VERSION ""

NS_ :

BS_:

BU_: Engine2 Aftertreatment_1_GasOutlet BrakesSystemController Transmission1 Engine1

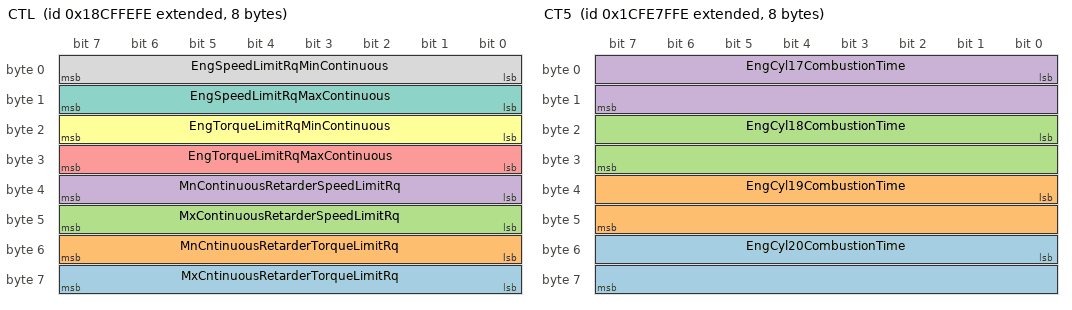
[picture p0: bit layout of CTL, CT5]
BO_ 2563768062 CTL: 8 Vector__XXX
 SG_ MxCntinuousRetarderTorqueLimitRq : 56|8@1+ (1,-125) [-125|0] "%" Vector__XXX
 SG_ MnCntinuousRetarderTorqueLimitRq : 48|8@1+ (1,-125) [-125|0] "%" Vector__XXX
 SG_ MxContinuousRetarderSpeedLimitRq : 40|8@1+ (32,0) [0|8000] "rpm" Vector__XXX
 SG_ MnContinuousRetarderSpeedLimitRq : 32|8@1+ (32,0) [0|8000] "rpm" Vector__XXX
 SG_ EngTorqueLimitRqMaxContinuous : 24|8@1+ (1,-125) [0|125] "%" Vector__XXX
 SG_ EngTorqueLimitRqMinContinuous : 16|8@1+ (1,-125) [0|125] "%" Vector__XXX
 SG_ EngSpeedLimitRqMaxContinuous : 8|8@1+ (32,0) [0|8000] "rpm" Vector__XXX
 SG_ EngSpeedLimitRqMinContinuous : 0|8@1+ (32,0) [0|8000] "rpm" Vector__XXX

BO_ 2633924862 CT6: 8 Vector__XXX
 SG_ EngAverageCombustionTime : 16|16@1+ (0.01,0) [0|642.55] "ms" Vector__XXX
 SG_ EngDesiredCombustionTime : 0|16@1+ (0.01,0) [0|642.55] "ms" Vector__XXX

BO_ 2633924606 CT5: 8 Vector__XXX
 SG_ EngCyl20CombustionTime : 48|16@1+ (0.01,0) [0|642.55] "ms" Vector__XXX
 SG_ EngCyl19CombustionTime : 32|16@1+ (0.01,0) [0|642.55] "ms" Vector__XXX
 SG_ EngCyl18CombustionTime : 16|16@1+ (0.01,0) [0|642.55] "ms" Vector__XXX
 SG_ EngCyl17CombustionTime : 0|16@1+ (0.01,0) [0|642.55] "ms" Vector__XXX

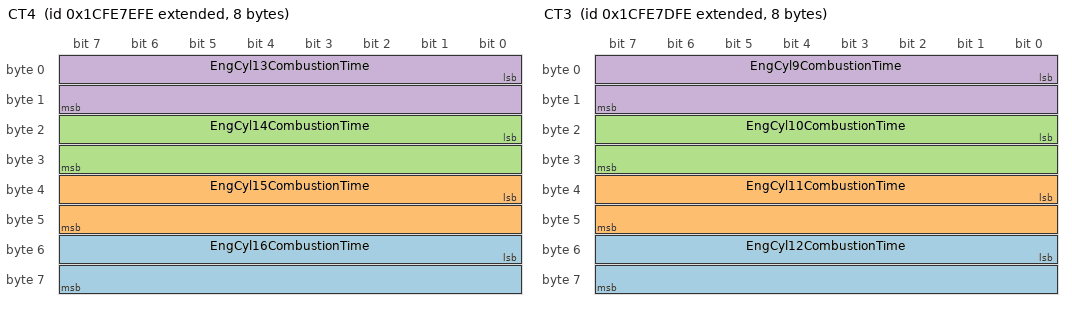
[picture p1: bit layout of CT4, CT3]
BO_ 2633924350 CT4: 8 Vector__XXX
 SG_ EngCyl16CombustionTime : 48|16@1+ (0.01,0) [0|642.55] "ms" Vector__XXX
 SG_ EngCyl15CombustionTime : 32|16@1+ (0.01,0) [0|642.55] "ms" Vector__XXX
 SG_ EngCyl14CombustionTime : 16|16@1+ (0.01,0) [0|642.55] "ms" Vector__XXX
 SG_ EngCyl13CombustionTime : 0|16@1+ (0.01,0) [0|642.55] "ms" Vector__XXX

BO_ 2633924094 CT3: 8 Vector__XXX
 SG_ EngCyl12CombustionTime : 48|16@1+ (0.01,0) [0|642.55] "ms" Vector__XXX
 SG_ EngCyl11CombustionTime : 32|16@1+ (0.01,0) [0|642.55] "ms" Vector__XXX
 SG_ EngCyl10CombustionTime : 16|16@1+ (0.01,0) [0|642.55] "ms" Vector__XXX
 SG_ EngCyl9CombustionTime : 0|16@1+ (0.01,0) [0|642.55] "ms" Vector__XXX

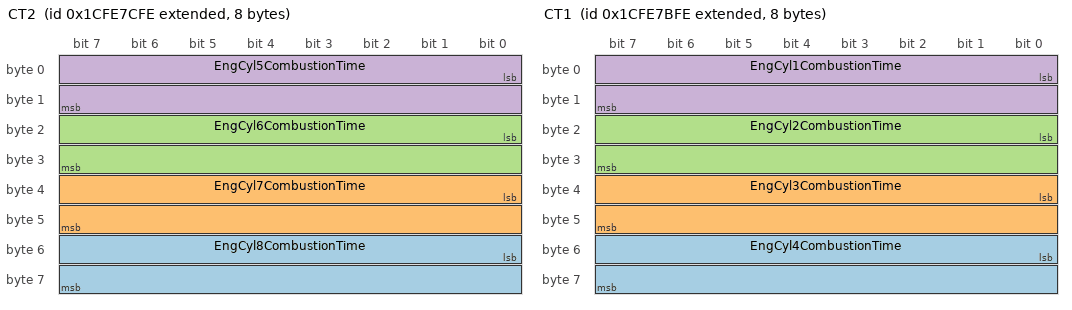
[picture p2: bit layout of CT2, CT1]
BO_ 2633923838 CT2: 8 Vector__XXX
 SG_ EngCyl8CombustionTime : 48|16@1+ (0.01,0) [0|642.55] "ms" Vector__XXX
 SG_ EngCyl7CombustionTime : 32|16@1+ (0.01,0) [0|642.55] "ms" Vector__XXX
 SG_ EngCyl6CombustionTime : 16|16@1+ (0.01,0) [0|642.55] "ms" Vector__XXX
 SG_ EngCyl5CombustionTime : 0|16@1+ (0.01,0) [0|642.55] "ms" Vector__XXX

BO_ 2633923582 CT1: 8 Vector__XXX
 SG_ EngCyl4CombustionTime : 48|16@1+ (0.01,0) [0|642.55] "ms" Vector__XXX
 SG_ EngCyl3CombustionTime : 32|16@1+ (0.01,0) [0|642.55] "ms" Vector__XXX
 SG_ EngCyl2CombustionTime : 16|16@1+ (0.01,0) [0|642.55] "ms" Vector__XXX
 SG_ EngCyl1CombustionTime : 0|16@1+ (0.01,0) [0|642.55] "ms" Vector__XXX

BO_ 2633878014 CMI: 8 Vector__XXX
 SG_ TotalCountOfConfigChangesMade : 0|16@1+ (1,0) [0|64255] "" Vector__XXX

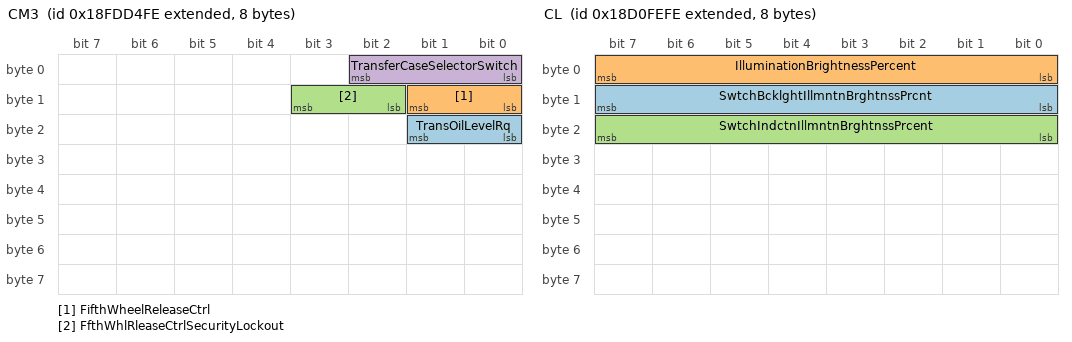
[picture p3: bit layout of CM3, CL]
BO_ 2566771966 CM3: 8 Vector__XXX
 SG_ TransOilLevelRq : 16|2@1+ (1,0) [0|3] "" Vector__XXX
 SG_ FifthWheelReleaseCtrl : 8|2@1+ (1,0) [0|3] "" Vector__XXX
 SG_ FfthWhlRleaseCtrlSecurityLockout : 10|2@1+ (1,0) [0|3] "" Vector__XXX
 SG_ TransferCaseSelectorSwitch : 0|3@1+ (1,0) [0|7] "" Vector__XXX

BO_ 2564882174 CM1: 8 Vector__XXX
 SG_ SelectedMaxVehicleSpeedLimit : 56|8@1+ (1,0) [0|250] "" Vector__XXX
 SG_ RqCabZoneHeating : 54|2@1+ (1,0) [0|3] "" Vector__XXX
 SG_ RqEngZoneHeating : 52|2@1+ (1,0) [0|3] "" Vector__XXX
 SG_ AuxHeaterModeRq : 48|4@1+ (1,0) [0|15] "" Vector__XXX
 SG_ EngAutomaticStartEnableSwitch : 46|2@1+ (1,0) [0|3] "" Vector__XXX
 SG_ AtomaticGearShiftingEnableSwitch : 44|2@1+ (1,0) [0|3] "" Vector__XXX
 SG_ ATRegenerationForceSwitch : 42|2@1+ (1,0) [0|3] "" Vector__XXX
 SG_ ATRegenerationInhibitSwitch : 40|2@1+ (1,0) [0|3] "" Vector__XXX
 SG_ VhclLmtngSpdGovernorEnableSwitch : 38|2@1+ (1,0) [0|3] "" Vector__XXX
 SG_ VhclLmtngSpdGvrnrIncrementSwitch : 36|2@1+ (1,0) [0|3] "" Vector__XXX
 SG_ VhclLmtngSpdGvrnrDecrementSwitch : 34|2@1+ (1,0) [0|3] "" Vector__XXX
 SG_ ParkBrakeCmd : 32|2@1+ (1,0) [0|3] "" Vector__XXX
 SG_ SeatBeltSwitch : 30|2@1+ (1,0) [0|3] "" Vector__XXX
 SG_ OperatorSeatDirectionSwitch : 28|2@1+ (1,0) [0|3] "" Vector__XXX
 SG_ BatteryMainSwitchHoldRq : 26|2@1+ (1,0) [0|3] "" Vector__XXX
 SG_ AuxHeaterCoolantPumpRq : 24|2@1+ (1,0) [0|3] "" Vector__XXX
 SG_ CabInteriorTempCmd : 8|16@1+ (0.03125,-273) [-273|1734.96875] "°C" Vector__XXX
 SG_ RequestedPercentFanSpeed : 0|8@1+ (0.4,0) [0|100] "%" Vector__XXX

BO_ 2563833598 CL: 8 Vector__XXX
 SG_ SwtchBcklghtIllmntnBrghtnssPrcnt : 8|8@1+ (0.4,0) [0|100] "%" Vector__XXX
 SG_ IlluminationBrightnessPercent : 0|8@1+ (0.4,0) [0|100] "%" Vector__XXX
 SG_ SwtchIndctnIllmntnBrghtnssPrcent : 16|8@1+ (0.4,0) [0|100] "%" Vector__XXX

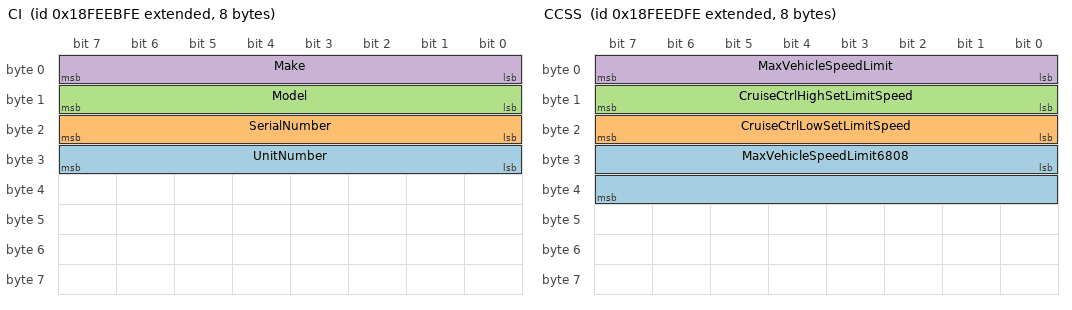
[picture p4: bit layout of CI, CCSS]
BO_ 2566843390 CI: 8 Vector__XXX
 SG_ UnitNumber : 24|8@1+ (1,0) [0|255] "" Vector__XXX
 SG_ SerialNumber : 16|8@1+ (1,0) [0|255] "" Vector__XXX
 SG_ Model : 8|8@1+ (1,0) [0|255] "" Vector__XXX
 SG_ Make : 0|8@1+ (1,0) [0|255] "" Vector__XXX

BO_ 2566844926 CCVS1: 8 Vector__XXX
 SG_ EngShutdownOverrideSwitch : 62|2@1+ (1,0) [0|3] "" Vector__XXX
 SG_ EngTestModeSwitch : 60|2@1+ (1,0) [0|3] "" Vector__XXX
 SG_ EngIdleDecrementSwitch : 58|2@1+ (1,0) [0|3] "" Vector__XXX
 SG_ EngIdleIncrementSwitch : 56|2@1+ (1,0) [0|3] "" Vector__XXX
 SG_ CruiseCtrlStates : 53|3@1+ (1,0) [0|7] "" Vector__XXX
 SG_ PTOGovernorState : 48|5@1+ (1,0) [0|31] "" Vector__XXX
 SG_ CruiseCtrlSetSpeed : 40|8@1+ (1,0) [0|250] "km/h" Vector__XXX
 SG_ CruiseCtrlAccelerateSwitch : 38|2@1+ (1,0) [0|3] "" Vector__XXX
 SG_ CruiseCtrlResumeSwitch : 36|2@1+ (1,0) [0|3] "" Vector__XXX
 SG_ CruiseCtrlCoastSwitch : 34|2@1+ (1,0) [0|3] "" Vector__XXX
 SG_ CruiseCtrlSetSwitch : 32|2@1+ (1,0) [0|3] "" Vector__XXX
 SG_ ClutchSwitch : 30|2@1+ (1,0) [0|3] "" Vector__XXX
 SG_ BrakeSwitch : 28|2@1+ (1,0) [0|3] "" Vector__XXX
 SG_ CruiseCtrlEnableSwitch : 26|2@1+ (1,0) [0|3] "" Vector__XXX
 SG_ CruiseCtrlActive : 24|2@1+ (1,0) [0|3] "" Vector__XXX
 SG_ WheelBasedVehicleSpeed : 8|16@1+ (0.00390625,0) [0|250.996] "km/h" Vector__XXX
 SG_ ParkBrakeReleaseInhibitRq : 6|2@1+ (1,0) [0|3] "" Vector__XXX
 SG_ CruiseCtrlPauseSwitch : 4|2@1+ (1,0) [0|3] "" Vector__XXX
 SG_ ParkingBrakeSwitch : 2|2@1+ (1,0) [0|3] "" Vector__XXX
 SG_ TwoSpeedAxleSwitch : 0|2@1+ (1,0) [0|3] "" Vector__XXX

BO_ 2566843902 CCSS: 8 Vector__XXX
 SG_ MaxVehicleSpeedLimit6808 : 24|16@1+ (0.00390625,0) [0|250.996] "km/h" Vector__XXX
 SG_ CruiseCtrlLowSetLimitSpeed : 16|8@1+ (1,0) [0|250] "km/h" Vector__XXX
 SG_ CruiseCtrlHighSetLimitSpeed : 8|8@1+ (1,0) [0|250] "km/h" Vector__XXX
 SG_ MaxVehicleSpeedLimit : 0|8@1+ (1,0) [0|250] "km/h" Vector__XXX

BO_ 2566809598 CCC: 8 Vector__XXX
 SG_ AuxHeaterMaxOutputPower : 0|16@1+ (2,0) [0|128510] "W" Vector__XXX

BO_ 2633940222 CBI: 16 Vector__XXX
 SG_ TripServiceBrakeApplications : 96|32@1+ (1,0) [0|4211081215] "appl" Vector__XXX
 SG_ TripServiceBrakeDistance : 64|32@1+ (0.125,0) [0|526385151.875] "km" Vector__XXX
 SG_ TripCompressionBrakeDistance : 32|32@1+ (0.125,0) [0|526385151.875] "km" Vector__XXX
 SG_ TotalCompressionBrakeDistance : 0|32@1+ (0.125,0) [0|526385151.875] "km" Vector__XXX

BO_ 2566775294 CACI: 8 Vector__XXX
 SG_ CbA_CRfrgrntCmpressorOutletPress : 0|8@1+ (16,0) [0|4000] "kPa" Vector__XXX

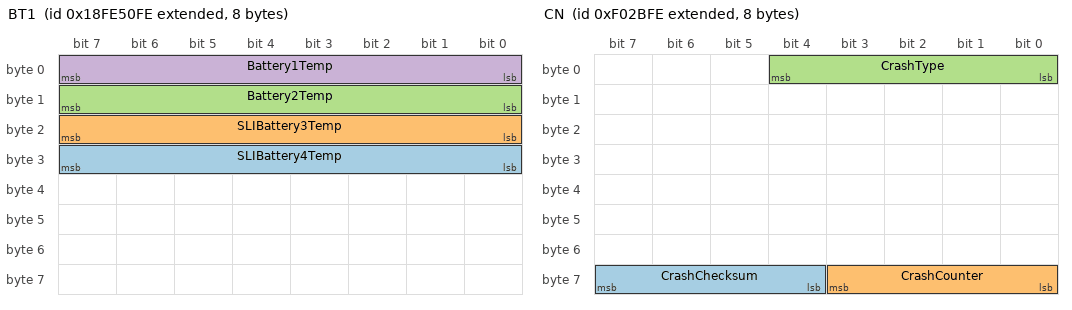
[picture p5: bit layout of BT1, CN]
BO_ 2566803710 BT1: 8 Vector__XXX
 SG_ SLIBattery4Temp : 24|8@1+ (1,-40) [-40|210] "°C" Vector__XXX
 SG_ SLIBattery3Temp : 16|8@1+ (1,-40) [-40|210] "°C" Vector__XXX
 SG_ Battery2Temp : 8|8@1+ (1,-40) [-40|210] "°C" Vector__XXX
 SG_ Battery1Temp : 0|8@1+ (1,-40) [-40|210] "°C" Vector__XXX

BO_ 2566719486 DLCC1: 8 Vector__XXX
 SG_ VhclAccelerationRateLimitLampCmd : 34|2@1+ (1,0) [0|3] "" Vector__XXX
 SG_ EngSpeedVeryHighLampCmd : 32|2@1+ (1,0) [0|3] "" Vector__XXX
 SG_ EngSpeedHighLampCmd : 30|2@1+ (1,0) [0|3] "" Vector__XXX
 SG_ EngCtrlModule3ReadyForUseLampCmd : 28|2@1+ (1,0) [0|3] "" Vector__XXX
 SG_ EngCtrlModule2ReadyForUseLampCmd : 26|2@1+ (1,0) [0|3] "" Vector__XXX
 SG_ EngCtrlModule1ReadyForUseLampCmd : 24|2@1+ (1,0) [0|3] "" Vector__XXX
 SG_ EngFuelFilterRestrictedLampCmd : 22|2@1+ (1,0) [0|3] "" Vector__XXX
 SG_ EngAirFilterRestrictionLampCmd : 20|2@1+ (1,0) [0|3] "" Vector__XXX
 SG_ EngIdleManagementActiveLampCmd : 18|2@1+ (1,0) [0|3] "" Vector__XXX
 SG_ EngCoolantLevelLowLampCmd : 16|2@1+ (1,0) [0|3] "" Vector__XXX
 SG_ EngCoolantTempHighLampCmd : 14|2@1+ (1,0) [0|3] "" Vector__XXX
 SG_ EngOilPressLowLampCmd : 12|2@1+ (1,0) [0|3] "" Vector__XXX
 SG_ CmprssnBrkEnblSwtchIndctrLampCmd : 10|2@1+ (1,0) [0|3] "" Vector__XXX
 SG_ EngBrakeActiveLampCmd : 8|2@1+ (1,0) [0|3] "" Vector__XXX
 SG_ OBDMalfunctionIndicatorLampCmd : 6|2@1+ (1,0) [0|3] "" Vector__XXX
 SG_ EngRedStopLampCmd : 4|2@1+ (1,0) [0|3] "" Vector__XXX
 SG_ EngAmberWarningLampCmd : 2|2@1+ (1,0) [0|3] "" Vector__XXX
 SG_ EngProtectLampCmd : 0|2@1+ (1,0) [0|3] "" Vector__XXX

BO_ 2633832702 CSI: 8 Vector__XXX
 SG_ RolloverSensorType : 64|4@1+ (1,0) [0|15] "" Vector__XXX
 SG_ RearCollisionSensor4Type : 60|4@1+ (1,0) [0|15] "" Vector__XXX
 SG_ RearCollisionSensor3Type : 56|4@1+ (1,0) [0|15] "" Vector__XXX
 SG_ RearCollisionSensor2Type : 52|4@1+ (1,0) [0|15] "" Vector__XXX
 SG_ RearCollisionSensor1Type : 48|4@1+ (1,0) [0|15] "" Vector__XXX
 SG_ SideCollisionSensorRearRightType : 44|4@1+ (1,0) [0|15] "" Vector__XXX
 SG_ SdCllisionSensorMidRearRightType : 40|4@1+ (1,0) [0|15] "" Vector__XXX
 SG_ SdCllsionSensorMidFrontRightType : 36|4@1+ (1,0) [0|15] "" Vector__XXX
 SG_ SdeCollisionSensorFrontRightType : 32|4@1+ (1,0) [0|15] "" Vector__XXX
 SG_ SideCollisionSensorRearLeftType : 28|4@1+ (1,0) [0|15] "" Vector__XXX
 SG_ SdCollisionSensorMidRearLeftType : 24|4@1+ (1,0) [0|15] "" Vector__XXX
 SG_ SdCllisionSensorMidFrontLeftType : 20|4@1+ (1,0) [0|15] "" Vector__XXX
 SG_ SideCollisionSensorFrontLeftType : 16|4@1+ (1,0) [0|15] "" Vector__XXX
 SG_ FrontalCollisionSensor4Type : 12|4@1+ (1,0) [0|15] "" Vector__XXX
 SG_ FrontalCollisionSensor3Type : 8|4@1+ (1,0) [0|15] "" Vector__XXX
 SG_ FrontalCollisionSensor2Type : 4|4@1+ (1,0) [0|15] "" Vector__XXX
 SG_ FrontalCollisionSensor1Type : 0|4@1+ (1,0) [0|15] "" Vector__XXX

BO_ 2163223550 CN: 8 Vector__XXX
 SG_ CrashChecksum : 60|4@1+ (1,0) [0|15] "" Vector__XXX
 SG_ CrashCounter : 56|4@1+ (1,0) [0|15] "" Vector__XXX
 SG_ CrashType : 0|5@1+ (1,0) [0|0] "" Vector__XXX

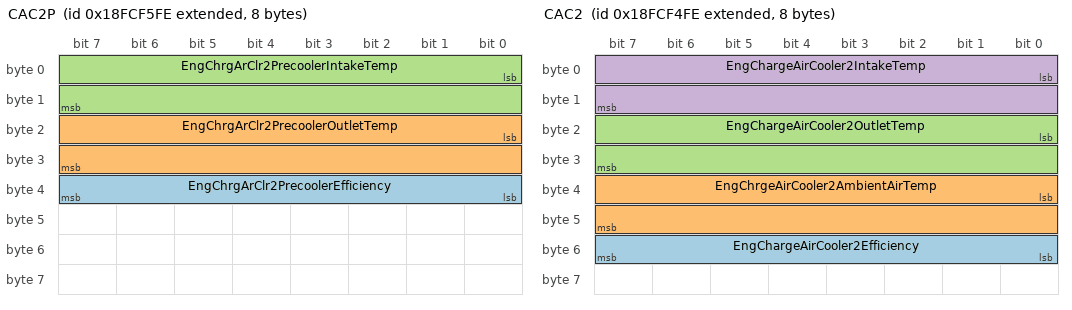
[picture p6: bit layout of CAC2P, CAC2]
BO_ 2566714878 CAC2P: 8 Vector__XXX
 SG_ EngChrgArClr2PrecoolerEfficiency : 32|8@1+ (0.4,0) [0|100] "%" Vector__XXX
 SG_ EngChrgArClr2PrecoolerOutletTemp : 16|16@1+ (0.03125,-273) [-273|1734.96875] "°C" Vector__XXX
 SG_ EngChrgArClr2PrecoolerIntakeTemp : 0|16@1+ (0.03125,-273) [-273|1734.96875] "°C" Vector__XXX

BO_ 2566714622 CAC2: 8 Vector__XXX
 SG_ EngChargeAirCooler2Efficiency : 48|8@1+ (0.4,0) [0|100] "%" Vector__XXX
 SG_ EngChrgeAirCooler2AmbientAirTemp : 32|16@1+ (0.03125,-273) [-273|1734.96875] "°C" Vector__XXX
 SG_ EngChargeAirCooler2OutletTemp : 16|16@1+ (0.03125,-273) [-273|1734.96875] "°C" Vector__XXX
 SG_ EngChargeAirCooler2IntakeTemp : 0|16@1+ (0.03125,-273) [-273|1734.96875] "°C" Vector__XXX

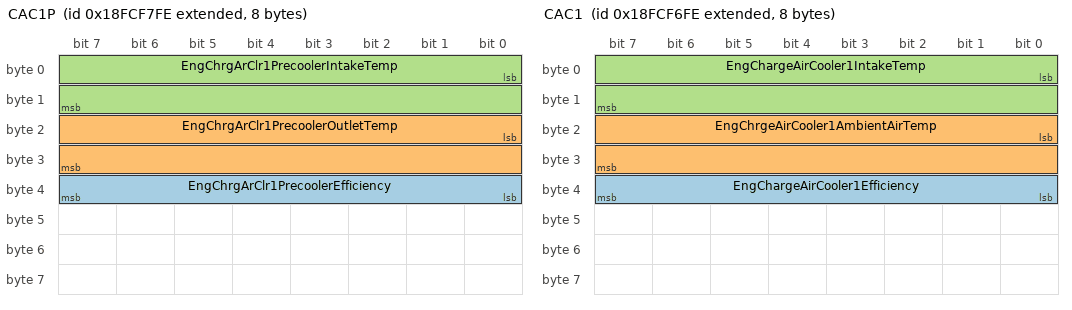
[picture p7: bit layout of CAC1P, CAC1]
BO_ 2566715390 CAC1P: 8 Vector__XXX
 SG_ EngChrgArClr1PrecoolerEfficiency : 32|8@1+ (0.4,0) [0|100] "%" Vector__XXX
 SG_ EngChrgArClr1PrecoolerOutletTemp : 16|16@1+ (0.03125,-273) [-273|1734.96875] "°C" Vector__XXX
 SG_ EngChrgArClr1PrecoolerIntakeTemp : 0|16@1+ (0.03125,-273) [-273|1734.96875] "°C" Vector__XXX

BO_ 2566715134 CAC1: 8 Vector__XXX
 SG_ EngChargeAirCooler1Efficiency : 32|8@1+ (0.4,0) [0|100] "%" Vector__XXX
 SG_ EngChrgeAirCooler1AmbientAirTemp : 16|16@1+ (0.03125,-273) [-273|1734.96875] "°C" Vector__XXX
 SG_ EngChargeAirCooler1IntakeTemp : 0|16@1+ (0.03125,-273) [-273|1734.96875] "°C" Vector__XXX

BO_ 2365400830 BJM9: 8 Vector__XXX
 SG_ Joystick9Button9PressedStatus : 62|2@1+ (1,0) [0|3] "" Vector__XXX
 SG_ Joystick9Button10PressedStatus : 60|2@1+ (1,0) [0|3] "" Vector__XXX
 SG_ Joystick9Button11PressedStatus : 58|2@1+ (1,0) [0|3] "" Vector__XXX
 SG_ Joystick9Button12PressedStatus : 56|2@1+ (1,0) [0|3] "" Vector__XXX
 SG_ Joystick9Button5PressedStatus : 54|2@1+ (1,0) [0|3] "" Vector__XXX
 SG_ Joystick9Button6PressedStatus : 52|2@1+ (1,0) [0|3] "" Vector__XXX
 SG_ Joystick9Button7PressedStatus : 50|2@1+ (1,0) [0|3] "" Vector__XXX
 SG_ Joystick9Button8PressedStatus : 48|2@1+ (1,0) [0|3] "" Vector__XXX
 SG_ Joystick9Button1PressedStatus : 46|2@1+ (1,0) [0|3] "" Vector__XXX
 SG_ Joystick9Button2PressedStatus : 44|2@1+ (1,0) [0|3] "" Vector__XXX
 SG_ Joystick9Button3PressedStatus : 42|2@1+ (1,0) [0|3] "" Vector__XXX
 SG_ Joystick9Button4PressedStatus : 40|2@1+ (1,0) [0|3] "" Vector__XXX
 SG_ Joystick9XAxisDetentPosStatus : 38|2@1+ (1,0) [0|3] "" Vector__XXX
 SG_ Joystick9YAxisDetentPosStatus : 36|2@1+ (1,0) [0|3] "" Vector__XXX
 SG_ Joystick9YAxisPos : 22|10@1+ (0.1,0) [0|102] "%" Vector__XXX
 SG_ Jystck9YAxsLvrFrwrdPstvPosStatus : 20|2@1+ (1,0) [0|3] "" Vector__XXX
 SG_ Jystck9YAxsLvrBckNgtivePosStatus : 18|2@1+ (1,0) [0|3] "" Vector__XXX
 SG_ Joystick9YAxisNeutralPosStatus : 16|2@1+ (1,0) [0|3] "" Vector__XXX
 SG_ Joystick9XAxisPos : 6|10@1+ (0.1,0) [0|102] "%" Vector__XXX
 SG_ Jystck9XAxsLvrRghtPstvePosStatus : 4|2@1+ (1,0) [0|3] "" Vector__XXX
 SG_ Jystck9XAxsLvrLftNgtivePosStatus : 2|2@1+ (1,0) [0|3] "" Vector__XXX
 SG_ Joystick9XAxisNeutralPosStatus : 0|2@1+ (1,0) [0|3] "" Vector__XXX

BO_ 2365401342 BJM8: 8 Vector__XXX
 SG_ Joystick8Button9PressedStatus : 62|2@1+ (1,0) [0|3] "" Vector__XXX
 SG_ Joystick8Button10PressedStatus : 60|2@1+ (1,0) [0|3] "" Vector__XXX
 SG_ Joystick8Button11PressedStatus : 58|2@1+ (1,0) [0|3] "" Vector__XXX
 SG_ Joystick8Button12PressedStatus : 56|2@1+ (1,0) [0|3] "" Vector__XXX
 SG_ Joystick8Button5PressedStatus : 54|2@1+ (1,0) [0|3] "" Vector__XXX
 SG_ Joystick8Button6PressedStatus : 52|2@1+ (1,0) [0|3] "" Vector__XXX
 SG_ Joystick8Button7PressedStatus : 50|2@1+ (1,0) [0|3] "" Vector__XXX
 SG_ Joystick8Button8PressedStatus : 48|2@1+ (1,0) [0|3] "" Vector__XXX
 SG_ Joystick8Button1PressedStatus : 46|2@1+ (1,0) [0|3] "" Vector__XXX
 SG_ Joystick8Button2PressedStatus : 44|2@1+ (1,0) [0|3] "" Vector__XXX
 SG_ Joystick8Button3PressedStatus : 42|2@1+ (1,0) [0|3] "" Vector__XXX
 SG_ Joystick8Button4PressedStatus : 40|2@1+ (1,0) [0|3] "" Vector__XXX
 SG_ Joystick8XAxisDetentPosStatus : 38|2@1+ (1,0) [0|3] "" Vector__XXX
 SG_ Joystick8YAxisDetentPosStatus : 36|2@1+ (1,0) [0|3] "" Vector__XXX
 SG_ Joystick8YAxisPos : 22|10@1+ (0.1,0) [0|102] "%" Vector__XXX
 SG_ Jystck8YAxsLvrFrwrdPstvPosStatus : 20|2@1+ (1,0) [0|3] "" Vector__XXX
 SG_ Jystck8YAxsLvrBckNgtivePosStatus : 18|2@1+ (1,0) [0|3] "" Vector__XXX
 SG_ Joystick8YAxisNeutralPosStatus : 16|2@1+ (1,0) [0|3] "" Vector__XXX
 SG_ Joystick8XAxisPos : 6|10@1+ (0.1,0) [0|102] "%" Vector__XXX
 SG_ Jystck8XAxsLvrRghtPstvePosStatus : 4|2@1+ (1,0) [0|3] "" Vector__XXX
 SG_ Jystck8XAxsLvrLftNgtivePosStatus : 2|2@1+ (1,0) [0|3] "" Vector__XXX
 SG_ Joystick8XAxisNeutralPosStatus : 0|2@1+ (1,0) [0|3] "" Vector__XXX

BO_ 2365401854 BJM7: 8 Vector__XXX
 SG_ Joystick7Button9PressedStatus : 62|2@1+ (1,0) [0|3] "" Vector__XXX
 SG_ Joystick7Button10PressedStatus : 60|2@1+ (1,0) [0|3] "" Vector__XXX
 SG_ Joystick7Button11PressedStatus : 58|2@1+ (1,0) [0|3] "" Vector__XXX
 SG_ Joystick7Button12PressedStatus : 56|2@1+ (1,0) [0|3] "" Vector__XXX
 SG_ Joystick7Button5PressedStatus : 54|2@1+ (1,0) [0|3] "" Vector__XXX
 SG_ Joystick7Button6PressedStatus : 52|2@1+ (1,0) [0|3] "" Vector__XXX
 SG_ Joystick7Button7PressedStatus : 50|2@1+ (1,0) [0|3] "" Vector__XXX
 SG_ Joystick7Button8PressedStatus : 48|2@1+ (1,0) [0|3] "" Vector__XXX
 SG_ Joystick7Button1PressedStatus : 46|2@1+ (1,0) [0|3] "" Vector__XXX
 SG_ Joystick7Button2PressedStatus : 44|2@1+ (1,0) [0|3] "" Vector__XXX
 SG_ Joystick7Button3PressedStatus : 42|2@1+ (1,0) [0|3] "" Vector__XXX
 SG_ Joystick7Button4PressedStatus : 40|2@1+ (1,0) [0|3] "" Vector__XXX
 SG_ Joystick7XAxisDetentPosStatus : 38|2@1+ (1,0) [0|3] "" Vector__XXX
 SG_ Joystick7YAxisDetentPosStatus : 36|2@1+ (1,0) [0|3] "" Vector__XXX
 SG_ Joystick7YAxisPos : 22|10@1+ (0.1,0) [0|102] "%" Vector__XXX
 SG_ Jystck7YAxsLvrFrwrdPstvPosStatus : 20|2@1+ (1,0) [0|3] "" Vector__XXX
 SG_ Jystck7YAxsLvrBckNgtivePosStatus : 18|2@1+ (1,0) [0|3] "" Vector__XXX
 SG_ Joystick7YAxisNeutralPosStatus : 16|2@1+ (1,0) [0|3] "" Vector__XXX
 SG_ Joystick7XAxisPos : 6|10@1+ (0.1,0) [0|102] "%" Vector__XXX
 SG_ Jystck7XAxsLvrRghtPstvePosStatus : 4|2@1+ (1,0) [0|3] "" Vector__XXX
 SG_ Jystck7XAxsLvrLftNgtivePosStatus : 2|2@1+ (1,0) [0|3] "" Vector__XXX
 SG_ Joystick7XAxisNeutralPosStatus : 0|2@1+ (1,0) [0|3] "" Vector__XXX

BO_ 2365402366 BJM6: 8 Vector__XXX
 SG_ Joystick6Button9PressedStatus : 62|2@1+ (1,0) [0|3] "" Vector__XXX
 SG_ Joystick6Button10PressedStatus : 60|2@1+ (1,0) [0|3] "" Vector__XXX
 SG_ Joystick6Button11PressedStatus : 58|2@1+ (1,0) [0|3] "" Vector__XXX
 SG_ Joystick6Button12PressedStatus : 56|2@1+ (1,0) [0|3] "" Vector__XXX
 SG_ Joystick6Button5PressedStatus : 54|2@1+ (1,0) [0|3] "" Vector__XXX
 SG_ Joystick6Button6PressedStatus : 52|2@1+ (1,0) [0|3] "" Vector__XXX
 SG_ Joystick6Button7PressedStatus : 50|2@1+ (1,0) [0|3] "" Vector__XXX
 SG_ Joystick6Button8PressedStatus : 48|2@1+ (1,0) [0|3] "" Vector__XXX
 SG_ Joystick6Button1PressedStatus : 46|2@1+ (1,0) [0|3] "" Vector__XXX
 SG_ Joystick6Button2PressedStatus : 44|2@1+ (1,0) [0|3] "" Vector__XXX
 SG_ Joystick6Button3PressedStatus : 42|2@1+ (1,0) [0|3] "" Vector__XXX
 SG_ Joystick6Button4PressedStatus : 40|2@1+ (1,0) [0|3] "" Vector__XXX
 SG_ Joystick6XAxisDetentPosStatus : 38|2@1+ (1,0) [0|3] "" Vector__XXX
 SG_ Joystick6YAxisDetentPosStatus : 36|2@1+ (1,0) [0|3] "" Vector__XXX
 SG_ Joystick6YAxisPos : 22|10@1+ (0.1,0) [0|102] "%" Vector__XXX
 SG_ Jystck6YAxsLvrFrwrdPstvPosStatus : 20|2@1+ (1,0) [0|3] "" Vector__XXX
 SG_ Jystck6YAxsLvrBckNgtivePosStatus : 18|2@1+ (1,0) [0|3] "" Vector__XXX
 SG_ Joystick6YAxisNeutralPosStatus : 16|2@1+ (1,0) [0|3] "" Vector__XXX
 SG_ Joystick6XAxisPos : 6|10@1+ (0.1,0) [0|102] "%" Vector__XXX
 SG_ Jystck6XAxsLvrRghtPstvePosStatus : 4|2@1+ (1,0) [0|3] "" Vector__XXX
 SG_ Jystck6XAxsLvrLftNgtivePosStatus : 2|2@1+ (1,0) [0|3] "" Vector__XXX
 SG_ Joystick6XAxisNeutralPosStatus : 0|2@1+ (1,0) [0|3] "" Vector__XXX

BO_ 2365402878 BJM5: 8 Vector__XXX
 SG_ Joystick5Button9PressedStatus : 62|2@1+ (1,0) [0|3] "" Vector__XXX
 SG_ Joystick5Button10PressedStatus : 60|2@1+ (1,0) [0|3] "" Vector__XXX
 SG_ Joystick5Button11PressedStatus : 58|2@1+ (1,0) [0|3] "" Vector__XXX
 SG_ Joystick5Button12PressedStatus : 56|2@1+ (1,0) [0|3] "" Vector__XXX
 SG_ Joystick5Button5PressedStatus : 54|2@1+ (1,0) [0|3] "" Vector__XXX
 SG_ Joystick5Button6PressedStatus : 52|2@1+ (1,0) [0|3] "" Vector__XXX
 SG_ Joystick5Button7PressedStatus : 50|2@1+ (1,0) [0|3] "" Vector__XXX
 SG_ Joystick5Button8PressedStatus : 48|2@1+ (1,0) [0|3] "" Vector__XXX
 SG_ Joystick5Button1PressedStatus : 46|2@1+ (1,0) [0|3] "" Vector__XXX
 SG_ Joystick5Button2PressedStatus : 44|2@1+ (1,0) [0|3] "" Vector__XXX
 SG_ Joystick5Button3PressedStatus : 42|2@1+ (1,0) [0|3] "" Vector__XXX
 SG_ Joystick5Button4PressedStatus : 40|2@1+ (1,0) [0|3] "" Vector__XXX
 SG_ Joystick5XAxisDetentPosStatus : 38|2@1+ (1,0) [0|3] "" Vector__XXX
 SG_ Joystick5YAxisDetentPosStatus : 36|2@1+ (1,0) [0|3] "" Vector__XXX
 SG_ Joystick5YAxisPos : 22|10@1+ (0.1,0) [0|102] "%" Vector__XXX
 SG_ Jystck5YAxsLvrFrwrdPstvPosStatus : 20|2@1+ (1,0) [0|3] "" Vector__XXX
 SG_ Jystck5YAxsLvrBckNgtivePosStatus : 18|2@1+ (1,0) [0|3] "" Vector__XXX
 SG_ Joystick5YAxisNeutralPosStatus : 16|2@1+ (1,0) [0|3] "" Vector__XXX
 SG_ Joystick5XAxisPos : 6|10@1+ (0.1,0) [0|102] "%" Vector__XXX
 SG_ Jystck5XAxsLvrRghtPstvePosStatus : 4|2@1+ (1,0) [0|3] "" Vector__XXX
 SG_ Jystck5XAxsLvrLftNgtivePosStatus : 2|2@1+ (1,0) [0|3] "" Vector__XXX
 SG_ Joystick5XAxisNeutralPosStatus : 0|2@1+ (1,0) [0|3] "" Vector__XXX

BO_ 2365403390 BJM4: 8 Vector__XXX
 SG_ Joystick4Button9PressedStatus : 62|2@1+ (1,0) [0|3] "" Vector__XXX
 SG_ Joystick4Button10PressedStatus : 60|2@1+ (1,0) [0|3] "" Vector__XXX
 SG_ Joystick4Button11PressedStatus : 58|2@1+ (1,0) [0|3] "" Vector__XXX
 SG_ Joystick4Button12PressedStatus : 56|2@1+ (1,0) [0|3] "" Vector__XXX
 SG_ Joystick4Button5PressedStatus : 54|2@1+ (1,0) [0|3] "" Vector__XXX
 SG_ Joystick4Button6PressedStatus : 52|2@1+ (1,0) [0|3] "" Vector__XXX
 SG_ Joystick4Button7PressedStatus : 50|2@1+ (1,0) [0|3] "" Vector__XXX
 SG_ Joystick4Button8PressedStatus : 48|2@1+ (1,0) [0|3] "" Vector__XXX
 SG_ Joystick4Button1PressedStatus : 46|2@1+ (1,0) [0|3] "" Vector__XXX
 SG_ Joystick4Button2PressedStatus : 44|2@1+ (1,0) [0|3] "" Vector__XXX
 SG_ Joystick4Button3PressedStatus : 42|2@1+ (1,0) [0|3] "" Vector__XXX
 SG_ Joystick4Button4PressedStatus : 40|2@1+ (1,0) [0|3] "" Vector__XXX
 SG_ Joystick4XAxisDetentPosStatus : 38|2@1+ (1,0) [0|3] "" Vector__XXX
 SG_ Joystick4YAxisDetentPosStatus : 36|2@1+ (1,0) [0|3] "" Vector__XXX
 SG_ Joystick4YAxisPos : 22|10@1+ (0.1,0) [0|102] "%" Vector__XXX
 SG_ Jystck4YAxsLvrFrwrdPstvPosStatus : 20|2@1+ (1,0) [0|3] "" Vector__XXX
 SG_ Jystck4YAxsLvrBckNgtivePosStatus : 18|2@1+ (1,0) [0|3] "" Vector__XXX
 SG_ Joystick4YAxisNeutralPosStatus : 16|2@1+ (1,0) [0|3] "" Vector__XXX
 SG_ Joystick4XAxisPos : 6|10@1+ (0.1,0) [0|102] "%" Vector__XXX
 SG_ Jystck4XAxsLvrRghtPstvePosStatus : 4|2@1+ (1,0) [0|3] "" Vector__XXX
 SG_ Jystck4XAxsLvrLftNgtivePosStatus : 2|2@1+ (1,0) [0|3] "" Vector__XXX
 SG_ Joystick4XAxisNeutralPosStatus : 0|2@1+ (1,0) [0|3] "" Vector__XXX

BO_ 2365400318 BJM10: 8 Vector__XXX
 SG_ Joystick10Button9PressedStatus : 62|2@1+ (1,0) [0|3] "" Vector__XXX
 SG_ Joystick10Button10PressedStatus : 60|2@1+ (1,0) [0|3] "" Vector__XXX
 SG_ Joystick10Button11PressedStatus : 58|2@1+ (1,0) [0|3] "" Vector__XXX
 SG_ Joystick10Button12PressedStatus : 56|2@1+ (1,0) [0|3] "" Vector__XXX
 SG_ Joystick10Button5PressedStatus : 54|2@1+ (1,0) [0|3] "" Vector__XXX
 SG_ Joystick10Button6PressedStatus : 52|2@1+ (1,0) [0|3] "" Vector__XXX
 SG_ Joystick10Button7PressedStatus : 50|2@1+ (1,0) [0|3] "" Vector__XXX
 SG_ Joystick10Button8PressedStatus : 48|2@1+ (1,0) [0|3] "" Vector__XXX
 SG_ Joystick10Button1PressedStatus : 46|2@1+ (1,0) [0|3] "" Vector__XXX
 SG_ Joystick10Button2PressedStatus : 44|2@1+ (1,0) [0|3] "" Vector__XXX
 SG_ Joystick10Button3PressedStatus : 42|2@1+ (1,0) [0|3] "" Vector__XXX
 SG_ Joystick10Button4PressedStatus : 40|2@1+ (1,0) [0|3] "" Vector__XXX
 SG_ Joystick10XAxisDetentPosStatus : 38|2@1+ (1,0) [0|3] "" Vector__XXX
 SG_ Joystick10YAxisDetentPosStatus : 36|2@1+ (1,0) [0|3] "" Vector__XXX
 SG_ Joystick10YAxisPos : 22|10@1+ (0.1,0) [0|102] "%" Vector__XXX
 SG_ Jystck10YAxsLvrFrwrdPstvPsStatus : 20|2@1+ (1,0) [0|3] "" Vector__XXX
 SG_ Jystck10YAxsLvrBckNgtvePosStatus : 18|2@1+ (1,0) [0|3] "" Vector__XXX
 SG_ Joystick10YAxisNeutralPosStatus : 16|2@1+ (1,0) [0|3] "" Vector__XXX
 SG_ Joystick10XAxisPos : 6|10@1+ (0.1,0) [0|102] "%" Vector__XXX
 SG_ Jystck10XAxsLvrRghtPstvPosStatus : 4|2@1+ (1,0) [0|3] "" Vector__XXX
 SG_ Jystck10XAxsLvrLftNgtvePosStatus : 2|2@1+ (1,0) [0|3] "" Vector__XXX
 SG_ Joystick10XAxisNeutralPosStatus : 0|2@1+ (1,0) [0|3] "" Vector__XXX

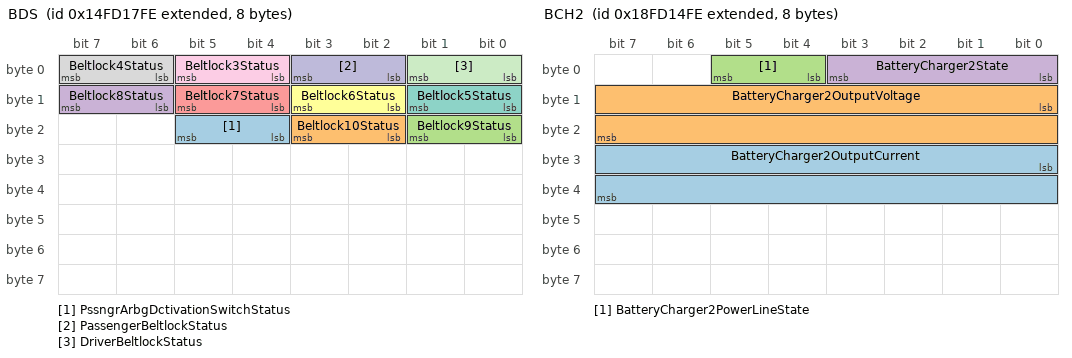
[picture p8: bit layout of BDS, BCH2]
BO_ 2499614718 BDS: 8 Vector__XXX
 SG_ PssngrArbgDctivationSwitchStatus : 20|2@1+ (1,0) [0|3] "" Vector__XXX
 SG_ Beltlock10Status : 18|2@1+ (1,0) [0|3] "" Vector__XXX
 SG_ Beltlock9Status : 16|2@1+ (1,0) [0|3] "" Vector__XXX
 SG_ Beltlock8Status : 14|2@1+ (1,0) [0|3] "" Vector__XXX
 SG_ Beltlock7Status : 12|2@1+ (1,0) [0|3] "" Vector__XXX
 SG_ Beltlock6Status : 10|2@1+ (1,0) [0|3] "" Vector__XXX
 SG_ Beltlock5Status : 8|2@1+ (1,0) [0|3] "" Vector__XXX
 SG_ Beltlock4Status : 6|2@1+ (1,0) [0|3] "" Vector__XXX
 SG_ Beltlock3Status : 4|2@1+ (1,0) [0|3] "" Vector__XXX
 SG_ PassengerBeltlockStatus : 2|2@1+ (1,0) [0|3] "" Vector__XXX
 SG_ DriverBeltlockStatus : 0|2@1+ (1,0) [0|3] "" Vector__XXX

BO_ 2566722814 BCH2: 8 Vector__XXX
 SG_ BatteryCharger2OutputCurrent : 24|16@1+ (0.05,-1600) [-1600|1612.75] "A" Vector__XXX
 SG_ BatteryCharger2OutputVoltage : 8|16@1+ (0.05,0) [0|3212.75] "V" Vector__XXX
 SG_ BatteryCharger2PowerLineState : 4|2@1+ (1,0) [0|3] "" Vector__XXX
 SG_ BatteryCharger2State : 0|4@1+ (1,0) [0|15] "" Vector__XXX

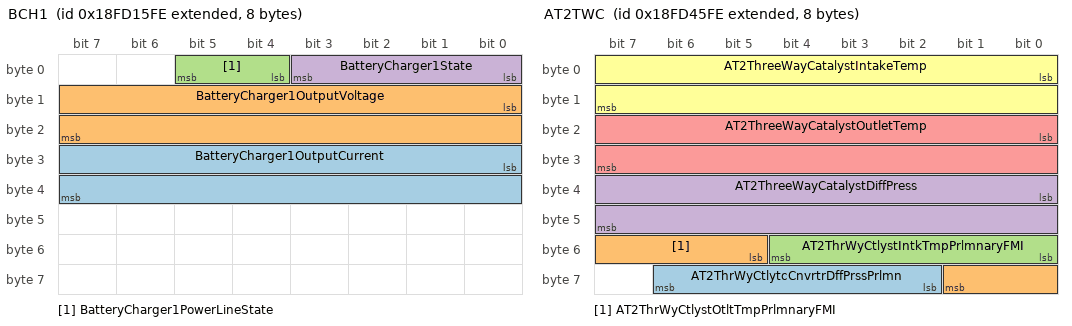
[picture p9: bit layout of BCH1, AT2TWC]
BO_ 2566723070 BCH1: 8 Vector__XXX
 SG_ BatteryCharger1OutputCurrent : 24|16@1+ (0.05,-1600) [-1600|1612.75] "A" Vector__XXX
 SG_ BatteryCharger1OutputVoltage : 8|16@1+ (0.05,0) [0|3212.75] "V" Vector__XXX
 SG_ BatteryCharger1PowerLineState : 4|2@1+ (1,0) [0|3] "" Vector__XXX
 SG_ BatteryCharger1State : 0|4@1+ (1,0) [0|15] "" Vector__XXX

BO_ 2566725118 ATDT2: 8 Vector__XXX
 SG_ AT2ThreeWayCatalystDiffTemp : 16|16@1+ (0.03125,-273) [-273|1734.96875] "°C" Vector__XXX
 SG_ AT1ThreeWayCatalystDiffTemp : 0|16@1+ (0.03125,-273) [-273|1734.96875] "°C" Vector__XXX

BO_ 2566725374 ATDT1: 8 Vector__XXX
 SG_ AT2GasOxidationCatalystDiffTemp : 16|16@1+ (0.03125,-273) [-273|1734.96875] "°C" Vector__XXX
 SG_ AT1GasOxidationCatalystDiffTemp : 0|16@1+ (0.03125,-273) [-273|1734.96875] "°C" Vector__XXX

BO_ 2566712830 AT2WUDOC: 8 Vector__XXX
 SG_ AT2WrmUpDslOxdtnCtlystOutletTemp : 16|16@1+ (0.03125,-273) [-273|1734.96875] "°C" Vector__XXX
 SG_ AT2WrmUpDslOxdtnCtlystIntakeTemp : 0|16@1+ (0.03125,-273) [-273|1734.96875] "°C" Vector__XXX

BO_ 2566735358 AT2TWC: 8 Vector__XXX
 SG_ AT2ThrWyCtlytcCnvrtrDffPrssPrlmn : 58|5@1+ (1,0) [0|31] "" Vector__XXX
 SG_ AT2ThrWyCtlystOtltTmpPrlmnaryFMI : 53|5@1+ (1,0) [0|31] "" Vector__XXX
 SG_ AT2ThrWyCtlystIntkTmpPrlmnaryFMI : 48|5@1+ (1,0) [0|31] "" Vector__XXX
 SG_ AT2ThreeWayCatalystDiffPress : 32|16@1+ (0.1,0) [0|6425.5] "kPa" Vector__XXX
 SG_ AT2ThreeWayCatalystOutletTemp : 16|16@1+ (0.03125,-273) [-273|1734.96875] "°C" Vector__XXX
 SG_ AT2ThreeWayCatalystIntakeTemp : 0|16@1+ (0.03125,-273) [-273|1734.96875] "°C" Vector__XXX

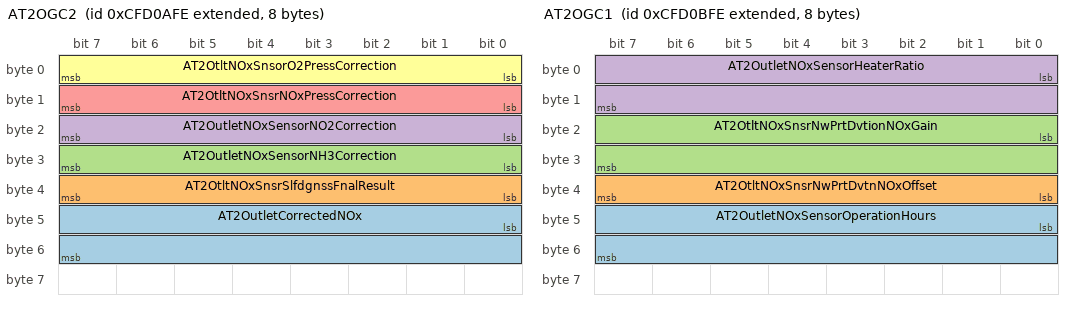
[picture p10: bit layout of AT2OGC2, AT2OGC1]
BO_ 2365393662 AT2OGC2: 8 Vector__XXX
 SG_ AT2OutletCorrectedNOx : 40|16@1+ (0.05,-200) [-200|3012.75] "ppm" Vector__XXX
 SG_ AT2OtltNOxSnsrSlfdgnssFnalResult : 32|8@1+ (1,0) [0|250] "" Vector__XXX
 SG_ AT2OutletNOxSensorNH3Correction : 24|8@1+ (0.5,0) [0|125] "%" Vector__XXX
 SG_ AT2OutletNOxSensorNO2Correction : 16|8@1+ (0.5,0) [0|125] "%" Vector__XXX
 SG_ AT2OtltNOxSnsrNOxPressCorrection : 8|8@1+ (0.5,0) [0|125] "%/bar" Vector__XXX
 SG_ AT2OtltNOxSnsorO2PressCorrection : 0|8@1+ (0.5,0) [0|125] "%/bar" Vector__XXX

BO_ 2365393918 AT2OGC1: 8 Vector__XXX
 SG_ AT2OutletNOxSensorOperationHours : 40|16@1+ (1,0) [0|64255] "h" Vector__XXX
 SG_ AT2OtltNOxSnsrNwPrtDvtnNOxOffset : 32|8@1+ (1,-125) [-125|125] "ppm" Vector__XXX
 SG_ AT2OtltNOxSnsrNwPrtDvtionNOxGain : 16|16@1+ (0.1,-100) [-100|100] "%" Vector__XXX
 SG_ AT2OutletNOxSensorHeaterRatio : 0|16@1+ (0.001,0) [0|64.255] "" Vector__XXX

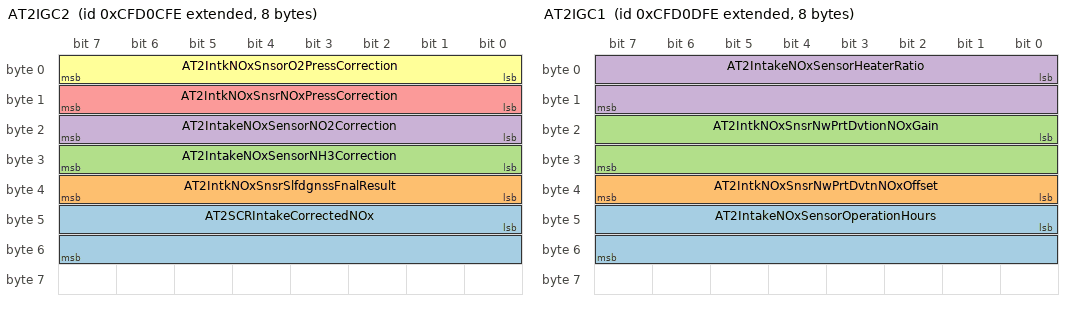
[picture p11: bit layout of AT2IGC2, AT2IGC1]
BO_ 2365394174 AT2IGC2: 8 Vector__XXX
 SG_ AT2SCRIntakeCorrectedNOx : 40|16@1+ (0.05,-200) [-200|3012.75] "ppm" Vector__XXX
 SG_ AT2IntkNOxSnsrSlfdgnssFnalResult : 32|8@1+ (1,0) [0|250] "" Vector__XXX
 SG_ AT2IntakeNOxSensorNH3Correction : 24|8@1+ (0.5,0) [0|125] "%" Vector__XXX
 SG_ AT2IntakeNOxSensorNO2Correction : 16|8@1+ (0.5,0) [0|125] "%" Vector__XXX
 SG_ AT2IntkNOxSnsrNOxPressCorrection : 8|8@1+ (0.5,0) [0|125] "%/bar" Vector__XXX
 SG_ AT2IntkNOxSnsorO2PressCorrection : 0|8@1+ (0.5,0) [0|125] "%/bar" Vector__XXX

BO_ 2365394430 AT2IGC1: 8 Vector__XXX
 SG_ AT2IntakeNOxSensorOperationHours : 40|16@1+ (1,0) [0|64255] "h" Vector__XXX
 SG_ AT2IntkNOxSnsrNwPrtDvtnNOxOffset : 32|8@1+ (1,-125) [-125|125] "ppm" Vector__XXX
 SG_ AT2IntkNOxSnsrNwPrtDvtionNOxGain : 16|16@1+ (0.1,-100) [-100|100] "%" Vector__XXX
 SG_ AT2IntakeNOxSensorHeaterRatio : 0|16@1+ (0.001,0) [0|64.255] "" Vector__XXX

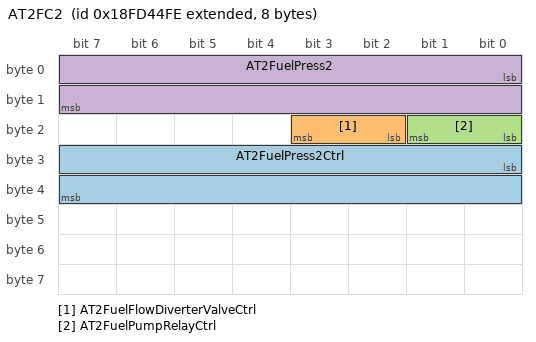
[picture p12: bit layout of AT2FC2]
BO_ 2566735102 AT2FC2: 8 Vector__XXX
 SG_ AT2FuelPress2Ctrl : 24|16@1+ (0.0025,0) [0|160.6375] "%" Vector__XXX
 SG_ AT2FuelFlowDiverterValveCtrl : 18|2@1+ (1,0) [0|3] "" Vector__XXX
 SG_ AT2FuelPumpRelayCtrl : 16|2@1+ (1,0) [0|3] "" Vector__XXX
 SG_ AT2FuelPress2 : 0|16@1+ (0.1,0) [0|6425.5] "kPa" Vector__XXX

BO_ 2157313790 AT2DPFSSC: 8 Vector__XXX
 SG_ AT2DslPrtcltFltrStStndrdDvtnClbO : 16|16@1+ (0.0025,0) [0|160.6375] "%" Vector__XXX
 SG_ AT2DslPrtcltFltrStManCalibOffset : 0|16@1+ (0.0025,0) [0|160.6375] "%" Vector__XXX

BO_ 2566724350 AT1WUDOC: 8 Vector__XXX
 SG_ AT1WrmUpDslOxdtnCtlystOutletTemp : 16|16@1+ (0.03125,-273) [-273|1734.96875] "°C" Vector__XXX
 SG_ AT1WrmUpDslOxdtnCtlystIntakeTemp : 0|16@1+ (0.03125,-273) [-273|1734.96875] "°C" Vector__XXX

CM_ BO_ 2563768062 "Continuous Torque & Speed Limit Request";
CM_ SG_ 2563768062 MxCntinuousRetarderTorqueLimitRq "Requested maximum continuous retarder torque (operating range: -125 to 0%)";
CM_ SG_ 2563768062 MnCntinuousRetarderTorqueLimitRq "Requested minimum continuous retarder torque (operating range: -125 to 0%)";
CM_ SG_ 2563768062 MxContinuousRetarderSpeedLimitRq "Requested maximum continuous retarder speed";
CM_ SG_ 2563768062 MnContinuousRetarderSpeedLimitRq "Requested minimum continuous retarder speed";
CM_ SG_ 2563768062 EngTorqueLimitRqMaxContinuous "Requested maximum continuous engine torque (operating range: 0 to 125%)";
CM_ SG_ 2563768062 EngTorqueLimitRqMinContinuous "Requested minimum continuous engine torque (operating range: 0 to 125%)";
CM_ SG_ 2563768062 EngSpeedLimitRqMaxContinuous "Requested maximum continuous engine speed";
CM_ SG_ 2563768062 EngSpeedLimitRqMinContinuous "Requested minimum continuous engine speed";
CM_ BO_ 2633924862 "Combustion Time 6";
CM_ SG_ 2633924862 EngAverageCombustionTime "The average combustion time of all cylinders of an engine.";
CM_ SG_ 2633924862 EngDesiredCombustionTime "The desired combustion time based upon engine load and speed lookup maps.";
CM_ BO_ 2633924606 "Combustion Time 5";
CM_ SG_ 2633924606 EngCyl20CombustionTime "The amount of time from when the ignition of the fuel is initiated to when the fuel is completely ignited (i.e., the flame front has propagated across the cylinder).";
CM_ SG_ 2633924606 EngCyl19CombustionTime "The amount of time from when the ignition of the fuel is initiated to when the fuel is completely ignited (i.e., the flame front has propagated across the cylinder).";
CM_ SG_ 2633924606 EngCyl18CombustionTime "The amount of time from when the ignition of the fuel is initiated to when the fuel is completely ignited (i.e., the flame front has propagated across the cylinder).";
CM_ SG_ 2633924606 EngCyl17CombustionTime "The amount of time from when the ignition of the fuel is initiated to when the fuel is completely ignited (i.e., the flame front has propagated across the cylinder).";
CM_ BO_ 2633924350 "Combustion Time 4";
CM_ SG_ 2633924350 EngCyl16CombustionTime "The amount of time from when the ignition of the fuel is initiated to when the fuel is completely ignited (i.e., the flame front has propagated across the cylinder).";
CM_ SG_ 2633924350 EngCyl15CombustionTime "The amount of time from when the ignition of the fuel is initiated to when the fuel is completely ignited (i.e., the flame front has propagated across the cylinder).";
CM_ SG_ 2633924350 EngCyl14CombustionTime "The amount of time from when the ignition of the fuel is initiated to when the fuel is completely ignited (i.e., the flame front has propagated across the cylinder).";
CM_ SG_ 2633924350 EngCyl13CombustionTime "The amount of time from when the ignition of the fuel is initiated to when the fuel is completely ignited (i.e., the flame front has propagated across the cylinder).";
CM_ BO_ 2633924094 "Combustion Time 3";
CM_ SG_ 2633924094 EngCyl12CombustionTime "The amount of time from when the ignition of the fuel is initiated to when the fuel is completely ignited (i.e., the flame front has propagated across the cylinder).";
CM_ SG_ 2633924094 EngCyl11CombustionTime "The amount of time from when the ignition of the fuel is initiated to when the fuel is completely ignited (i.e., the flame front has propagated across the cylinder).";
CM_ SG_ 2633924094 EngCyl10CombustionTime "The amount of time from when the ignition of the fuel is initiated to when the fuel is completely ignited (i.e., the flame front has propagated across the cylinder).";
CM_ SG_ 2633924094 EngCyl9CombustionTime "The amount of time from when the ignition of the fuel is initiated to when the fuel is completely ignited (i.e., the flame front has propagated across the cylinder).";
CM_ BO_ 2633923838 "Combustion Time 2";
CM_ SG_ 2633923838 EngCyl8CombustionTime "The amount of time from when the ignition of the fuel is initiated to when the fuel is completely ignited (i.e., the flame front has propagated across the cylinder).";
CM_ SG_ 2633923838 EngCyl7CombustionTime "The amount of time from when the ignition of the fuel is initiated to when the fuel is completely ignited (i.e., the flame front has propagated across the cylinder).";
CM_ SG_ 2633923838 EngCyl6CombustionTime "The amount of time from when the ignition of the fuel is initiated to when the fuel is completely ignited (i.e., the flame front has propagated across the cylinder).";
CM_ SG_ 2633923838 EngCyl5CombustionTime "The amount of time from when the ignition of the fuel is initiated to when the fuel is completely ignited (i.e., the flame front has propagated across the cylinder).";
CM_ BO_ 2633923582 "Combustion Time 1";
CM_ SG_ 2633923582 EngCyl4CombustionTime "The amount of time from when the ignition of the fuel is initiated to when the fuel is completely ignited (i.e., the flame front has propagated across the cylinder).";
CM_ SG_ 2633923582 EngCyl3CombustionTime "The amount of time from when the ignition of the fuel is initiated to when the fuel is completely ignited (i.e., the flame front has propagated across the cylinder).";
CM_ SG_ 2633923582 EngCyl2CombustionTime "The amount of time from when the ignition of the fuel is initiated to when the fuel is completely ignited (i.e., the flame front has propagated across the cylinder).";
CM_ SG_ 2633923582 EngCyl1CombustionTime "The amount of time from when the ignition of the fuel is initiated to when the fuel is completely ignited (i.e., the flame front has propagated across the cylinder).";
CM_ BO_ 2633878014 "Information relating to electronic control modules";
CM_ SG_ 2633878014 TotalCountOfConfigChangesMade "Total number of times changes have been made to any of the configurable parameters.";
CM_ BO_ 2566771966 "Provides information from Cab mounted operator inputs.";
CM_ SG_ 2566771966 TransOilLevelRq "Conveys operator or vehicle system desire for a transmission oil level reading to be taken. 

00 - No transmission oil level reading desired
01 - Transmission oil level reading desired
10 - Reserved
11 - Don't care / take no action";
CM_ SG_ 2566771966 FifthWheelReleaseCtrl "Operator input used to release the fifth wheel. Fifth Wheel Release Control Security Lockout and other conditions must be properly enabled before this will function.
00   Coupler Locked
01   Coupler Unlocked, trailer can be unhitched or hitched
 ...";
CM_ SG_ 2566771966 FfthWhlRleaseCtrlSecurityLockout "Operator's fifth wheel release control interlock. This operator input must be enabled prior to activating the fifth wheel release control (SPN 3314).
00    Fifth wheel release Disabled
01    Fifth wheel release Enabled
10    Error
11    Not ...";
CM_ SG_ 2566771966 TransferCaseSelectorSwitch "Operator switch to select the condition of the transfer case.  States 000 and 001 should be used if the transfer case only functions to switch between 2-wheel and 4-wheel drive.  If the transfer case includes a High / Low Range function, states 011 ...";
CM_ BO_ 2564882174 "Message containing parameters originating from the vehicle cab.";
CM_ SG_ 2564882174 SelectedMaxVehicleSpeedLimit "User selected maximum vehicle speed.  If one is selected, then this SPN must equal one of the maximum vehicle speeds #1-#7 from PGN 64997 - Maximum Vehicle Speed Limit Status . If different maximum vehicle speed requests are present from different ...";
CM_ SG_ 2564882174 RqCabZoneHeating "Request to activate cab zone heating.

00 Do not heat cab engine zone
01 Heat cab zone
10 Reserved
11 Don't care/take no action";
CM_ SG_ 2564882174 RqEngZoneHeating "Request to activate engine zone heating.

00 Do not heat engine zone
01 Heat engine zone
10 Reserved
11 Don't care/take no action";
CM_ SG_ 2564882174 AuxHeaterModeRq "Request to activate the auxiliary heater.
0000 De-activate auxiliary heater
0001 Off due to ADR per European Regulations for Transport of hazardous materials
0010 Economy mode
0011 Normal mode
0100 Heater pump up-keep
0101-1000 Reserved
 ...";
CM_ SG_ 2564882174 EngAutomaticStartEnableSwitch "Switch signal which enables the idle management system to be enabled. When this system is enabled with the engine in an idle mode and safe operating conditions existing, then the engine may be started or stopped automatically.
00 - Switch in the ...";
CM_ SG_ 2564882174 AtomaticGearShiftingEnableSwitch "Indicates that automated gear shifting is enabled via a switch

    00 = Automated Gear Shifting is disabled
    01 = Automated Gear Shifting is enabled
    10 = Error
    11 = Not available";
CM_ SG_ 2564882174 ATRegenerationForceSwitch "Indicates the state of a switch available to the operator that forces aftertreatment regeneration.
00 not active
01 active
10 error
11 not available
This SPN would be “not active” when aftertreatment regeneration is allowed to occur normally ...";
CM_ SG_ 2564882174 ATRegenerationInhibitSwitch "Indicates the state of a switch available to the operator that inhibits aftertreatment regeneration.
00 not active
01 active
10 error
11 not available
This SPN would be “not active” when aftertreatment regeneration is allowed to occur normally ...";
CM_ SG_ 2564882174 VhclLmtngSpdGovernorEnableSwitch "Switch signal which enables the Vehicle Limiting Speed Governor (VLSG) such that the vehicle speed may be either increased or decreased when the engine is off idle.

00 - Switch disabled
01 - Switched enabled
10 - Error
11 - Not available";
CM_ SG_ 2564882174 VhclLmtngSpdGvrnrIncrementSwitch "Switch signal which increases the Vehicle Limiting Speed Governor (VLSG).

00 - Switch in the off state
01 - Switch in the on state - increase
10 - Error
11 - Not available";
CM_ SG_ 2564882174 VhclLmtngSpdGvrnrDecrementSwitch "Switch signal which decreases the Vehicle Limiting Speed Governor (VLSG).

00 - Switch in the off state
01 - Switch in the on state - decrease
10 - Error
11 - Not available";
CM_ SG_ 2564882174 ParkBrakeCmd "Request by a secondary device to command the Park Brake.  The Park Brake controller should treat this as a request and should apply the Park Brake as determined by the controller.
Feedback of the park brake actuation may utilize SPN 70, SPN 619 or ...";
CM_ SG_ 2564882174 SeatBeltSwitch "State of switch used to determine if Seat Belt is buckled

00 NOT Buckled
01 OK - Seat Belt is buckled
10 Error - Switch state cannot be determined
11 Not Available";
CM_ SG_ 2564882174 OperatorSeatDirectionSwitch "Senses whether the operator seat is in the forward driving position

00 Operator seat not facing forward
01 Operator seat is facing forward
10 Error
11 Not Available";
CM_ SG_ 2564882174 BatteryMainSwitchHoldRq "Request to hold the battery main switch.

00 Release Battery Main Switch
01 Hold Battery Main Switch
10 undefined
11 Don't care/take no action";
CM_ SG_ 2564882174 AuxHeaterCoolantPumpRq "Indicates whether to activate the auxiliary heater coolant water pump.

00 Deactivate water pump
01 Activate water pump
10 Reserved
11 Don't care/take no action";
CM_ SG_ 2564882174 CabInteriorTempCmd "Parameter used to command a certain cab interior temperature.

Note: See also SPN 170.  SPN 1662 is an additional diagnostic SPN associated with cab temperature.";
CM_ SG_ 2564882174 RequestedPercentFanSpeed "Fan speed of the first or only fan in the system as a ratio of the actual fan drive (current speed) to the fully engaged fan drive (maximum fan speed). A two state fan (off/on) will use 0% and 100% respectively. A three state fan ...";
CM_ BO_ 2563833598 "This message contains information that controls illumination devices inside the vehicle's cab.";
CM_ SG_ 2563833598 SwtchBcklghtIllmntnBrghtnssPrcnt "Commanded switch backlight brightness level for all operator control switches.  This is separate from the cab display illumination Brightness Percent parameter.
Note:  If a single device is used to control both the backlight brightness level of the ...";
CM_ SG_ 2563833598 IlluminationBrightnessPercent "Commanded backlight brightness level for all cab displays.  

Note:  If a separate device is used to independently control the switch backlight brightness level, see SPN 5532.";
CM_ SG_ 2563833598 SwtchIndctnIllmntnBrghtnssPrcent "Commanded switch indication illumination brightness level for all operator control switches. This is separate from the cab display illumination Brightness Percent parameter.
Note: If a single device is used to control both the indication brightness ...";
CM_ BO_ 2566843390 "NOTE - The make, model, serial number and unit number fields in this message are optional and separated by an ASCII “*”.  It is not necessary to include all fields; however, the delimiter (“*”) is always required.
Field:
a Make
Delimiter (ASCII ...";
CM_ SG_ 2566843390 UnitNumber "Owner assigned unit number for the power unit of the vehicle.

NOTE: The ASCII character \"*\" is reserved as a delimiter.";
CM_ SG_ 2566843390 SerialNumber "Serial number of the component.

NOTE - The ASCII character \"*\" is reserved as a delimiter.";
CM_ SG_ 2566843390 Model "Model of the component.

NOTE - The ASCII character \"*\" is reserved as a delimiter.";
CM_ SG_ 2566843390 Make "Make of the component corresponding to the codes defined in the American Trucking Association Vehicle Maintenance Reporting Standard (ATA/VMRS).
Note:  This parameter is to be transmitted as a 5 character ASCII string;  as a zero length string, if ...";
CM_ BO_ 2566844926 "Cruise Control/Vehicle Speed 1";
CM_ SG_ 2566844926 EngShutdownOverrideSwitch "Switch signal which indicates the position of the engine shutdown override switch.  This switch function allows the operator to override an impending engine shutdown.

00 - Off
01 - On
10 - Error
11 - Not available";
CM_ SG_ 2566844926 EngTestModeSwitch "Switch signal which indicates the position of the engine diagnostic test mode switch.

00 - Off
01 - On
10 - Error
11 - Not available";
CM_ SG_ 2566844926 EngIdleDecrementSwitch "Switch signal which indicates the position of the idle decrement switch.

00 - Off
01 - On
10 - Error
11 - Not available";
CM_ SG_ 2566844926 EngIdleIncrementSwitch "Switch signal which indicates the position of the idle increment switch.

00 - Off
01 - On
10 - Error
11 - Not available";
CM_ SG_ 2566844926 CruiseCtrlStates "This parameter is used to indicate the current state, or mode, of operation by the cruise control device.  This is a status parameter.
000 - Off/Disabled
001 - Hold
010 - Accelerate
011 - Decelerate
100 - Resume
101 - Set
110 - Accelerator ...";
CM_ SG_ 2566844926 PTOGovernorState "This parameter is used to indicate the current state or mode of operation by the power takeoff (PTO) governor.  In lieu of support for PTO Drive Engagement parameters, this parameter may represent the status of a PTO drive.  The broadcasting device ...";
CM_ SG_ 2566844926 CruiseCtrlSetSpeed "Value of set (chosen) velocity of velocity control system.  See SPN 6809 for an alternate resolution.
If an algorithm that can modify the cruise control set point exists in the system, such as Predictive Cruise Control or Adaptive Cruise Control, ...";
CM_ SG_ 2566844926 CruiseCtrlAccelerateSwitch "Switch signal of the cruise control activator which indicates that the activator is in the position “accelerate.”
00 - Cruise control activator not in the position “accelerate”
01 - Cruise control activator in position “accelerate”
10 - Error
11 ...";
CM_ SG_ 2566844926 CruiseCtrlResumeSwitch "Switch signal of the cruise control activator which indicates that the activator is in the position “resume.”
00 - Cruise control activator not in the position “resume”
01 - Cruise control activator in position “resume”
10 - Error
11 - Not ...";
CM_ SG_ 2566844926 CruiseCtrlCoastSwitch "Switch signal of the cruise control activator which indicates that the activator is in the position “coast (decelerate).”
00 - Cruise control activator not in the position “coast”
01 - Cruise control activator in position “coast”
10 - Error
11 - ...";
CM_ SG_ 2566844926 CruiseCtrlSetSwitch "Switch signal of the cruise control activator which indicates that the activator is in the position “set.”

00 - Cruise control activator not in the position “set”
01 - Cruise control activator in position “set”
10 - Error
11 - Not available";
CM_ SG_ 2566844926 ClutchSwitch "Switch signal which indicates that the clutch pedal is being pressed. It is necessary for a safe drivetrain behavior that the clutch switch is set before the clutch is opened (cruise control function).
00 - Clutch pedal released
01 - Clutch pedal ...";
CM_ SG_ 2566844926 BrakeSwitch "Switch signal which indicates that the driver operated brake foot pedal is being pressed.  This brake foot pedal is controlling the vehicles’ service brake (total vehicle braking application, not park brakes).  It is necessary for safe drivetrain ...";
CM_ SG_ 2566844926 CruiseCtrlEnableSwitch "Switch signal which indicates that it is possible to manage the cruise control function.

00 - Cruise control disabled
01 - Cruise control enabled
10 - Error
11 - Not available";
CM_ SG_ 2566844926 CruiseCtrlActive "Cruise control is switched on.  It is not ensured that the engine is controlled by cruise control, as in the case of a large driver's demand the engine is controlled by the driver while cruise control is active (maximum selection of cruise control ...";
CM_ SG_ 2566844926 WheelBasedVehicleSpeed "Speed of the vehicle as calculated from wheel or tailshaft speed.";
CM_ SG_ 2566844926 ParkBrakeReleaseInhibitRq "Park Brake Release Inhibit Request signals the desire that an applied park brake remain applied and limit the ability of the vehicle to be moved.
00 - Park Brake Release Inhibit not requested
01 - Park Brake Release Inhibit requested
10 - SAE ...";
CM_ SG_ 2566844926 CruiseCtrlPauseSwitch "Switch signal which indicates the position of the Cruise Control Pause Switch used on Remote Cruise Control applications. The Cruise Control Pause Switch signal temporarily disables the Cruise Control function.
00 - Off
01 - On
10 - Error ...";
CM_ SG_ 2566844926 ParkingBrakeSwitch "Switch signal which indicates when the parking brake is set. In general the switch actuated by the operator's park brake control, whether a pedal, lever or other control mechanism  (see also SPN 619 and 5275).
00 - Parking brake not set
01 - ...";
CM_ SG_ 2566844926 TwoSpeedAxleSwitch "Switch signal which indicates the current axle range.

00 - Low speed range
01 - High speed range
10 - Error
11 - Not available";
CM_ BO_ 2566843902 "Cruise Control/Vehicle Speed Setup";
CM_ SG_ 2566843902 MaxVehicleSpeedLimit6808 "Maximum vehicle velocity allowed. See SPN 74 for an alternate resolution.";
CM_ SG_ 2566843902 CruiseCtrlLowSetLimitSpeed "Minimum vehicle velocity at which cruise can be set or minimum vehicle velocity for cruise operation before it will exit cruise control operation.";
CM_ SG_ 2566843902 CruiseCtrlHighSetLimitSpeed "Maximum vehicle velocity at which cruise can be set.

If Cruise Control Adjusted Maximum Speed (SPN 7495) is supported, then SPN 7495 has priority over SPN 87. See the definition for SPN 7495 for more details.";
CM_ SG_ 2566843902 MaxVehicleSpeedLimit "Maximum vehicle velocity allowed.   See SPN 6808 for an alternate resolution.";
CM_ BO_ 2566809598 "Climate Control Configuration";
CM_ SG_ 2566809598 AuxHeaterMaxOutputPower "The maximum output power of the auxiliary heater.";
CM_ BO_ 2633940222 "Compression/Service Brake Information";
CM_ SG_ 2633940222 TripServiceBrakeApplications "Total number of times the service brakes have been activated since the last trip reset.  Brake applications of less than 0.5 s are not counted and lengthy brake applications (longer than 0.5 s) are counted as a single event.
NOTE - Definition and ...";
CM_ SG_ 2633940222 TripServiceBrakeDistance "Total distance over which the service brakes have been active since the last trip reset.";
CM_ SG_ 2633940222 TripCompressionBrakeDistance "Total distance over which the compression brakes have been active since the last trip reset.";
CM_ SG_ 2633940222 TotalCompressionBrakeDistance "Total distance over which the compression brakes have been active for the life of the engine.";
CM_ BO_ 2566775294 "This message contains measurement and condition information from cab air conditioning components.";
CM_ SG_ 2566775294 CbA_CRfrgrntCmpressorOutletPress "This is the gage pressure at the compressor outlet in the cab air conditioning system.";
CM_ BO_ 2566803710 "Contains battery temperature information.";
CM_ SG_ 2566803710 SLIBattery4Temp "Temperature of the battery 4 used for starting the engine, for lighting, and for ignition (SLI). 

The relation to physical location is determined by the equipment manufacturer.";
CM_ SG_ 2566803710 SLIBattery3Temp "Temperature of the battery 3 used for starting the engine, for lighting, and for ignition (SLI). 

The relation to physical location is determined by the equipment manufacturer.";
CM_ SG_ 2566803710 Battery2Temp "Temperature of the battery 2. The relation to physical location is determined by the equipment manufacturer.";
CM_ SG_ 2566803710 Battery1Temp "Temperature of the battery 1 used for starting the engine, for lighting, and for ignition (SLI). 

The relation to physical location is determined by the equipment manufacturer.";
CM_ BO_ 2566719486 "Message that directly controls the driver indicator lamps.  See also PGN 64774 for additional lamps and PGN 64773 for the feedback information about these lamps.
Note: Since this message is direct lamp control, it is required that only one device ...";
CM_ SG_ 2566719486 VhclAccelerationRateLimitLampCmd "Command signal directly controlling the Vehicle Acceleration Rate Limit Lamp.
00 - Lamp Off
01 - Lamp On
10 - Reserved
11 - Not available
NOTE: SPN 2979 is the original parameter used to provide vehicle acceleration rate limit status.  This ...";
CM_ SG_ 2566719486 EngSpeedVeryHighLampCmd "Command signal directly controlling the Engine Speed Very High Warning lamp.

00 - Lamp Off
01 - Lamp On
10 - Reserved
11 - Not available";
CM_ SG_ 2566719486 EngSpeedHighLampCmd "Command signal directly controlling the Engine Speed High Warning lamp.

00 - Lamp Off
01 - Lamp On
10 - Reserved
11 - Not available";
CM_ SG_ 2566719486 EngCtrlModule3ReadyForUseLampCmd "Command signal directly controlling the Engine Control Module 3 Ready for Use Lamp. This lamp is used to indicate whether ECM 3 can control the operation of the engine. In case of a failure in ECM 3, lamp will be turned OFF.
00 - Lamp Off
01 - ...";
CM_ SG_ 2566719486 EngCtrlModule2ReadyForUseLampCmd "Command signal directly controlling the Engine Control Module 2 Ready for Use Lamp. This lamp is used to indicate whether ECM 2 can control the operation of the engine. In case of a failure in ECM 2, lamp will be turned OFF.
00 - Lamp Off
01 - ...";
CM_ SG_ 2566719486 EngCtrlModule1ReadyForUseLampCmd "Command signal directly controlling the Engine Control Module 1 Ready for use Lamp. This lamp is used to indicate whether ECM 1 can control the operation of the engine. In case of a failure in ECM 1, lamp will be turned OFF.
00 - Lamp Off
01 - ...";
CM_ SG_ 2566719486 EngFuelFilterRestrictedLampCmd "Command signal directly controlling the Engine Fuel Filter Restricted Lamp.

00 - Lamp Off
01 - Lamp On
10 - Reserved
11 - Not available";
CM_ SG_ 2566719486 EngAirFilterRestrictionLampCmd "Command signal directly controlling the Engine Air Filter Restriction Lamp.

00 - Lamp Off
01 - Lamp On
10 - Reserved
11 - Not available";
CM_ SG_ 2566719486 EngIdleManagementActiveLampCmd "Command signal directly controlling the Engine Idle Management Active Lamp

00 - Lamp Off
01 - Lamp On
10 - Reserved
11 - Not available

Note:  SPN 1661 should be used for reporting diagnostics of the Engine Idle Management Active Lamp.";
CM_ SG_ 2566719486 EngCoolantLevelLowLampCmd "Command signal directly controlling the Engine Coolant Level Low Lamp

00 - Lamp Off
01 - Lamp On
10 - Reserved
11 - Not available";
CM_ SG_ 2566719486 EngCoolantTempHighLampCmd "Command signal directly controlling the Engine Coolant Temperature High Lamp

00 - Lamp Off
01 - Lamp On
10 - Reserved
11 - Not available";
CM_ SG_ 2566719486 EngOilPressLowLampCmd "Command signal directly controlling the Engine Oil Pressure Low Lamp

00 - Lamp Off
01 - Lamp On
10 - Reserved
11 - Not available";
CM_ SG_ 2566719486 CmprssnBrkEnblSwtchIndctrLampCmd "Command signal directly controlling Compression Brake Enable Switch Indicator Lamp.  The compression brake switch indicator signals the status of the compression brake enable switch to the operator.
00 - Lamp OFF
01 - Lamp ON
10 - Reserved
11 - ...";
CM_ SG_ 2566719486 EngBrakeActiveLampCmd "Command signal directly controlling the Engine Brake Active Lamp

00 - Lamp Off
01 - Lamp On
10 - Reserved
11 - Not available";
CM_ SG_ 2566719486 OBDMalfunctionIndicatorLampCmd "Command signal directly controlling the OBD Malfunction Indicator Lamp

00 - Lamp Off
01 - Lamp On
10 - Reserved
11 - Not available

Note:  SPN 1213 should be used for reporting diagnostics of the OBD Malfunction Indicator Lamp.";
CM_ SG_ 2566719486 EngRedStopLampCmd "Command signal directly controlling the Engine Red Stop Lamp

00 - Lamp Off
01 - Lamp On
10 - Reserved
11 - Not available

Note:  SPN 623 should be used for reporting diagnostics of the Engine Red Stop Lamp.";
CM_ SG_ 2566719486 EngAmberWarningLampCmd "Command signal directly controlling the Engine Amber Warning Lamp

00 - Lamp Off
01 - Lamp On
10 - Reserved
11 - Not available

Note:  SPN 624 should be used for reporting diagnostics of the Engine Amber Warning Lamp.";
CM_ SG_ 2566719486 EngProtectLampCmd "Command signal directly controlling the Engine Protect Lamp

00 - Lamp Off
01 - Lamp On
10 - Reserved
11 - Not available

Note:  SPN 987 should be used for reporting diagnostics of the Engine Protect Lamp.";
CM_ BO_ 2633832702 "Message containing type and serial number for every sensor of the restraint-system. The Collision Sensor Type is required for all possible sensors, but only the serial numbers of sensors with a type that is different from \"unavailable\" are included ...";
CM_ SG_ 2633832702 RolloverSensorType "Type of Rollover Sensor.
0000 = acceleration sensor
0001 = pressure sensor
0010 = rollrate sensor
0011 = sonic sensor
0100 = fiber-optic sensor
0101 = radar sensor
0110 = lidar sensor
0111 = optical sensor
1000-1101 =  Reserved
1110 = ...";
CM_ SG_ 2633832702 RearCollisionSensor4Type "Type of Rear Collision Sensor 4.
0000 = acceleration sensor
0001 = pressure sensor
0010 = rollrate sensor
0011 = sonic sensor
0100 = fiber-optic sensor
0101 = radar sensor
0110 = lidar sensor
0111 = optical sensor
1000-1101 =  Reserved
 ...";
CM_ SG_ 2633832702 RearCollisionSensor3Type "Type of Rear Collision Sensor 3.
0000 = acceleration sensor
0001 = pressure sensor
0010 = rollrate sensor
0011 = sonic sensor
0100 = fiber-optic sensor
0101 = radar sensor
0110 = lidar sensor
0111 = optical sensor
1000-1101 =  Reserved
 ...";
CM_ SG_ 2633832702 RearCollisionSensor2Type "Type of Rear Collision Sensor 2.
0000 = acceleration sensor
0001 = pressure sensor
0010 = rollrate sensor
0011 = sonic sensor
0100 = fiber-optic sensor
0101 = radar sensor
0110 = lidar sensor
0111 = optical sensor
1000-1101 =  Reserved
 ...";
CM_ SG_ 2633832702 RearCollisionSensor1Type "Type of Rear Collision Sensor 1.
0000 = acceleration sensor
0001 = pressure sensor
0010 = rollrate sensor
0011 = sonic sensor
0100 = fiber-optic sensor
0101 = radar sensor
0110 = lidar sensor
0111 = optical sensor
1000-1101 =  Reserved
 ...";
CM_ SG_ 2633832702 SideCollisionSensorRearRightType "Type of Side Collision Sensor Rear - Right.
0000 = acceleration sensor
0001 = pressure sensor
0010 = rollrate sensor
0011 = sonic sensor
0100 = fiber-optic sensor
0101 = radar sensor
0110 = lidar sensor
0111 = optical sensor
1000-1101 = ...";
CM_ SG_ 2633832702 SdCllisionSensorMidRearRightType "Type of Side Collision Sensor Mid Rear - Right.
0000 = acceleration sensor
0001 = pressure sensor
0010 = rollrate sensor
0011 = sonic sensor
0100 = fiber-optic sensor
0101 = radar sensor
0110 = lidar sensor
0111 = optical sensor
1000-1101 = ...";
CM_ SG_ 2633832702 SdCllsionSensorMidFrontRightType "Type of Side Collision Sensor Mid Front - Right.
0000 = acceleration sensor
0001 = pressure sensor
0010 = rollrate sensor
0011 = sonic sensor
0100 = fiber-optic sensor
0101 = radar sensor
0110 = lidar sensor
0111 = optical sensor
1000-1101 ...";
CM_ SG_ 2633832702 SdeCollisionSensorFrontRightType "Type of Side Collision Sensor Front - Right.
0000 = acceleration sensor
0001 = pressure sensor
0010 = rollrate sensor
0011 = sonic sensor
0100 = fiber-optic sensor
0101 = radar sensor
0110 = lidar sensor
0111 = optical sensor
1000-1101 = ...";
CM_ SG_ 2633832702 SideCollisionSensorRearLeftType "Type of Side Collision Sensor Rear - Left.
0000 = acceleration sensor
0001 = pressure sensor
0010 = rollrate sensor
0011 = sonic sensor
0100 = fiber-optic sensor
0101 = radar sensor
0110 = lidar sensor
0111 = optical sensor
1000-1101 = ...";
CM_ SG_ 2633832702 SdCollisionSensorMidRearLeftType "Type of Side Collision Sensor Mid Rear - Left.
0000 = acceleration sensor
0001 = pressure sensor
0010 = rollrate sensor
0011 = sonic sensor
0100 = fiber-optic sensor
0101 = radar sensor
0110 = lidar sensor
0111 = optical sensor
1000-1101 = ...";
CM_ SG_ 2633832702 SdCllisionSensorMidFrontLeftType "Type of Side Collision Sensor Mid Front - Left.
0000 = acceleration sensor
0001 = pressure sensor
0010 = rollrate sensor
0011 = sonic sensor
0100 = fiber-optic sensor
0101 = radar sensor
0110 = lidar sensor
0111 = optical sensor
1000-1101 = ...";
CM_ SG_ 2633832702 SideCollisionSensorFrontLeftType "Type of Side Collision Sensor Front - Left.
0000 = acceleration sensor
0001 = pressure sensor
0010 = rollrate sensor
0011 = sonic sensor
0100 = fiber-optic sensor
0101 = radar sensor
0110 = lidar sensor
0111 = optical sensor
1000-1101 = ...";
CM_ SG_ 2633832702 FrontalCollisionSensor4Type "Type of Frontal Collision Sensor 4.
0000 = acceleration sensor
0001 = pressure sensor
0010 = rollrate sensor
0011 = sonic sensor
0100 = fiber-optic sensor
0101 = radar sensor
0110 = lidar sensor
0111 = optical sensor
1000-1101 =  Reserved
 ...";
CM_ SG_ 2633832702 FrontalCollisionSensor3Type "Type of Frontal Collision Sensor 3.
0000 = acceleration sensor
0001 = pressure sensor
0010 = rollrate sensor
0011 = sonic sensor
0100 = fiber-optic sensor
0101 = radar sensor
0110 = lidar sensor
0111 = optical sensor
1000-1101 =  Reserved
 ...";
CM_ SG_ 2633832702 FrontalCollisionSensor2Type "Type of Frontal Collision Sensor 2.
0000 = acceleration sensor
0001 = pressure sensor
0010 = rollrate sensor
0011 = sonic sensor
0100 = fiber-optic sensor
0101 = radar sensor
0110 = lidar sensor
0111 = optical sensor
1000-1101 =  Reserved
 ...";
CM_ SG_ 2633832702 FrontalCollisionSensor1Type "Type of Frontal Collision Sensor 1.
0000 = acceleration sensor
0001 = pressure sensor
0010 = rollrate sensor
0011 = sonic sensor
0100 = fiber-optic sensor
0101 = radar sensor
0110 = lidar sensor
0111 = optical sensor
1000-1101 =  Reserved
 ...";
CM_ BO_ 2163223550 "This message is transmitted in case of a crash event.
The message contains information about the Crash Type, a Crash Counter and a Checksum. The function of the Crash Counter is to prevent other ECU's from reacting to a faulty transmission of the ...";
CM_ SG_ 2163223550 CrashChecksum "The Crash Checksum is used to verify the signal path from the airbag ECU to other devices in case of a crash.
The 4 bit checksum is the sum of the high nibble and the low nibble of the sum of the identifier, the first 7 data bytes and the 4 bit ...";
CM_ SG_ 2163223550 CrashCounter "The Crash Counter prevents other ECUs from reacting to a faulty transmission of the Crash Notification PGN and serves as a safety mechanism. The Crash Counter becomes incremented by 1 for every sent message, starting with \"0\". (0 follows 15)";
CM_ SG_ 2163223550 CrashType "Type of crash event. 

00001 = frontal crash
00010 = rear crash
00100 = side crash (left)
01000 = side crash (right)
10000 = rollover

It is possible to combine different Crash Types. (e.g. frontal and side crash (left) = 00101)";
CM_ BO_ 2566714878 "Engine bank 2 CAC precooler parameters";
CM_ SG_ 2566714878 EngChrgArClr2PrecoolerEfficiency "Engine charge air cooler 2 (CAC2) precooler efficiency is an indication of the precooler’s ability to reduce the temperature of the gas that is being routed through the precooler. 0% = no reduction in temperature, 100% = maximum cooling. The CAC2 ...";
CM_ SG_ 2566714878 EngChrgArClr2PrecoolerOutletTemp "Temperature of the combustion air measured at the charge air cooler 2 precooler outlet.";
CM_ SG_ 2566714878 EngChrgArClr2PrecoolerIntakeTemp "Temperature of the combustion air measured at the charge air cooler 2 precooler Intake.";
CM_ BO_ 2566714622 "Engine bank 2 Charge Air Cooler parameters";
CM_ SG_ 2566714622 EngChargeAirCooler2Efficiency "Engine charge air cooler 2 (CAC2) is an indication of the CAC’s ability to reduce the temperature of the combustion air that is being routed through the CAC. 0% = no reduction in temperature, 100% = maximum cooling. The CAC2 efficiency is calculated ...";
CM_ SG_ 2566714622 EngChrgeAirCooler2AmbientAirTemp "Temperature of the air surrounding charge air cooler 2.";
CM_ SG_ 2566714622 EngChargeAirCooler2OutletTemp "Temperature of combustion air after it exits from the Charge Air Cooler 2 but before any mixing of recirculated exhaust gas.";
CM_ SG_ 2566714622 EngChargeAirCooler2IntakeTemp "Temperature of the combustion air measured at the charge air cooler 2 Intake.";
CM_ BO_ 2566715390 "Engine bank 1 CAC precooler parameters";
CM_ SG_ 2566715390 EngChrgArClr1PrecoolerEfficiency "Engine charge air cooler 1 (CAC1) precooler efficiency is an indication of the precooler’s ability to reduce the temperature of the combustion air that is being routed through the precooler. 0% = no reduction in temperature, 100% = maximum cooling ...";
CM_ SG_ 2566715390 EngChrgArClr1PrecoolerOutletTemp "Temperature of the combustion air measured at the charge air cooler 1 precooler outlet.";
CM_ SG_ 2566715390 EngChrgArClr1PrecoolerIntakeTemp "Temperature of the combustion air measured at the charge air cooler 1 precooler intake.";
CM_ BO_ 2566715134 "Engine bank 1 Charge Air Cooler parameters";
CM_ SG_ 2566715134 EngChargeAirCooler1Efficiency "Engine charge air cooler 1(CAC1) efficiency is an indication of the CAC’s ability to reduce the temperature of the combustion air that is being routed through the CAC1. 0% = no reduction in temperature, 100% = maximum cooling. The CAC1 efficiency is ...";
CM_ SG_ 2566715134 EngChrgeAirCooler1AmbientAirTemp "Temperature of the air surrounding charge air cooler 1.";
CM_ SG_ 2566715134 EngChargeAirCooler1IntakeTemp "Temperature of the combustion air measured at the CAC 1 Intake.";
CM_ BO_ 2365400830 "Used to transfer information about the measured status of the 1st 2 axes and up to 12 buttons of a joystick.  Additional handle information is available in the Expanded Joystick Message.
10-bit position parameters are broadcast over 2 bytes.  The ...";
CM_ SG_ 2365400830 Joystick9Button9PressedStatus "Reports when the joystick button has been pressed.

00 Button not pressed
01 Button pressed
10 Error Indicator
11 Not Available";
CM_ SG_ 2365400830 Joystick9Button10PressedStatus "Reports when the joystick button has been pressed.

00 Button not pressed
01 Button pressed
10 Error Indicator
11 Not Available";
CM_ SG_ 2365400830 Joystick9Button11PressedStatus "Reports when the joystick button has been pressed.

00 Button not pressed
01 Button pressed
10 Error Indicator
11 Not Available";
CM_ SG_ 2365400830 Joystick9Button12PressedStatus "Reports when the joystick button has been pressed.

00 Button not pressed
01 Button pressed
10 Error Indicator
11 Not Available";
CM_ SG_ 2365400830 Joystick9Button5PressedStatus "Reports when the joystick button has been pressed.

00 Button not pressed
01 Button pressed
10 Error Indicator
11 Not Available";
CM_ SG_ 2365400830 Joystick9Button6PressedStatus "Reports when the joystick button has been pressed.

00 Button not pressed
01 Button pressed
10 Error Indicator
11 Not Available";
CM_ SG_ 2365400830 Joystick9Button7PressedStatus "Reports when the joystick button has been pressed.

00 Button not pressed
01 Button pressed
10 Error Indicator
11 Not Available";
CM_ SG_ 2365400830 Joystick9Button8PressedStatus "Reports when the joystick button has been pressed.

00 Button not pressed
01 Button pressed
10 Error Indicator
11 Not Available";
CM_ SG_ 2365400830 Joystick9Button1PressedStatus "Reports when the joystick button has been pressed.

00 Button not pressed
01 Button pressed
10 Error Indicator
11 Not Available";
CM_ SG_ 2365400830 Joystick9Button2PressedStatus "Reports when the joystick button has been pressed.

00 Button not pressed
01 Button pressed
10 Error Indicator
11 Not Available";
CM_ SG_ 2365400830 Joystick9Button3PressedStatus "Reports when the joystick button has been pressed.

00 Button not pressed
01 Button pressed
10 Error Indicator
11 Not Available";
CM_ SG_ 2365400830 Joystick9Button4PressedStatus "Reports when the joystick button has been pressed.

00 Button not pressed
01 Button pressed
10 Error Indicator
11 Not Available";
CM_ SG_ 2365400830 Joystick9XAxisDetentPosStatus "Reports when the current joystick position is in the detent position for that axis of travel.

00 Not in the Detent Position
01 In the Detent Position
10 Error Indicator
11 Not Available";
CM_ SG_ 2365400830 Joystick9YAxisDetentPosStatus "Reports when the current joystick position is in the detent position for that axis of travel.

00 Not in the Detent Position
01 In the Detent Position
10 Error Indicator
11 Not Available";
CM_ SG_ 2365400830 Joystick9YAxisPos "The position of the joystick in the relative motion of travel from the neutral position.  Position value of 0 is Neutral and position value 1000 (100%) is the end of linear zone.  Value of 1022 indicates an error has occurred.";
CM_ SG_ 2365400830 Jystck9YAxsLvrFrwrdPstvPosStatus "Reports when the current joystick position is on the positive travel side (forward, right, clockwise, up) relative to the neutral position for that axis of travel.
00 Not on Positive side of Neutral
01 On positive side of Neutral
10 Error ...";
CM_ SG_ 2365400830 Jystck9YAxsLvrBckNgtivePosStatus "Reports when the current joystick position is on the negative travel side (back, left, counterclockwise, down) relative to the neutral position for that axis of travel.
00 Not on negative side of Neutral
01 On negative side of Neutral
10 Error ...";
CM_ SG_ 2365400830 Joystick9YAxisNeutralPosStatus "Reports when the current joystick position is in the neutral position for that axis of travel.  The neutral position measurement must be determined from some mechanism other than the axis position measurement device.
00 Not in Neutral Position
01 ...";
CM_ SG_ 2365400830 Joystick9XAxisPos "The position of the joystick in the relative motion of travel from the neutral position.  Position value of 0 is Neutral and position value 1000 (100%) is the end of linear zone.  Value of 1022 indicates an error has occurred.";
CM_ SG_ 2365400830 Jystck9XAxsLvrRghtPstvePosStatus "Reports when the current joystick position is on the positive travel side (forward, right, clockwise, up) relative to the neutral position for that axis of travel.
00 Not on Positive side of Neutral
01 On positive side of Neutral
10 Error ...";
CM_ SG_ 2365400830 Jystck9XAxsLvrLftNgtivePosStatus "Reports when the current joystick position is on the negative travel side (back, left, counterclockwise, down) relative to the neutral position for that axis of travel.
00 Not on negative side of Neutral
01 On negative side of Neutral
10 Error ...";
CM_ SG_ 2365400830 Joystick9XAxisNeutralPosStatus "Reports when the current joystick position is in the neutral position for that axis of travel.  The neutral position measurement must be determined from some mechanism other than the axis position measurement device.
00 Not in Neutral Position
01 ...";
CM_ BO_ 2365401342 "Used to transfer information about the measured status of the 1st 2 axes and up to 12 buttons of a joystick.  Additional handle information is available in the Expanded Joystick Message.
10-bit position parameters are broadcast over 2 bytes.  The ...";
CM_ SG_ 2365401342 Joystick8Button9PressedStatus "Reports when the joystick button has been pressed.

00 Button not pressed
01 Button pressed
10 Error Indicator
11 Not Available";
CM_ SG_ 2365401342 Joystick8Button10PressedStatus "Reports when the joystick button has been pressed.

00 Button not pressed
01 Button pressed
10 Error Indicator
11 Not Available";
CM_ SG_ 2365401342 Joystick8Button11PressedStatus "Reports when the joystick button has been pressed.

00 Button not pressed
01 Button pressed
10 Error Indicator
11 Not Available";
CM_ SG_ 2365401342 Joystick8Button12PressedStatus "Reports when the joystick button has been pressed.

00 Button not pressed
01 Button pressed
10 Error Indicator
11 Not Available";
CM_ SG_ 2365401342 Joystick8Button5PressedStatus "Reports when the joystick button has been pressed.

00 Button not pressed
01 Button pressed
10 Error Indicator
11 Not Available";
CM_ SG_ 2365401342 Joystick8Button6PressedStatus "Reports when the joystick button has been pressed.

00 Button not pressed
01 Button pressed
10 Error Indicator
11 Not Available";
CM_ SG_ 2365401342 Joystick8Button7PressedStatus "Reports when the joystick button has been pressed.

00 Button not pressed
01 Button pressed
10 Error Indicator
11 Not Available";
CM_ SG_ 2365401342 Joystick8Button8PressedStatus "Reports when the joystick button has been pressed.

00 Button not pressed
01 Button pressed
10 Error Indicator
11 Not Available";
CM_ SG_ 2365401342 Joystick8Button1PressedStatus "Reports when the joystick button has been pressed.

00 Button not pressed
01 Button pressed
10 Error Indicator
11 Not Available";
CM_ SG_ 2365401342 Joystick8Button2PressedStatus "Reports when the joystick button has been pressed.

00 Button not pressed
01 Button pressed
10 Error Indicator
11 Not Available";
CM_ SG_ 2365401342 Joystick8Button3PressedStatus "Reports when the joystick button has been pressed.

00 Button not pressed
01 Button pressed
10 Error Indicator
11 Not Available";
CM_ SG_ 2365401342 Joystick8Button4PressedStatus "Reports when the joystick button has been pressed.

00 Button not pressed
01 Button pressed
10 Error Indicator
11 Not Available";
CM_ SG_ 2365401342 Joystick8XAxisDetentPosStatus "Reports when the current joystick position is in the detent position for that axis of travel.

00 Not in the Detent Position
01 In the Detent Position
10 Error Indicator
11 Not Available";
CM_ SG_ 2365401342 Joystick8YAxisDetentPosStatus "Reports when the current joystick position is in the detent position for that axis of travel.

00 Not in the Detent Position
01 In the Detent Position
10 Error Indicator
11 Not Available";
CM_ SG_ 2365401342 Joystick8YAxisPos "The position of the joystick in the relative motion of travel from the neutral position.  Position value of 0 is Neutral and position value 1000 (100%) is the end of linear zone.  Value of 1022 indicates an error has occurred.";
CM_ SG_ 2365401342 Jystck8YAxsLvrFrwrdPstvPosStatus "Reports when the current joystick position is on the positive travel side (forward, right, clockwise, up) relative to the neutral position for that axis of travel.
00 Not on Positive side of Neutral
01 On positive side of Neutral
10 Error ...";
CM_ SG_ 2365401342 Jystck8YAxsLvrBckNgtivePosStatus "Reports when the current joystick position is on the negative travel side (back, left, counterclockwise, down) relative to the neutral position for that axis of travel.
00 Not on negative side of Neutral
01 On negative side of Neutral
10 Error ...";
CM_ SG_ 2365401342 Joystick8YAxisNeutralPosStatus "Reports when the current joystick position is in the neutral position for that axis of travel.  The neutral position measurement must be determined from some mechanism other than the axis position measurement device.
00 Not in Neutral Position
01 ...";
CM_ SG_ 2365401342 Joystick8XAxisPos "The position of the joystick in the relative motion of travel from the neutral position.  Position value of 0 is Neutral and position value 1000 (100%) is the end of linear zone.  Value of 1022 indicates an error has occurred.";
CM_ SG_ 2365401342 Jystck8XAxsLvrRghtPstvePosStatus "Reports when the current joystick position is on the positive travel side (forward, right, clockwise, up) relative to the neutral position for that axis of travel.
00 Not on Positive side of Neutral
01 On positive side of Neutral
10 Error ...";
CM_ SG_ 2365401342 Jystck8XAxsLvrLftNgtivePosStatus "Reports when the current joystick position is on the negative travel side (back, left, counterclockwise, down) relative to the neutral position for that axis of travel.
00 Not on negative side of Neutral
01 On negative side of Neutral
10 Error ...";
CM_ SG_ 2365401342 Joystick8XAxisNeutralPosStatus "Reports when the current joystick position is in the neutral position for that axis of travel.  The neutral position measurement must be determined from some mechanism other than the axis position measurement device.
00 Not in Neutral Position
01 ...";
CM_ BO_ 2365401854 "Used to transfer information about the measured status of the 1st 2 axes and up to 12 buttons of a joystick.  Additional handle information is available in the Expanded Joystick Message.
10-bit position parameters are broadcast over 2 bytes.  The ...";
CM_ SG_ 2365401854 Joystick7Button9PressedStatus "Reports when the joystick button has been pressed.

00 Button not pressed
01 Button pressed
10 Error Indicator
11 Not Available";
CM_ SG_ 2365401854 Joystick7Button10PressedStatus "Reports when the joystick button has been pressed.

00 Button not pressed
01 Button pressed
10 Error Indicator
11 Not Available";
CM_ SG_ 2365401854 Joystick7Button11PressedStatus "Reports when the joystick button has been pressed.

00 Button not pressed
01 Button pressed
10 Error Indicator
11 Not Available";
CM_ SG_ 2365401854 Joystick7Button12PressedStatus "Reports when the joystick button has been pressed.

00 Button not pressed
01 Button pressed
10 Error Indicator
11 Not Available";
CM_ SG_ 2365401854 Joystick7Button5PressedStatus "Reports when the joystick button has been pressed.

00 Button not pressed
01 Button pressed
10 Error Indicator
11 Not Available";
CM_ SG_ 2365401854 Joystick7Button6PressedStatus "Reports when the joystick button has been pressed.

00 Button not pressed
01 Button pressed
10 Error Indicator
11 Not Available";
CM_ SG_ 2365401854 Joystick7Button7PressedStatus "Reports when the joystick button has been pressed.

00 Button not pressed
01 Button pressed
10 Error Indicator
11 Not Available";
CM_ SG_ 2365401854 Joystick7Button8PressedStatus "Reports when the joystick button has been pressed.

00 Button not pressed
01 Button pressed
10 Error Indicator
11 Not Available";
CM_ SG_ 2365401854 Joystick7Button1PressedStatus "Reports when the joystick button has been pressed.

00 Button not pressed
01 Button pressed
10 Error Indicator
11 Not Available";
CM_ SG_ 2365401854 Joystick7Button2PressedStatus "Reports when the joystick button has been pressed.

00 Button not pressed
01 Button pressed
10 Error Indicator
11 Not Available";
CM_ SG_ 2365401854 Joystick7Button3PressedStatus "Reports when the joystick button has been pressed.

00 Button not pressed
01 Button pressed
10 Error Indicator
11 Not Available";
CM_ SG_ 2365401854 Joystick7Button4PressedStatus "Reports when the joystick button has been pressed.

00 Button not pressed
01 Button pressed
10 Error Indicator
11 Not Available";
CM_ SG_ 2365401854 Joystick7XAxisDetentPosStatus "Reports when the current joystick position is in the detent position for that axis of travel.

00 Not in the Detent Position
01 In the Detent Position
10 Error Indicator
11 Not Available";
CM_ SG_ 2365401854 Joystick7YAxisDetentPosStatus "Reports when the current joystick position is in the detent position for that axis of travel.

00 Not in the Detent Position
01 In the Detent Position
10 Error Indicator
11 Not Available";
CM_ SG_ 2365401854 Joystick7YAxisPos "The position of the joystick in the relative motion of travel from the neutral position.  Position value of 0 is Neutral and position value 1000 (100%) is the end of linear zone.  Value of 1022 indicates an error has occurred.";
CM_ SG_ 2365401854 Jystck7YAxsLvrFrwrdPstvPosStatus "Reports when the current joystick position is on the positive travel side (forward, right, clockwise, up) relative to the neutral position for that axis of travel.
00 Not on Positive side of Neutral
01 On positive side of Neutral
10 Error ...";
CM_ SG_ 2365401854 Jystck7YAxsLvrBckNgtivePosStatus "Reports when the current joystick position is on the negative travel side (back, left, counterclockwise, down) relative to the neutral position for that axis of travel.
00 Not on negative side of Neutral
01 On negative side of Neutral
10 Error ...";
CM_ SG_ 2365401854 Joystick7YAxisNeutralPosStatus "Reports when the current joystick position is in the neutral position for that axis of travel.  The neutral position measurement must be determined from some mechanism other than the axis position measurement device.
00 Not in Neutral Position
01 ...";
CM_ SG_ 2365401854 Joystick7XAxisPos "The position of the joystick in the relative motion of travel from the neutral position.  Position value of 0 is Neutral and position value 1000 (100%) is the end of linear zone.  Value of 1022 indicates an error has occurred.";
CM_ SG_ 2365401854 Jystck7XAxsLvrRghtPstvePosStatus "Reports when the current joystick position is on the positive travel side (forward, right, clockwise, up) relative to the neutral position for that axis of travel.
00 Not on Positive side of Neutral
01 On positive side of Neutral
10 Error ...";
CM_ SG_ 2365401854 Jystck7XAxsLvrLftNgtivePosStatus "Reports when the current joystick position is on the negative travel side (back, left, counterclockwise, down) relative to the neutral position for that axis of travel.
00 Not on negative side of Neutral
01 On negative side of Neutral
10 Error ...";
CM_ SG_ 2365401854 Joystick7XAxisNeutralPosStatus "Reports when the current joystick position is in the neutral position for that axis of travel.  The neutral position measurement must be determined from some mechanism other than the axis position measurement device.
00 Not in Neutral Position
01 ...";
CM_ BO_ 2365402366 "Used to transfer information about the measured status of the 1st 2 axes and up to 12 buttons of a joystick.  Additional handle information is available in the Expanded Joystick Message.
10-bit position parameters are broadcast over 2 bytes.  The ...";
CM_ SG_ 2365402366 Joystick6Button9PressedStatus "Reports when the joystick button has been pressed.

00 Button not pressed
01 Button pressed
10 Error Indicator
11 Not Available";
CM_ SG_ 2365402366 Joystick6Button10PressedStatus "Reports when the joystick button has been pressed.

00 Button not pressed
01 Button pressed
10 Error Indicator
11 Not Available";
CM_ SG_ 2365402366 Joystick6Button11PressedStatus "Reports when the joystick button has been pressed.

00 Button not pressed
01 Button pressed
10 Error Indicator
11 Not Available";
CM_ SG_ 2365402366 Joystick6Button12PressedStatus "Reports when the joystick button has been pressed.

00 Button not pressed
01 Button pressed
10 Error Indicator
11 Not Available";
CM_ SG_ 2365402366 Joystick6Button5PressedStatus "Reports when the joystick button has been pressed.

00 Button not pressed
01 Button pressed
10 Error Indicator
11 Not Available";
CM_ SG_ 2365402366 Joystick6Button6PressedStatus "Reports when the joystick button has been pressed.

00 Button not pressed
01 Button pressed
10 Error Indicator
11 Not Available";
CM_ SG_ 2365402366 Joystick6Button7PressedStatus "Reports when the joystick button has been pressed.

00 Button not pressed
01 Button pressed
10 Error Indicator
11 Not Available";
CM_ SG_ 2365402366 Joystick6Button8PressedStatus "Reports when the joystick button has been pressed.

00 Button not pressed
01 Button pressed
10 Error Indicator
11 Not Available";
CM_ SG_ 2365402366 Joystick6Button1PressedStatus "Reports when the joystick button has been pressed.

00 Button not pressed
01 Button pressed
10 Error Indicator
11 Not Available";
CM_ SG_ 2365402366 Joystick6Button2PressedStatus "Reports when the joystick button has been pressed.

00 Button not pressed
01 Button pressed
10 Error Indicator
11 Not Available";
CM_ SG_ 2365402366 Joystick6Button3PressedStatus "Reports when the joystick button has been pressed.

00 Button not pressed
01 Button pressed
10 Error Indicator
11 Not Available";
CM_ SG_ 2365402366 Joystick6Button4PressedStatus "Reports when the joystick button has been pressed.

00 Button not pressed
01 Button pressed
10 Error Indicator
11 Not Available";
CM_ SG_ 2365402366 Joystick6XAxisDetentPosStatus "Reports when the current joystick position is in the detent position for that axis of travel.

00 Not in the Detent Position
01 In the Detent Position
10 Error Indicator
11 Not Available";
CM_ SG_ 2365402366 Joystick6YAxisDetentPosStatus "Reports when the current joystick position is in the detent position for that axis of travel.

00 Not in the Detent Position
01 In the Detent Position
10 Error Indicator
11 Not Available";
CM_ SG_ 2365402366 Joystick6YAxisPos "The position of the joystick in the relative motion of travel from the neutral position.  Position value of 0 is Neutral and position value 1000 (100%) is the end of linear zone.  Value of 1022 indicates an error has occurred.";
CM_ SG_ 2365402366 Jystck6YAxsLvrFrwrdPstvPosStatus "Reports when the current joystick position is on the positive travel side (forward, right, clockwise, up) relative to the neutral position for that axis of travel.
00 Not on Positive side of Neutral
01 On positive side of Neutral
10 Error ...";
CM_ SG_ 2365402366 Jystck6YAxsLvrBckNgtivePosStatus "Reports when the current joystick position is on the negative travel side (back, left, counterclockwise, down) relative to the neutral position for that axis of travel.
00 Not on negative side of Neutral
01 On negative side of Neutral
10 Error ...";
CM_ SG_ 2365402366 Joystick6YAxisNeutralPosStatus "Reports when the current joystick position is in the neutral position for that axis of travel.  The neutral position measurement must be determined from some mechanism other than the axis position measurement device.
00 Not in Neutral Position
01 ...";
CM_ SG_ 2365402366 Joystick6XAxisPos "The position of the joystick in the relative motion of travel from the neutral position.  Position value of 0 is Neutral and position value 1000 (100%) is the end of linear zone.  Value of 1022 indicates an error has occurred.";
CM_ SG_ 2365402366 Jystck6XAxsLvrRghtPstvePosStatus "Reports when the current joystick position is on the positive travel side (forward, right, clockwise, up) relative to the neutral position for that axis of travel.
00 Not on Positive side of Neutral
01 On positive side of Neutral
10 Error ...";
CM_ SG_ 2365402366 Jystck6XAxsLvrLftNgtivePosStatus "Reports when the current joystick position is on the negative travel side (back, left, counterclockwise, down) relative to the neutral position for that axis of travel.
00 Not on negative side of Neutral
01 On negative side of Neutral
10 Error ...";
CM_ SG_ 2365402366 Joystick6XAxisNeutralPosStatus "Reports when the current joystick position is in the neutral position for that axis of travel.  The neutral position measurement must be determined from some mechanism other than the axis position measurement device.
00 Not in Neutral Position
01 ...";
CM_ BO_ 2365402878 "Used to transfer information about the measured status of the 1st 2 axes and up to 12 buttons of a joystick.  Additional handle information is available in the Expanded Joystick Message.
10-bit position parameters are broadcast over 2 bytes.  The ...";
CM_ SG_ 2365402878 Joystick5Button9PressedStatus "Reports when the joystick button has been pressed.

00 Button not pressed
01 Button pressed
10 Error Indicator
11 Not Available";
CM_ SG_ 2365402878 Joystick5Button10PressedStatus "Reports when the joystick button has been pressed.

00 Button not pressed
01 Button pressed
10 Error Indicator
11 Not Available";
CM_ SG_ 2365402878 Joystick5Button11PressedStatus "Reports when the joystick button has been pressed.

00 Button not pressed
01 Button pressed
10 Error Indicator
11 Not Available";
CM_ SG_ 2365402878 Joystick5Button12PressedStatus "Reports when the joystick button has been pressed.

00 Button not pressed
01 Button pressed
10 Error Indicator
11 Not Available";
CM_ SG_ 2365402878 Joystick5Button5PressedStatus "Reports when the joystick button has been pressed.

00 Button not pressed
01 Button pressed
10 Error Indicator
11 Not Available";
CM_ SG_ 2365402878 Joystick5Button6PressedStatus "Reports when the joystick button has been pressed.

00 Button not pressed
01 Button pressed
10 Error Indicator
11 Not Available";
CM_ SG_ 2365402878 Joystick5Button7PressedStatus "Reports when the joystick button has been pressed.

00 Button not pressed
01 Button pressed
10 Error Indicator
11 Not Available";
CM_ SG_ 2365402878 Joystick5Button8PressedStatus "Reports when the joystick button has been pressed.

00 Button not pressed
01 Button pressed
10 Error Indicator
11 Not Available";
CM_ SG_ 2365402878 Joystick5Button1PressedStatus "Reports when the joystick button has been pressed.

00 Button not pressed
01 Button pressed
10 Error Indicator
11 Not Available";
CM_ SG_ 2365402878 Joystick5Button2PressedStatus "Reports when the joystick button has been pressed.

00 Button not pressed
01 Button pressed
10 Error Indicator
11 Not Available";
CM_ SG_ 2365402878 Joystick5Button3PressedStatus "Reports when the joystick button has been pressed.

00 Button not pressed
01 Button pressed
10 Error Indicator
11 Not Available";
CM_ SG_ 2365402878 Joystick5Button4PressedStatus "Reports when the joystick button has been pressed.

00 Button not pressed
01 Button pressed
10 Error Indicator
11 Not Available";
CM_ SG_ 2365402878 Joystick5XAxisDetentPosStatus "Reports when the current joystick position is in the detent position for that axis of travel.

00 Not in the Detent Position
01 In the Detent Position
10 Error Indicator
11 Not Available";
CM_ SG_ 2365402878 Joystick5YAxisDetentPosStatus "Reports when the current joystick position is in the detent position for that axis of travel.

00 Not in the Detent Position
01 In the Detent Position
10 Error Indicator
11 Not Available";
CM_ SG_ 2365402878 Joystick5YAxisPos "The position of the joystick in the relative motion of travel from the neutral position.  Position value of 0 is Neutral and position value 1000 (100%) is the end of linear zone.  Value of 1022 indicates an error has occurred.";
CM_ SG_ 2365402878 Jystck5YAxsLvrFrwrdPstvPosStatus "Reports when the current joystick position is on the positive travel side (forward, right, clockwise, up) relative to the neutral position for that axis of travel.
00 Not on Positive side of Neutral
01 On positive side of Neutral
10 Error ...";
CM_ SG_ 2365402878 Jystck5YAxsLvrBckNgtivePosStatus "Reports when the current joystick position is on the negative travel side (back, left, counterclockwise, down) relative to the neutral position for that axis of travel.
00 Not on negative side of Neutral
01 On negative side of Neutral
10 Error ...";
CM_ SG_ 2365402878 Joystick5YAxisNeutralPosStatus "Reports when the current joystick position is in the neutral position for that axis of travel.  The neutral position measurement must be determined from some mechanism other than the axis position measurement device.
00 Not in Neutral Position
01 ...";
CM_ SG_ 2365402878 Joystick5XAxisPos "The position of the joystick in the relative motion of travel from the neutral position.  Position value of 0 is Neutral and position value 1000 (100%) is the end of linear zone.  Value of 1022 indicates an error has occurred.";
CM_ SG_ 2365402878 Jystck5XAxsLvrRghtPstvePosStatus "Reports when the current joystick position is on the positive travel side (forward, right, clockwise, up) relative to the neutral position for that axis of travel.
00 Not on Positive side of Neutral
01 On positive side of Neutral
10 Error ...";
CM_ SG_ 2365402878 Jystck5XAxsLvrLftNgtivePosStatus "Reports when the current joystick position is on the negative travel side (back, left, counterclockwise, down) relative to the neutral position for that axis of travel.
00 Not on negative side of Neutral
01 On negative side of Neutral
10 Error ...";
CM_ SG_ 2365402878 Joystick5XAxisNeutralPosStatus "Reports when the current joystick position is in the neutral position for that axis of travel.  The neutral position measurement must be determined from some mechanism other than the axis position measurement device.
00 Not in Neutral Position
01 ...";
CM_ BO_ 2365403390 "Used to transfer information about the measured status of the 1st 2 axes and up to 12 buttons of a joystick.  Additional handle information is available in the Expanded Joystick Message.
10-bit position parameters are broadcast over 2 bytes.  The ...";
CM_ SG_ 2365403390 Joystick4Button9PressedStatus "Reports when the joystick button has been pressed.

00 Button not pressed
01 Button pressed
10 Error Indicator
11 Not Available";
CM_ SG_ 2365403390 Joystick4Button10PressedStatus "Reports when the joystick button has been pressed.

00 Button not pressed
01 Button pressed
10 Error Indicator
11 Not Available";
CM_ SG_ 2365403390 Joystick4Button11PressedStatus "Reports when the joystick button has been pressed.

00 Button not pressed
01 Button pressed
10 Error Indicator
11 Not Available";
CM_ SG_ 2365403390 Joystick4Button12PressedStatus "Reports when the joystick button has been pressed.

00 Button not pressed
01 Button pressed
10 Error Indicator
11 Not Available";
CM_ SG_ 2365403390 Joystick4Button5PressedStatus "Reports when the joystick button has been pressed.

00 Button not pressed
01 Button pressed
10 Error Indicator
11 Not Available";
CM_ SG_ 2365403390 Joystick4Button6PressedStatus "Reports when the joystick button has been pressed.

00 Button not pressed
01 Button pressed
10 Error Indicator
11 Not Available";
CM_ SG_ 2365403390 Joystick4Button7PressedStatus "Reports when the joystick button has been pressed.

00 Button not pressed
01 Button pressed
10 Error Indicator
11 Not Available";
CM_ SG_ 2365403390 Joystick4Button8PressedStatus "Reports when the joystick button has been pressed.

00 Button not pressed
01 Button pressed
10 Error Indicator
11 Not Available";
CM_ SG_ 2365403390 Joystick4Button1PressedStatus "Reports when the joystick button has been pressed.

00 Button not pressed
01 Button pressed
10 Error Indicator
11 Not Available";
CM_ SG_ 2365403390 Joystick4Button2PressedStatus "Reports when the joystick button has been pressed.

00 Button not pressed
01 Button pressed
10 Error Indicator
11 Not Available";
CM_ SG_ 2365403390 Joystick4Button3PressedStatus "Reports when the joystick button has been pressed.

00 Button not pressed
01 Button pressed
10 Error Indicator
11 Not Available";
CM_ SG_ 2365403390 Joystick4Button4PressedStatus "Reports when the joystick button has been pressed.

00 Button not pressed
01 Button pressed
10 Error Indicator
11 Not Available";
CM_ SG_ 2365403390 Joystick4XAxisDetentPosStatus "Reports when the current joystick position is in the detent position for that axis of travel.

00 Not in the Detent Position
01 In the Detent Position
10 Error Indicator
11 Not Available";
CM_ SG_ 2365403390 Joystick4YAxisDetentPosStatus "Reports when the current joystick position is in the detent position for that axis of travel.

00 Not in the Detent Position
01 In the Detent Position
10 Error Indicator
11 Not Available";
CM_ SG_ 2365403390 Joystick4YAxisPos "The position of the joystick in the relative motion of travel from the neutral position.  Position value of 0 is Neutral and position value 1000 (100%) is the end of linear zone.  Value of 1022 indicates an error has occurred.";
CM_ SG_ 2365403390 Jystck4YAxsLvrFrwrdPstvPosStatus "Reports when the current joystick position is on the positive travel side (forward, right, clockwise, up) relative to the neutral position for that axis of travel.
00 Not on Positive side of Neutral
01 On positive side of Neutral
10 Error ...";
CM_ SG_ 2365403390 Jystck4YAxsLvrBckNgtivePosStatus "Reports when the current joystick position is on the negative travel side (back, left, counterclockwise, down) relative to the neutral position for that axis of travel.
00 Not on negative side of Neutral
01 On negative side of Neutral
10 Error ...";
CM_ SG_ 2365403390 Joystick4YAxisNeutralPosStatus "Reports when the current joystick position is in the neutral position for that axis of travel.  The neutral position measurement must be determined from some mechanism other than the axis position measurement device.
00 Not in Neutral Position
01 ...";
CM_ SG_ 2365403390 Joystick4XAxisPos "The position of the joystick in the relative motion of travel from the neutral position.  Position value of 0 is Neutral and position value 1000 (100%) is the end of linear zone.  Value of 1022 indicates an error has occurred.";
CM_ SG_ 2365403390 Jystck4XAxsLvrRghtPstvePosStatus "Reports when the current joystick position is on the positive travel side (forward, right, clockwise, up) relative to the neutral position for that axis of travel.
00 Not on Positive side of Neutral
01 On positive side of Neutral
10 Error ...";
CM_ SG_ 2365403390 Jystck4XAxsLvrLftNgtivePosStatus "Reports when the current joystick position is on the negative travel side (back, left, counterclockwise, down) relative to the neutral position for that axis of travel.
00 Not on negative side of Neutral
01 On negative side of Neutral
10 Error ...";
CM_ SG_ 2365403390 Joystick4XAxisNeutralPosStatus "Reports when the current joystick position is in the neutral position for that axis of travel.  The neutral position measurement must be determined from some mechanism other than the axis position measurement device.
00 Not in Neutral Position
01 ...";
CM_ BO_ 2365400318 "Used to transfer information about the measured status of the 1st 2 axes and up to 12 buttons of a joystick.  Additional handle information is available in the Expanded Joystick Message.
10-bit position parameters are broadcast over 2 bytes.  The ...";
CM_ SG_ 2365400318 Joystick10Button9PressedStatus "Reports when the joystick button has been pressed.

00 Button not pressed
01 Button pressed
10 Error Indicator
11 Not Available";
CM_ SG_ 2365400318 Joystick10Button10PressedStatus "Reports when the joystick button has been pressed.

00 Button not pressed
01 Button pressed
10 Error Indicator
11 Not Available";
CM_ SG_ 2365400318 Joystick10Button11PressedStatus "Reports when the joystick button has been pressed.

00 Button not pressed
01 Button pressed
10 Error Indicator
11 Not Available";
CM_ SG_ 2365400318 Joystick10Button12PressedStatus "Reports when the joystick button has been pressed.

00 Button not pressed
01 Button pressed
10 Error Indicator
11 Not Available";
CM_ SG_ 2365400318 Joystick10Button5PressedStatus "Reports when the joystick button has been pressed.

00 Button not pressed
01 Button pressed
10 Error Indicator
11 Not Available";
CM_ SG_ 2365400318 Joystick10Button6PressedStatus "Reports when the joystick button has been pressed.

00 Button not pressed
01 Button pressed
10 Error Indicator
11 Not Available";
CM_ SG_ 2365400318 Joystick10Button7PressedStatus "Reports when the joystick button has been pressed.

00 Button not pressed
01 Button pressed
10 Error Indicator
11 Not Available";
CM_ SG_ 2365400318 Joystick10Button8PressedStatus "Reports when the joystick button has been pressed.

00 Button not pressed
01 Button pressed
10 Error Indicator
11 Not Available";
CM_ SG_ 2365400318 Joystick10Button1PressedStatus "Reports when the joystick button has been pressed.

00 Button not pressed
01 Button pressed
10 Error Indicator
11 Not Available";
CM_ SG_ 2365400318 Joystick10Button2PressedStatus "Reports when the joystick button has been pressed.

00 Button not pressed
01 Button pressed
10 Error Indicator
11 Not Available";
CM_ SG_ 2365400318 Joystick10Button3PressedStatus "Reports when the joystick button has been pressed.

00 Button not pressed
01 Button pressed
10 Error Indicator
11 Not Available";
CM_ SG_ 2365400318 Joystick10Button4PressedStatus "Reports when the joystick button has been pressed.

00 Button not pressed
01 Button pressed
10 Error Indicator
11 Not Available";
CM_ SG_ 2365400318 Joystick10XAxisDetentPosStatus "Reports when the current joystick position is in the detent position for that axis of travel.

00 Not in the Detent Position
01 In the Detent Position
10 Error Indicator
11 Not Available";
CM_ SG_ 2365400318 Joystick10YAxisDetentPosStatus "Reports when the current joystick position is in the detent position for that axis of travel.

00 Not in the Detent Position
01 In the Detent Position
10 Error Indicator
11 Not Available";
CM_ SG_ 2365400318 Joystick10YAxisPos "The position of the joystick in the relative motion of travel from the neutral position.  Position value of 0 is Neutral and position value 1000 (100%) is the end of linear zone.  Value of 1022 indicates an error has occurred.";
CM_ SG_ 2365400318 Jystck10YAxsLvrFrwrdPstvPsStatus "Reports when the current joystick position is on the positive travel side (forward, right, clockwise, up) relative to the neutral position for that axis of travel.
00 Not on Positive side of Neutral
01 On positive side of Neutral
10 Error ...";
CM_ SG_ 2365400318 Jystck10YAxsLvrBckNgtvePosStatus "Reports when the current joystick position is on the negative travel side (back, left, counterclockwise, down) relative to the neutral position for that axis of travel.
00 Not on negative side of Neutral
01 On negative side of Neutral
10 Error ...";
CM_ SG_ 2365400318 Joystick10YAxisNeutralPosStatus "Reports when the current joystick position is in the neutral position for that axis of travel.  The neutral position measurement must be determined from some mechanism other than the axis position measurement device.
00 Not in Neutral Position
01 ...";
CM_ SG_ 2365400318 Joystick10XAxisPos "The position of the joystick in the relative motion of travel from the neutral position.  Position value of 0 is Neutral and position value 1000 (100%) is the end of linear zone.  Value of 1022 indicates an error has occurred.";
CM_ SG_ 2365400318 Jystck10XAxsLvrRghtPstvPosStatus "Reports when the current joystick position is on the positive travel side (forward, right, clockwise, up) relative to the neutral position for that axis of travel.
00 Not on Positive side of Neutral
01 On positive side of Neutral
10 Error ...";
CM_ SG_ 2365400318 Jystck10XAxsLvrLftNgtvePosStatus "Reports when the current joystick position is on the negative travel side (back, left, counterclockwise, down) relative to the neutral position for that axis of travel.
00 Not on negative side of Neutral
01 On negative side of Neutral
10 Error ...";
CM_ SG_ 2365400318 Joystick10XAxisNeutralPosStatus "Reports when the current joystick position is in the neutral position for that axis of travel.  The neutral position measurement must be determined from some mechanism other than the axis position measurement device.
00 Not in Neutral Position
01 ...";
CM_ BO_ 2499614718 "Message containing Beltlock States and the Passener Airbag Deactivation Switch State.";
CM_ SG_ 2499614718 PssngrArbgDctivationSwitchStatus "State of switch used to deactivate Passenger Airbag manually.

00 = passenger airbag activated
01 = passenger airbag deactivated
10 = Error - State of deactivation switch cannot be determined
11 = not available";
CM_ SG_ 2499614718 Beltlock10Status "State of switch used to determine if Beltlock 10 is buckled.

00 = unlocked
01 = locked
10 = Error - Beltlock state cannot be determined
11 = not available";
CM_ SG_ 2499614718 Beltlock9Status "State of switch used to determine if Beltlock 9 is buckled.

00 = unlocked
01 = locked
10 = Error - Beltlock state cannot be determined
11 = not available";
CM_ SG_ 2499614718 Beltlock8Status "State of switch used to determine if Beltlock 8 is buckled.

00 = unlocked
01 = locked
10 = Error - Beltlock state cannot be determined
11 = not available";
CM_ SG_ 2499614718 Beltlock7Status "State of switch used to determine if Beltlock 7 is buckled.

00 = unlocked
01 = locked
10 = Error - Beltlock state cannot be determined
11 = not available";
CM_ SG_ 2499614718 Beltlock6Status "State of switch used to determine if Beltlock 6 is buckled.

00 = unlocked
01 = locked
10 = Error - Beltlock state cannot be determined
11 = not available";
CM_ SG_ 2499614718 Beltlock5Status "State of switch used to determine if Beltlock 5 is buckled.

00 = unlocked
01 = locked
10 = Error - Beltlock state cannot be determined
11 = not available";
CM_ SG_ 2499614718 Beltlock4Status "State of switch used to determine if Beltlock 4 is buckled.

00 = unlocked
01 = locked
10 = Error - Beltlock state cannot be determined
11 = not available";
CM_ SG_ 2499614718 Beltlock3Status "State of switch used to determine if Beltlock 3 is buckled.

00 = unlocked
01 = locked
10 = Error - Beltlock state cannot be determined
11 = not available";
CM_ SG_ 2499614718 PassengerBeltlockStatus "State of switch used to determine if Passenger Beltlock is buckled.

00 = unlocked
01 = locked
10 = Error - Beltlock state cannot be determined
11 = not available";
CM_ SG_ 2499614718 DriverBeltlockStatus "State of switch used to determine if Driver Beltlock is buckled.

00 = unlocked
01 = locked
10 = Error - Beltlock state cannot be determined
11 = not available";
CM_ BO_ 2566722814 "Parameters for the battery charger connected to the auxiliary battery.";
CM_ SG_ 2566722814 BatteryCharger2OutputCurrent "Output current of the battery charger connected to the main battery. If positive, this parameter shows the charging current of the battery charger connected to the main battery.  Otherwise, if the charger hardware permits, this parameter represents ...";
CM_ SG_ 2566722814 BatteryCharger2OutputVoltage "Output voltage measured on the battery terminals of the offline battery charger connected to the auxiliary battery.";
CM_ SG_ 2566722814 BatteryCharger2PowerLineState "A state of the battery charger connection to the power line for the charger connected to the auxiliary battery.
0 - Disconnected. The power line is disconnected from the charger.
1 - Connected. The power line is connected to the charger.
2 - ...";
CM_ SG_ 2566722814 BatteryCharger2State "A state of the offline battery charger connected to the auxiliary battery.
0 - Idling. The power line or the battery is disconnected from the charger.
1 - Charging the battery.
2 - Stand-by or maintaining the battery charge.
3 to 12 - Reserved
 ...";
CM_ BO_ 2566723070 "Parameters for the battery charger connected to the main battery.";
CM_ SG_ 2566723070 BatteryCharger1OutputCurrent "Output current of the battery charger connected to the main battery. If positive, this parameter shows the charging current of the battery charger connected to the main battery.  Otherwise, if the charger hardware permits, this parameter represents ...";
CM_ SG_ 2566723070 BatteryCharger1OutputVoltage "Output voltage measured on the battery terminals of the battery charger connected to the main battery.";
CM_ SG_ 2566723070 BatteryCharger1PowerLineState "A state of the battery charger connection to the power line for the charger connected to the main battery.
0 - Disconnected. The power line is disconnected from the charger.
1 - Connected. The power line is connected to the charger.
2 - Error
3 ...";
CM_ SG_ 2566723070 BatteryCharger1State "A state of the battery charger connected to the main battery.
0 - Idling. The power line or the battery is disconnected from the charger.
1 - Charging the battery.
2 - Stand-by or maintaining the battery charge.
3 to 12 - Reserved
13 - Battery ...";
CM_ BO_ 2566725118 "The purpose of this PGN is to group the aftertreatment differential temperature data. These values include the differential temperature measure between the intake and outlet of aftertreatment components.";
CM_ SG_ 2566725118 AT2ThreeWayCatalystDiffTemp "The differential engine combustion byproducts gas temperature measured between the intake and outlet of the three way catalyst for exhaust bank 2.";
CM_ SG_ 2566725118 AT1ThreeWayCatalystDiffTemp "The differential engine combustion byproducts gas temperature measured between the intake and outlet of the three way catalyst for exhaust bank 1.";
CM_ BO_ 2566725374 "The purpose of this PGN is to group the aftertreatment differential temperature data. These values include the differential temperature measure between the intake and outlet of aftertreatment components.";
CM_ SG_ 2566725374 AT2GasOxidationCatalystDiffTemp "The differential engine combustion byproducts gas temperature measured between the intake and outlet of the gas oxidation catalyst for exhaust bank 2.  This parameter should be used with engine fueled by gaseous fuel like natural gas or propane ...";
CM_ SG_ 2566725374 AT1GasOxidationCatalystDiffTemp "The differential engine combustion byproducts gas temperature measured between the intake and outlet of the gas oxidation catalyst for exhaust bank 1.  This parameter should be used with engine fueled by gaseous fuel like natural gas or propane ...";
CM_ BO_ 2566712830 "This PGN contains information for the warm up oxidation catalytic converter in exhaust bank 2.";
CM_ SG_ 2566712830 AT2WrmUpDslOxdtnCtlystOutletTemp "Temperature of engine combustion byproducts leaving the warm up Diesel Oxidation Catalyst in exhaust bank 2.  This diesel parameter should be used with engines fueled by diesel fuel (not gaseous fuel like natural gas or propane).  A separate ...";
CM_ SG_ 2566712830 AT2WrmUpDslOxdtnCtlystIntakeTemp "Temperature of engine combustion byproducts entering the warm up Diesel Oxidation Catalyst in exhaust bank 2.  This diesel parameter should be used with engines fueled by diesel fuel (not gaseous fuel like natural gas or propane).  A separate ...";
CM_ BO_ 2566735358 "The purpose of this PGN is to group the aftertreatment Three Way Catalyst data for bank 2. These values include the intake temperature, outlet temperature and differential pressure as well as the associated preliminary FMIs.
Note: The 5 bits of SPN ...";
CM_ SG_ 2566735358 AT2ThrWyCtlytcCnvrtrDffPrssPrlmn "Used to identify the applicable J1939-73 FMI detected in the Three Way Catalytic Converter differential pressure sensor by the manufacturer’s sensor control software in exhaust bank 2. When there is no failure FMI 31 is sent. In the case of multiple ...";
CM_ SG_ 2566735358 AT2ThrWyCtlystOtltTmpPrlmnaryFMI "Used to identify the applicable J1939-73 FMI detected in the Three Way Catalyst outlet temperature sensor by the manufacturer’s sensor control software in exhaust bank 2. When there is no failure FMI 31 is sent. In the case of multiple failures the ...";
CM_ SG_ 2566735358 AT2ThrWyCtlystIntkTmpPrlmnaryFMI "Used to identify the applicable J1939-73 FMI detected in the Three Way Catalyst intake temperature sensor by the manufacturer’s sensor control software in exhaust bank 2. When there is no failure FMI 31 is sent. In the case of multiple failures the ...";
CM_ SG_ 2566735358 AT2ThreeWayCatalystDiffPress "Exhaust differential pressure measured between the intake and exhaust of a Three Way Catalyst in exhaust bank 2.

(For a single exhaust bank system, refer to parameters in PGN 64838.)";
CM_ SG_ 2566735358 AT2ThreeWayCatalystOutletTemp "Temperature of engine combustion byproducts leaving the Three Way Catalyst in exhaust bank 2. 
 
(For a single exhaust bank system, refer to parameters in PGN 64838.)";
CM_ SG_ 2566735358 AT2ThreeWayCatalystIntakeTemp "Temperature of engine combustion byproducts entering the Three Way Catalyst in exhaust bank 2.

(For a single exhaust bank system, refer to parameters in PGN 64838.)";
CM_ BO_ 2365393662 "Aftertreatment 2 Outlet Gas NOx Sensor Correction Data 2";
CM_ SG_ 2365393662 AT2OutletCorrectedNOx "The corrected outlet NOx value  for aftertreatment 2 shall include all learned adaptions and offsets that are used to adjust the raw signal.
2016 MY and later engines with NOx sensors may be required to output a ‘corrected’ NOx sensor signal in ...";
CM_ SG_ 2365393662 AT2OtltNOxSnsrSlfdgnssFnalResult "Self-diagnosis result for NOx sensor ATO2 (Aftertreatment Outlet Bank 2) as a ratio of detected value to reference value defined by supplier.
This result is used to determine if the signal resulting from the self-diagnosis test (as represented as a ...";
CM_ SG_ 2365393662 AT2OutletNOxSensorNH3Correction "Correction of NH3 at the NOx-signal to correct (recalculate) sensor signal on the Engine ECU side.";
CM_ SG_ 2365393662 AT2OutletNOxSensorNO2Correction "Correction of NO2 at the NOx-signal to correct (recalculate) sensor signal on the Engine ECU side.";
CM_ SG_ 2365393662 AT2OtltNOxSnsrNOxPressCorrection "Correction of pressure NOx-signal to correct (recalculate) sensor signal on the Engine ECU side.";
CM_ SG_ 2365393662 AT2OtltNOxSnsorO2PressCorrection "Correction of pressure Lambda-signal to correct (recalculate) sensor signal on the Engine ECU side.";
CM_ BO_ 2365393918 "Aftertreatment 2 Outlet Gas NOx Sensor Correction Data 1";
CM_ SG_ 2365393918 AT2OutletNOxSensorOperationHours "Counted hours that the NOx-sensor was operated with status \"dewpoint reached\"";
CM_ SG_ 2365393918 AT2OtltNOxSnsrNwPrtDvtnNOxOffset "New part deviation NOx_Offset to correct (recalculate) sensor signal on the Engine ECU side.";
CM_ SG_ 2365393918 AT2OtltNOxSnsrNwPrtDvtionNOxGain "New part deviation NOx_Gain to correct (recalculate) sensor signal on the Engine ECU side.";
CM_ SG_ 2365393918 AT2OutletNOxSensorHeaterRatio "Heater ratio to determine temperature at sensor tip.";
CM_ BO_ 2365394174 "Aftertreatment 2 Intake Gas NOx Sensor Correction Data 2";
CM_ SG_ 2365394174 AT2SCRIntakeCorrectedNOx "The corrected intake Selective Catalytic Reduction NOx value for aftertreatment 2 shall include all learned adaptions and offsets that are used to adjust the raw signal.
2016 MY and later engines with NOx sensors may be required to output a ...";
CM_ SG_ 2365394174 AT2IntkNOxSnsrSlfdgnssFnalResult "Self-diagnosis result for NOx sensor ATI2 (Aftertreatment Intake Bank 2) as a ratio of detected value to reference value defined by supplier.
This result is used to determine if the signal resulting from the self-diagnosis test (as represented as a ...";
CM_ SG_ 2365394174 AT2IntakeNOxSensorNH3Correction "Correction of NH3 at the NOx-signal to correct (recalculate) sensor signal on the Engine ECU side.";
CM_ SG_ 2365394174 AT2IntakeNOxSensorNO2Correction "Correction of NO2 at the NOx-signal to correct (recalculate) sensor signal on the Engine ECU side.";
CM_ SG_ 2365394174 AT2IntkNOxSnsrNOxPressCorrection "Correction of pressure NOx-signal to correct (recalculate) sensor signal on the Engine ECU side.";
CM_ SG_ 2365394174 AT2IntkNOxSnsorO2PressCorrection "Correction of pressure Lambda-signal to correct (recalculate) sensor signal on the Engine ECU side.";
CM_ BO_ 2365394430 "Aftertreatment 2 Intake Gas NOx Sensor Correction Data 1";
CM_ SG_ 2365394430 AT2IntakeNOxSensorOperationHours "Counted hours that the NOx-sensor was operated with status \"dewpoint reached\"";
CM_ SG_ 2365394430 AT2IntkNOxSnsrNwPrtDvtnNOxOffset "New part deviation NOx_Offset to correct (recalculate) sensor signal on the Engine ECU side.";
CM_ SG_ 2365394430 AT2IntkNOxSnsrNwPrtDvtionNOxGain "New part deviation NOx_Gain to correct (recalculate) sensor signal on the Engine ECU side.";
CM_ SG_ 2365394430 AT2IntakeNOxSensorHeaterRatio "Heater ratio to determine temperature at sensor tip.";
CM_ BO_ 2566735102 "Contains information about the aftertreatment 2 fuel system. See also PGN 64928.";
CM_ SG_ 2566735102 AT2FuelPress2Ctrl "Indicates how the device is controlling the aftertreatment 2 fuel pressure 2 regulating control valve.   0% = fully closed, 100%=fully open.";
CM_ SG_ 2566735102 AT2FuelFlowDiverterValveCtrl "Indicates how the device is controlling the aftertreatment 2 fuel flow diverter valve. When this valve is on it diverts fuel flow from the Aftertreatment 2 Regeneration Device.

00 off
01 on
10 reserved for SAE assignment
11 not available";
CM_ SG_ 2566735102 AT2FuelPumpRelayCtrl "Indicates how the device is controlling the aftertreatment 2 fuel pump relay.

00 off
01 on
10 reserved for SAE assignment
11 not available";
CM_ SG_ 2566735102 AT2FuelPress2 "Second fuel pressure measurement for the aftertreatment 2 system.";
CM_ BO_ 2157313790 "The purpose of this PGN is to group the Aftertreatment 2 DPF soot measurement calibration parameters. These values include soot sensor signal mean and standard deviation calibration levels. These calibration levels are associated with Diesel ...";
CM_ SG_ 2157313790 AT2DslPrtcltFltrStStndrdDvtnClbO "Calibration offset for the soot standard deviation for Aftertreatment 2 Diesel Particulate Filter soot sensor.";
CM_ SG_ 2157313790 AT2DslPrtcltFltrStManCalibOffset "Calibration offset for the soot Mean for Aftertreatment 2 Diesel Particulate Filter soot sensor.";
CM_ BO_ 2566724350 "This PGN contains information for the warm up oxidation catalytic converter in exhaust bank 1.";
CM_ SG_ 2566724350 AT1WrmUpDslOxdtnCtlystOutletTemp "This is the temperature measured at the outlet of the warm up oxidation catalytic converter in exhaust bank 1.";
CM_ SG_ 2566724350 AT1WrmUpDslOxdtnCtlystIntakeTemp "This is the temperature measured at the intake of the warm up oxidation catalytic converter in exhaust bank 1.";
BA_DEF_ SG_  "SigType" ENUM  "Default","Range","RangeSigned","ASCII","Discrete","Control","ReferencePGN","DTC","StringDelimiter","StringLength","StringLengthControl","MessageCounter","MessageChecksum";
BA_DEF_ SG_  "GenSigStartValue" INT 0 10000;
BA_DEF_ SG_  "GenSigSendType" ENUM  "Cyclic","OnWrite","OnWriteWithRepetition","OnChange","OnChangeWithRepetition","IfActive","IfActiveWithRepetition","NoSigSendType";
BA_DEF_ SG_  "GenSigILSupport" ENUM  "No","Yes";
BA_DEF_ SG_  "GenSigEVName" STRING ;
BA_DEF_ SG_  "SPN" INT 0 524287;
BA_DEF_ BO_  "TpJ1939VarDlc" ENUM  "No","Yes";
BA_DEF_ BO_  "GenMsgStartDelayTime" INT 0 100000;
BA_DEF_ BO_  "GenMsgILSupport" ENUM  "No","Yes";
BA_DEF_ BO_  "GenMsgDelayTime" INT 0 1000;
BA_DEF_ BO_  "GenMsgRequestable" INT 0 1;
BA_DEF_ BO_  "GenMsgSendType" ENUM  "cyclic","NotUsed","NotUsed","NotUsed","NotUsed","NotUsed","NotUsed","IfActive","noMsgSendType";
BA_DEF_ BO_  "VFrameFormat" ENUM  "StandardCAN","ExtendedCAN","reserved","J1939PG";
BA_DEF_ BO_  "GenMsgCycleTime" INT 0 3600000;
BA_DEF_ SG_  "SystemSignalLongSymbol" STRING ;
BA_DEF_DEF_  "SigType" "Default";
BA_DEF_DEF_  "GenSigStartValue" 0;
BA_DEF_DEF_  "GenSigSendType" "NoSigSendType";
BA_DEF_DEF_  "GenSigILSupport" "Yes";
BA_DEF_DEF_  "GenSigEVName" "Env@Nodename_@Signame";
BA_DEF_DEF_  "SPN" 0;
BA_DEF_DEF_  "TpJ1939VarDlc" "No";
BA_DEF_DEF_  "GenMsgStartDelayTime" 0;
BA_DEF_DEF_  "GenMsgILSupport" "Yes";
BA_DEF_DEF_  "GenMsgDelayTime" 0;
BA_DEF_DEF_  "GenMsgRequestable" 1;
BA_DEF_DEF_  "GenMsgSendType" "noMsgSendType";
BA_DEF_DEF_  "VFrameFormat" "J1939PG";
BA_DEF_DEF_  "GenMsgCycleTime" 0;
BA_DEF_DEF_  "SystemSignalLongSymbol" "";
BA_ "GenMsgCycleTime" BO_ 2563768062 5000;
BA_ "GenMsgSendType" BO_ 2563768062 0;
BA_ "GenMsgCycleTime" BO_ 2566771966 10000;
BA_ "GenMsgSendType" BO_ 2566771966 0;
BA_ "GenMsgDelayTime" BO_ 2566771966 100;
BA_ "GenMsgCycleTime" BO_ 2564882174 1000;
BA_ "GenMsgSendType" BO_ 2564882174 0;
BA_ "GenMsgCycleTime" BO_ 2563833598 5000;
BA_ "GenMsgSendType" BO_ 2563833598 0;
BA_ "GenMsgDelayTime" BO_ 2563833598 100;
BA_ "TpJ1939VarDlc" BO_ 2566843390 1;
BA_ "GenMsgCycleTime" BO_ 2566844926 100;
BA_ "GenMsgSendType" BO_ 2566844926 0;
BA_ "GenMsgCycleTime" BO_ 2566775294 1000;
BA_ "GenMsgSendType" BO_ 2566775294 0;
BA_ "GenMsgCycleTime" BO_ 2566803710 1000;
BA_ "GenMsgSendType" BO_ 2566803710 0;
BA_ "GenMsgCycleTime" BO_ 2566719486 1000;
BA_ "GenMsgSendType" BO_ 2566719486 0;
BA_ "GenMsgDelayTime" BO_ 2566719486 100;
BA_ "TpJ1939VarDlc" BO_ 2633832702 1;
BA_ "GenMsgCycleTime" BO_ 2163223550 20;
BA_ "GenMsgSendType" BO_ 2163223550 0;
BA_ "GenMsgCycleTime" BO_ 2566714878 1000;
BA_ "GenMsgSendType" BO_ 2566714878 0;
BA_ "GenMsgCycleTime" BO_ 2566714622 1000;
BA_ "GenMsgSendType" BO_ 2566714622 0;
BA_ "GenMsgCycleTime" BO_ 2566715390 1000;
BA_ "GenMsgSendType" BO_ 2566715390 0;
BA_ "GenMsgCycleTime" BO_ 2566715134 1000;
BA_ "GenMsgSendType" BO_ 2566715134 0;
BA_ "GenMsgCycleTime" BO_ 2365400830 100;
BA_ "GenMsgSendType" BO_ 2365400830 0;
BA_ "GenMsgDelayTime" BO_ 2365400830 20;
BA_ "GenMsgCycleTime" BO_ 2365401342 100;
BA_ "GenMsgSendType" BO_ 2365401342 0;
BA_ "GenMsgDelayTime" BO_ 2365401342 20;
BA_ "GenMsgCycleTime" BO_ 2365401854 100;
BA_ "GenMsgSendType" BO_ 2365401854 0;
BA_ "GenMsgDelayTime" BO_ 2365401854 20;
BA_ "GenMsgCycleTime" BO_ 2365402366 100;
BA_ "GenMsgSendType" BO_ 2365402366 0;
BA_ "GenMsgDelayTime" BO_ 2365402366 20;
BA_ "GenMsgCycleTime" BO_ 2365402878 100;
BA_ "GenMsgSendType" BO_ 2365402878 0;
BA_ "GenMsgDelayTime" BO_ 2365402878 20;
BA_ "GenMsgCycleTime" BO_ 2365403390 100;
BA_ "GenMsgSendType" BO_ 2365403390 0;
BA_ "GenMsgDelayTime" BO_ 2365403390 20;
BA_ "GenMsgCycleTime" BO_ 2365400318 100;
BA_ "GenMsgSendType" BO_ 2365400318 0;
BA_ "GenMsgDelayTime" BO_ 2365400318 20;
BA_ "GenMsgCycleTime" BO_ 2499614718 250;
BA_ "GenMsgSendType" BO_ 2499614718 0;
BA_ "GenMsgCycleTime" BO_ 2566722814 1000;
BA_ "GenMsgSendType" BO_ 2566722814 0;
BA_ "GenMsgCycleTime" BO_ 2566723070 1000;
BA_ "GenMsgSendType" BO_ 2566723070 0;
BA_ "GenMsgCycleTime" BO_ 2566712830 500;
BA_ "GenMsgSendType" BO_ 2566712830 0;
BA_ "GenMsgCycleTime" BO_ 2566735358 500;
BA_ "GenMsgSendType" BO_ 2566735358 0;
BA_ "GenMsgCycleTime" BO_ 2365393918 1000;
BA_ "GenMsgSendType" BO_ 2365393918 0;
BA_ "GenMsgCycleTime" BO_ 2365394430 1000;
BA_ "GenMsgSendType" BO_ 2365394430 0;
BA_ "GenMsgCycleTime" BO_ 2566735102 500;
BA_ "GenMsgSendType" BO_ 2566735102 0;
BA_ "GenMsgCycleTime" BO_ 2566724350 500;
BA_ "GenMsgSendType" BO_ 2566724350 0;
BA_ "SPN" SG_ 2563768062 MxCntinuousRetarderTorqueLimitRq 1791;
BA_ "SigType" SG_ 2563768062 MxCntinuousRetarderTorqueLimitRq 1;
BA_ "SPN" SG_ 2563768062 MnCntinuousRetarderTorqueLimitRq 1790;
BA_ "SigType" SG_ 2563768062 MnCntinuousRetarderTorqueLimitRq 1;
BA_ "SPN" SG_ 2563768062 MxContinuousRetarderSpeedLimitRq 1789;
BA_ "SigType" SG_ 2563768062 MxContinuousRetarderSpeedLimitRq 1;
BA_ "SPN" SG_ 2563768062 MnContinuousRetarderSpeedLimitRq 1788;
BA_ "SigType" SG_ 2563768062 MnContinuousRetarderSpeedLimitRq 1;
BA_ "SPN" SG_ 2563768062 EngTorqueLimitRqMaxContinuous 1787;
BA_ "GenSigStartValue" SG_ 2563768062 EngTorqueLimitRqMaxContinuous 125;
BA_ "SigType" SG_ 2563768062 EngTorqueLimitRqMaxContinuous 1;
BA_ "SPN" SG_ 2563768062 EngTorqueLimitRqMinContinuous 1786;
BA_ "GenSigStartValue" SG_ 2563768062 EngTorqueLimitRqMinContinuous 125;
BA_ "SigType" SG_ 2563768062 EngTorqueLimitRqMinContinuous 1;
BA_ "SPN" SG_ 2563768062 EngSpeedLimitRqMaxContinuous 1785;
BA_ "SigType" SG_ 2563768062 EngSpeedLimitRqMaxContinuous 1;
BA_ "SPN" SG_ 2563768062 EngSpeedLimitRqMinContinuous 1784;
BA_ "SigType" SG_ 2563768062 EngSpeedLimitRqMinContinuous 1;
BA_ "SPN" SG_ 2633924862 EngAverageCombustionTime 1465;
BA_ "SigType" SG_ 2633924862 EngAverageCombustionTime 1;
BA_ "SPN" SG_ 2633924862 EngDesiredCombustionTime 1464;
BA_ "SigType" SG_ 2633924862 EngDesiredCombustionTime 1;
BA_ "SPN" SG_ 2633924606 EngCyl20CombustionTime 1463;
BA_ "SigType" SG_ 2633924606 EngCyl20CombustionTime 1;
BA_ "SPN" SG_ 2633924606 EngCyl19CombustionTime 1462;
BA_ "SigType" SG_ 2633924606 EngCyl19CombustionTime 1;
BA_ "SPN" SG_ 2633924606 EngCyl18CombustionTime 1461;
BA_ "SigType" SG_ 2633924606 EngCyl18CombustionTime 1;
BA_ "SPN" SG_ 2633924606 EngCyl17CombustionTime 1460;
BA_ "SigType" SG_ 2633924606 EngCyl17CombustionTime 1;
BA_ "SPN" SG_ 2633924350 EngCyl16CombustionTime 1459;
BA_ "SigType" SG_ 2633924350 EngCyl16CombustionTime 1;
BA_ "SPN" SG_ 2633924350 EngCyl15CombustionTime 1458;
BA_ "SigType" SG_ 2633924350 EngCyl15CombustionTime 1;
BA_ "SPN" SG_ 2633924350 EngCyl14CombustionTime 1457;
BA_ "SigType" SG_ 2633924350 EngCyl14CombustionTime 1;
BA_ "SPN" SG_ 2633924350 EngCyl13CombustionTime 1456;
BA_ "SigType" SG_ 2633924350 EngCyl13CombustionTime 1;
BA_ "SPN" SG_ 2633924094 EngCyl12CombustionTime 1455;
BA_ "SigType" SG_ 2633924094 EngCyl12CombustionTime 1;
BA_ "SPN" SG_ 2633924094 EngCyl11CombustionTime 1454;
BA_ "SigType" SG_ 2633924094 EngCyl11CombustionTime 1;
BA_ "SPN" SG_ 2633924094 EngCyl10CombustionTime 1453;
BA_ "SigType" SG_ 2633924094 EngCyl10CombustionTime 1;
BA_ "SPN" SG_ 2633924094 EngCyl9CombustionTime 1452;
BA_ "SigType" SG_ 2633924094 EngCyl9CombustionTime 1;
BA_ "SPN" SG_ 2633923838 EngCyl8CombustionTime 1451;
BA_ "SigType" SG_ 2633923838 EngCyl8CombustionTime 1;
BA_ "SPN" SG_ 2633923838 EngCyl7CombustionTime 1450;
BA_ "SigType" SG_ 2633923838 EngCyl7CombustionTime 1;
BA_ "SPN" SG_ 2633923838 EngCyl6CombustionTime 1449;
BA_ "SigType" SG_ 2633923838 EngCyl6CombustionTime 1;
BA_ "SPN" SG_ 2633923838 EngCyl5CombustionTime 1448;
BA_ "SigType" SG_ 2633923838 EngCyl5CombustionTime 1;
BA_ "SPN" SG_ 2633923582 EngCyl4CombustionTime 1447;
BA_ "SigType" SG_ 2633923582 EngCyl4CombustionTime 1;
BA_ "SPN" SG_ 2633923582 EngCyl3CombustionTime 1446;
BA_ "SigType" SG_ 2633923582 EngCyl3CombustionTime 1;
BA_ "SPN" SG_ 2633923582 EngCyl2CombustionTime 1445;
BA_ "SigType" SG_ 2633923582 EngCyl2CombustionTime 1;
BA_ "SPN" SG_ 2633923582 EngCyl1CombustionTime 1444;
BA_ "SigType" SG_ 2633923582 EngCyl1CombustionTime 1;
BA_ "SPN" SG_ 2633878014 TotalCountOfConfigChangesMade 2887;
BA_ "SigType" SG_ 2633878014 TotalCountOfConfigChangesMade 1;
BA_ "SPN" SG_ 2566771966 TransOilLevelRq 3809;
BA_ "SigType" SG_ 2566771966 TransOilLevelRq 5;
BA_ "SPN" SG_ 2566771966 FifthWheelReleaseCtrl 3314;
BA_ "SigType" SG_ 2566771966 FifthWheelReleaseCtrl 4;
BA_ "SPN" SG_ 2566771966 FfthWhlRleaseCtrlSecurityLockout 3315;
BA_ "SigType" SG_ 2566771966 FfthWhlRleaseCtrlSecurityLockout 4;
BA_ "SPN" SG_ 2566771966 TransferCaseSelectorSwitch 2796;
BA_ "SPN" SG_ 2564882174 SelectedMaxVehicleSpeedLimit 2596;
BA_ "SigType" SG_ 2564882174 SelectedMaxVehicleSpeedLimit 1;
BA_ "SPN" SG_ 2564882174 RqCabZoneHeating 1686;
BA_ "SigType" SG_ 2564882174 RqCabZoneHeating 5;
BA_ "SPN" SG_ 2564882174 RqEngZoneHeating 1685;
BA_ "SigType" SG_ 2564882174 RqEngZoneHeating 5;
BA_ "SPN" SG_ 2564882174 AuxHeaterModeRq 1683;
BA_ "SPN" SG_ 2564882174 EngAutomaticStartEnableSwitch 1656;
BA_ "SigType" SG_ 2564882174 EngAutomaticStartEnableSwitch 4;
BA_ "SPN" SG_ 2564882174 AtomaticGearShiftingEnableSwitch 1666;
BA_ "SigType" SG_ 2564882174 AtomaticGearShiftingEnableSwitch 4;
BA_ "SPN" SG_ 2564882174 ATRegenerationForceSwitch 3696;
BA_ "SigType" SG_ 2564882174 ATRegenerationForceSwitch 4;
BA_ "SPN" SG_ 2564882174 ATRegenerationInhibitSwitch 3695;
BA_ "SigType" SG_ 2564882174 ATRegenerationInhibitSwitch 4;
BA_ "SPN" SG_ 2564882174 VhclLmtngSpdGovernorEnableSwitch 1653;
BA_ "SigType" SG_ 2564882174 VhclLmtngSpdGovernorEnableSwitch 4;
BA_ "SPN" SG_ 2564882174 VhclLmtngSpdGvrnrIncrementSwitch 1654;
BA_ "SigType" SG_ 2564882174 VhclLmtngSpdGvrnrIncrementSwitch 4;
BA_ "SPN" SG_ 2564882174 VhclLmtngSpdGvrnrDecrementSwitch 1655;
BA_ "SigType" SG_ 2564882174 VhclLmtngSpdGvrnrDecrementSwitch 4;
BA_ "SPN" SG_ 2564882174 ParkBrakeCmd 5630;
BA_ "SigType" SG_ 2564882174 ParkBrakeCmd 5;
BA_ "SPN" SG_ 2564882174 SeatBeltSwitch 1856;
BA_ "SigType" SG_ 2564882174 SeatBeltSwitch 4;
BA_ "SPN" SG_ 2564882174 OperatorSeatDirectionSwitch 1714;
BA_ "SigType" SG_ 2564882174 OperatorSeatDirectionSwitch 4;
BA_ "SPN" SG_ 2564882174 BatteryMainSwitchHoldRq 1682;
BA_ "SigType" SG_ 2564882174 BatteryMainSwitchHoldRq 5;
BA_ "SPN" SG_ 2564882174 AuxHeaterCoolantPumpRq 1684;
BA_ "SigType" SG_ 2564882174 AuxHeaterCoolantPumpRq 5;
BA_ "SPN" SG_ 2564882174 CabInteriorTempCmd 1691;
BA_ "SigType" SG_ 2564882174 CabInteriorTempCmd 1;
BA_ "SPN" SG_ 2564882174 RequestedPercentFanSpeed 986;
BA_ "SigType" SG_ 2564882174 RequestedPercentFanSpeed 1;
BA_ "SPN" SG_ 2563833598 SwtchBcklghtIllmntnBrghtnssPrcnt 5532;
BA_ "SigType" SG_ 2563833598 SwtchBcklghtIllmntnBrghtnssPrcnt 1;
BA_ "SPN" SG_ 2563833598 IlluminationBrightnessPercent 1487;
BA_ "SigType" SG_ 2563833598 IlluminationBrightnessPercent 1;
BA_ "SPN" SG_ 2563833598 SwtchIndctnIllmntnBrghtnssPrcent 6820;
BA_ "SigType" SG_ 2563833598 SwtchIndctnIllmntnBrghtnssPrcent 1;
BA_ "SPN" SG_ 2566843390 UnitNumber 233;
BA_ "SigType" SG_ 2566843390 UnitNumber 8;
BA_ "SPN" SG_ 2566843390 SerialNumber 588;
BA_ "SigType" SG_ 2566843390 SerialNumber 8;
BA_ "SPN" SG_ 2566843390 Model 587;
BA_ "SigType" SG_ 2566843390 Model 8;
BA_ "SPN" SG_ 2566843390 Make 586;
BA_ "SigType" SG_ 2566843390 Make 8;
BA_ "SPN" SG_ 2566844926 EngShutdownOverrideSwitch 1237;
BA_ "SigType" SG_ 2566844926 EngShutdownOverrideSwitch 4;
BA_ "SPN" SG_ 2566844926 EngTestModeSwitch 966;
BA_ "SigType" SG_ 2566844926 EngTestModeSwitch 4;
BA_ "SPN" SG_ 2566844926 EngIdleDecrementSwitch 967;
BA_ "SigType" SG_ 2566844926 EngIdleDecrementSwitch 4;
BA_ "SPN" SG_ 2566844926 EngIdleIncrementSwitch 968;
BA_ "SigType" SG_ 2566844926 EngIdleIncrementSwitch 4;
BA_ "SPN" SG_ 2566844926 CruiseCtrlStates 527;
BA_ "SPN" SG_ 2566844926 PTOGovernorState 976;
BA_ "SPN" SG_ 2566844926 CruiseCtrlSetSpeed 86;
BA_ "SigType" SG_ 2566844926 CruiseCtrlSetSpeed 1;
BA_ "SPN" SG_ 2566844926 CruiseCtrlAccelerateSwitch 602;
BA_ "SigType" SG_ 2566844926 CruiseCtrlAccelerateSwitch 4;
BA_ "SPN" SG_ 2566844926 CruiseCtrlResumeSwitch 601;
BA_ "SigType" SG_ 2566844926 CruiseCtrlResumeSwitch 4;
BA_ "SPN" SG_ 2566844926 CruiseCtrlCoastSwitch 600;
BA_ "SigType" SG_ 2566844926 CruiseCtrlCoastSwitch 4;
BA_ "SPN" SG_ 2566844926 CruiseCtrlSetSwitch 599;
BA_ "SigType" SG_ 2566844926 CruiseCtrlSetSwitch 4;
BA_ "SPN" SG_ 2566844926 ClutchSwitch 598;
BA_ "SigType" SG_ 2566844926 ClutchSwitch 4;
BA_ "SPN" SG_ 2566844926 BrakeSwitch 597;
BA_ "SigType" SG_ 2566844926 BrakeSwitch 4;
BA_ "SPN" SG_ 2566844926 CruiseCtrlEnableSwitch 596;
BA_ "SigType" SG_ 2566844926 CruiseCtrlEnableSwitch 4;
BA_ "SPN" SG_ 2566844926 CruiseCtrlActive 595;
BA_ "SigType" SG_ 2566844926 CruiseCtrlActive 4;
BA_ "SPN" SG_ 2566844926 WheelBasedVehicleSpeed 84;
BA_ "SigType" SG_ 2566844926 WheelBasedVehicleSpeed 1;
BA_ "SPN" SG_ 2566844926 ParkBrakeReleaseInhibitRq 3807;
BA_ "SigType" SG_ 2566844926 ParkBrakeReleaseInhibitRq 5;
BA_ "SPN" SG_ 2566844926 CruiseCtrlPauseSwitch 1633;
BA_ "SigType" SG_ 2566844926 CruiseCtrlPauseSwitch 4;
BA_ "SPN" SG_ 2566844926 ParkingBrakeSwitch 70;
BA_ "SigType" SG_ 2566844926 ParkingBrakeSwitch 4;
BA_ "SPN" SG_ 2566844926 TwoSpeedAxleSwitch 69;
BA_ "SigType" SG_ 2566844926 TwoSpeedAxleSwitch 4;
BA_ "SPN" SG_ 2566843902 MaxVehicleSpeedLimit6808 6808;
BA_ "SigType" SG_ 2566843902 MaxVehicleSpeedLimit6808 1;
BA_ "SPN" SG_ 2566843902 CruiseCtrlLowSetLimitSpeed 88;
BA_ "SigType" SG_ 2566843902 CruiseCtrlLowSetLimitSpeed 1;
BA_ "SPN" SG_ 2566843902 CruiseCtrlHighSetLimitSpeed 87;
BA_ "SigType" SG_ 2566843902 CruiseCtrlHighSetLimitSpeed 1;
BA_ "SPN" SG_ 2566843902 MaxVehicleSpeedLimit 74;
BA_ "SigType" SG_ 2566843902 MaxVehicleSpeedLimit 1;
BA_ "SPN" SG_ 2566809598 AuxHeaterMaxOutputPower 1690;
BA_ "SigType" SG_ 2566809598 AuxHeaterMaxOutputPower 1;
BA_ "SPN" SG_ 2633940222 TripServiceBrakeApplications 993;
BA_ "SigType" SG_ 2633940222 TripServiceBrakeApplications 1;
BA_ "SPN" SG_ 2633940222 TripServiceBrakeDistance 992;
BA_ "SigType" SG_ 2633940222 TripServiceBrakeDistance 1;
BA_ "SPN" SG_ 2633940222 TripCompressionBrakeDistance 991;
BA_ "SigType" SG_ 2633940222 TripCompressionBrakeDistance 1;
BA_ "SPN" SG_ 2633940222 TotalCompressionBrakeDistance 990;
BA_ "SigType" SG_ 2633940222 TotalCompressionBrakeDistance 1;
BA_ "SPN" SG_ 2566775294 CbA_CRfrgrntCmpressorOutletPress 2609;
BA_ "SigType" SG_ 2566775294 CbA_CRfrgrntCmpressorOutletPress 1;
BA_ "SPN" SG_ 2566803710 SLIBattery4Temp 2780;
BA_ "SigType" SG_ 2566803710 SLIBattery4Temp 1;
BA_ "SPN" SG_ 2566803710 SLIBattery3Temp 2779;
BA_ "SigType" SG_ 2566803710 SLIBattery3Temp 1;
BA_ "SPN" SG_ 2566803710 Battery2Temp 1801;
BA_ "SigType" SG_ 2566803710 Battery2Temp 1;
BA_ "SPN" SG_ 2566803710 Battery1Temp 1800;
BA_ "SigType" SG_ 2566803710 Battery1Temp 1;
BA_ "SPN" SG_ 2566719486 VhclAccelerationRateLimitLampCmd 6899;
BA_ "SigType" SG_ 2566719486 VhclAccelerationRateLimitLampCmd 5;
BA_ "SPN" SG_ 2566719486 EngSpeedVeryHighLampCmd 6710;
BA_ "SigType" SG_ 2566719486 EngSpeedVeryHighLampCmd 5;
BA_ "SPN" SG_ 2566719486 EngSpeedHighLampCmd 6709;
BA_ "SigType" SG_ 2566719486 EngSpeedHighLampCmd 5;
BA_ "SPN" SG_ 2566719486 EngCtrlModule3ReadyForUseLampCmd 6207;
BA_ "SigType" SG_ 2566719486 EngCtrlModule3ReadyForUseLampCmd 5;
BA_ "SPN" SG_ 2566719486 EngCtrlModule2ReadyForUseLampCmd 6206;
BA_ "SigType" SG_ 2566719486 EngCtrlModule2ReadyForUseLampCmd 5;
BA_ "SPN" SG_ 2566719486 EngCtrlModule1ReadyForUseLampCmd 6205;
BA_ "SigType" SG_ 2566719486 EngCtrlModule1ReadyForUseLampCmd 5;
BA_ "SPN" SG_ 2566719486 EngFuelFilterRestrictedLampCmd 5469;
BA_ "SigType" SG_ 2566719486 EngFuelFilterRestrictedLampCmd 5;
BA_ "SPN" SG_ 2566719486 EngAirFilterRestrictionLampCmd 5086;
BA_ "SigType" SG_ 2566719486 EngAirFilterRestrictionLampCmd 5;
BA_ "SPN" SG_ 2566719486 EngIdleManagementActiveLampCmd 5085;
BA_ "SigType" SG_ 2566719486 EngIdleManagementActiveLampCmd 5;
BA_ "SPN" SG_ 2566719486 EngCoolantLevelLowLampCmd 5084;
BA_ "SigType" SG_ 2566719486 EngCoolantLevelLowLampCmd 5;
BA_ "SPN" SG_ 2566719486 EngCoolantTempHighLampCmd 5083;
BA_ "SigType" SG_ 2566719486 EngCoolantTempHighLampCmd 5;
BA_ "SPN" SG_ 2566719486 EngOilPressLowLampCmd 5082;
BA_ "SigType" SG_ 2566719486 EngOilPressLowLampCmd 5;
BA_ "SPN" SG_ 2566719486 CmprssnBrkEnblSwtchIndctrLampCmd 3987;
BA_ "SigType" SG_ 2566719486 CmprssnBrkEnblSwtchIndctrLampCmd 5;
BA_ "SPN" SG_ 2566719486 EngBrakeActiveLampCmd 5081;
BA_ "SigType" SG_ 2566719486 EngBrakeActiveLampCmd 5;
BA_ "SPN" SG_ 2566719486 OBDMalfunctionIndicatorLampCmd 5080;
BA_ "SigType" SG_ 2566719486 OBDMalfunctionIndicatorLampCmd 5;
BA_ "SPN" SG_ 2566719486 EngRedStopLampCmd 5079;
BA_ "SigType" SG_ 2566719486 EngRedStopLampCmd 5;
BA_ "SPN" SG_ 2566719486 EngAmberWarningLampCmd 5078;
BA_ "SigType" SG_ 2566719486 EngAmberWarningLampCmd 5;
BA_ "SPN" SG_ 2566719486 EngProtectLampCmd 5077;
BA_ "SigType" SG_ 2566719486 EngProtectLampCmd 5;
BA_ "SPN" SG_ 2633832702 RolloverSensorType 4934;
BA_ "SPN" SG_ 2633832702 RearCollisionSensor4Type 4933;
BA_ "SPN" SG_ 2633832702 RearCollisionSensor3Type 4932;
BA_ "SPN" SG_ 2633832702 RearCollisionSensor2Type 4931;
BA_ "SPN" SG_ 2633832702 RearCollisionSensor1Type 4930;
BA_ "SPN" SG_ 2633832702 SideCollisionSensorRearRightType 4929;
BA_ "SPN" SG_ 2633832702 SdCllisionSensorMidRearRightType 4928;
BA_ "SPN" SG_ 2633832702 SdCllsionSensorMidFrontRightType 4927;
BA_ "SPN" SG_ 2633832702 SdeCollisionSensorFrontRightType 4926;
BA_ "SPN" SG_ 2633832702 SideCollisionSensorRearLeftType 4925;
BA_ "SPN" SG_ 2633832702 SdCollisionSensorMidRearLeftType 4924;
BA_ "SPN" SG_ 2633832702 SdCllisionSensorMidFrontLeftType 4923;
BA_ "SPN" SG_ 2633832702 SideCollisionSensorFrontLeftType 4922;
BA_ "SPN" SG_ 2633832702 FrontalCollisionSensor4Type 4921;
BA_ "SPN" SG_ 2633832702 FrontalCollisionSensor3Type 4920;
BA_ "SPN" SG_ 2633832702 FrontalCollisionSensor2Type 4919;
BA_ "SPN" SG_ 2633832702 FrontalCollisionSensor1Type 4918;
BA_ "SPN" SG_ 2163223550 CrashChecksum 4975;
BA_ "SPN" SG_ 2163223550 CrashCounter 4974;
BA_ "SPN" SG_ 2163223550 CrashType 4973;
BA_ "SPN" SG_ 2566714878 EngChrgArClr2PrecoolerEfficiency 5288;
BA_ "SigType" SG_ 2566714878 EngChrgArClr2PrecoolerEfficiency 1;
BA_ "SPN" SG_ 2566714878 EngChrgArClr2PrecoolerOutletTemp 5287;
BA_ "SigType" SG_ 2566714878 EngChrgArClr2PrecoolerOutletTemp 1;
BA_ "SPN" SG_ 2566714878 EngChrgArClr2PrecoolerIntakeTemp 5286;
BA_ "SigType" SG_ 2566714878 EngChrgArClr2PrecoolerIntakeTemp 1;
BA_ "SPN" SG_ 2566714622 EngChargeAirCooler2Efficiency 5292;
BA_ "SigType" SG_ 2566714622 EngChargeAirCooler2Efficiency 1;
BA_ "SPN" SG_ 2566714622 EngChrgeAirCooler2AmbientAirTemp 5291;
BA_ "SigType" SG_ 2566714622 EngChrgeAirCooler2AmbientAirTemp 1;
BA_ "SPN" SG_ 2566714622 EngChargeAirCooler2OutletTemp 5290;
BA_ "SigType" SG_ 2566714622 EngChargeAirCooler2OutletTemp 1;
BA_ "SPN" SG_ 2566714622 EngChargeAirCooler2IntakeTemp 5289;
BA_ "SigType" SG_ 2566714622 EngChargeAirCooler2IntakeTemp 1;
BA_ "SPN" SG_ 2566715390 EngChrgArClr1PrecoolerEfficiency 5282;
BA_ "SigType" SG_ 2566715390 EngChrgArClr1PrecoolerEfficiency 1;
BA_ "SPN" SG_ 2566715390 EngChrgArClr1PrecoolerOutletTemp 5281;
BA_ "SigType" SG_ 2566715390 EngChrgArClr1PrecoolerOutletTemp 1;
BA_ "SPN" SG_ 2566715390 EngChrgArClr1PrecoolerIntakeTemp 5280;
BA_ "SigType" SG_ 2566715390 EngChrgArClr1PrecoolerIntakeTemp 1;
BA_ "SPN" SG_ 2566715134 EngChargeAirCooler1Efficiency 5285;
BA_ "SigType" SG_ 2566715134 EngChargeAirCooler1Efficiency 1;
BA_ "SPN" SG_ 2566715134 EngChrgeAirCooler1AmbientAirTemp 5284;
BA_ "SigType" SG_ 2566715134 EngChrgeAirCooler1AmbientAirTemp 1;
BA_ "SPN" SG_ 2566715134 EngChargeAirCooler1IntakeTemp 5283;
BA_ "SigType" SG_ 2566715134 EngChargeAirCooler1IntakeTemp 1;
BA_ "SPN" SG_ 2365400830 Joystick9Button9PressedStatus 4697;
BA_ "SigType" SG_ 2365400830 Joystick9Button9PressedStatus 4;
BA_ "SPN" SG_ 2365400830 Joystick9Button10PressedStatus 4696;
BA_ "SigType" SG_ 2365400830 Joystick9Button10PressedStatus 4;
BA_ "SPN" SG_ 2365400830 Joystick9Button11PressedStatus 4695;
BA_ "SigType" SG_ 2365400830 Joystick9Button11PressedStatus 4;
BA_ "SPN" SG_ 2365400830 Joystick9Button12PressedStatus 4694;
BA_ "SigType" SG_ 2365400830 Joystick9Button12PressedStatus 4;
BA_ "SPN" SG_ 2365400830 Joystick9Button5PressedStatus 4693;
BA_ "SigType" SG_ 2365400830 Joystick9Button5PressedStatus 4;
BA_ "SPN" SG_ 2365400830 Joystick9Button6PressedStatus 4692;
BA_ "SigType" SG_ 2365400830 Joystick9Button6PressedStatus 4;
BA_ "SPN" SG_ 2365400830 Joystick9Button7PressedStatus 4691;
BA_ "SigType" SG_ 2365400830 Joystick9Button7PressedStatus 4;
BA_ "SPN" SG_ 2365400830 Joystick9Button8PressedStatus 4690;
BA_ "SigType" SG_ 2365400830 Joystick9Button8PressedStatus 4;
BA_ "SPN" SG_ 2365400830 Joystick9Button1PressedStatus 4689;
BA_ "SigType" SG_ 2365400830 Joystick9Button1PressedStatus 4;
BA_ "SPN" SG_ 2365400830 Joystick9Button2PressedStatus 4688;
BA_ "SigType" SG_ 2365400830 Joystick9Button2PressedStatus 4;
BA_ "SPN" SG_ 2365400830 Joystick9Button3PressedStatus 4687;
BA_ "SigType" SG_ 2365400830 Joystick9Button3PressedStatus 4;
BA_ "SPN" SG_ 2365400830 Joystick9Button4PressedStatus 4686;
BA_ "SigType" SG_ 2365400830 Joystick9Button4PressedStatus 4;
BA_ "SPN" SG_ 2365400830 Joystick9XAxisDetentPosStatus 4685;
BA_ "SigType" SG_ 2365400830 Joystick9XAxisDetentPosStatus 4;
BA_ "SPN" SG_ 2365400830 Joystick9YAxisDetentPosStatus 4684;
BA_ "SigType" SG_ 2365400830 Joystick9YAxisDetentPosStatus 4;
BA_ "SPN" SG_ 2365400830 Joystick9YAxisPos 4683;
BA_ "SPN" SG_ 2365400830 Jystck9YAxsLvrFrwrdPstvPosStatus 4682;
BA_ "SigType" SG_ 2365400830 Jystck9YAxsLvrFrwrdPstvPosStatus 4;
BA_ "SPN" SG_ 2365400830 Jystck9YAxsLvrBckNgtivePosStatus 4681;
BA_ "SigType" SG_ 2365400830 Jystck9YAxsLvrBckNgtivePosStatus 4;
BA_ "SPN" SG_ 2365400830 Joystick9YAxisNeutralPosStatus 4680;
BA_ "SigType" SG_ 2365400830 Joystick9YAxisNeutralPosStatus 4;
BA_ "SPN" SG_ 2365400830 Joystick9XAxisPos 4679;
BA_ "SPN" SG_ 2365400830 Jystck9XAxsLvrRghtPstvePosStatus 4678;
BA_ "SigType" SG_ 2365400830 Jystck9XAxsLvrRghtPstvePosStatus 4;
BA_ "SPN" SG_ 2365400830 Jystck9XAxsLvrLftNgtivePosStatus 4677;
BA_ "SigType" SG_ 2365400830 Jystck9XAxsLvrLftNgtivePosStatus 4;
BA_ "SPN" SG_ 2365400830 Joystick9XAxisNeutralPosStatus 4676;
BA_ "SigType" SG_ 2365400830 Joystick9XAxisNeutralPosStatus 4;
BA_ "SPN" SG_ 2365401342 Joystick8Button9PressedStatus 4660;
BA_ "SigType" SG_ 2365401342 Joystick8Button9PressedStatus 4;
BA_ "SPN" SG_ 2365401342 Joystick8Button10PressedStatus 4659;
BA_ "SigType" SG_ 2365401342 Joystick8Button10PressedStatus 4;
BA_ "SPN" SG_ 2365401342 Joystick8Button11PressedStatus 4658;
BA_ "SigType" SG_ 2365401342 Joystick8Button11PressedStatus 4;
BA_ "SPN" SG_ 2365401342 Joystick8Button12PressedStatus 4657;
BA_ "SigType" SG_ 2365401342 Joystick8Button12PressedStatus 4;
BA_ "SPN" SG_ 2365401342 Joystick8Button5PressedStatus 4656;
BA_ "SigType" SG_ 2365401342 Joystick8Button5PressedStatus 4;
BA_ "SPN" SG_ 2365401342 Joystick8Button6PressedStatus 4655;
BA_ "SigType" SG_ 2365401342 Joystick8Button6PressedStatus 4;
BA_ "SPN" SG_ 2365401342 Joystick8Button7PressedStatus 4654;
BA_ "SigType" SG_ 2365401342 Joystick8Button7PressedStatus 4;
BA_ "SPN" SG_ 2365401342 Joystick8Button8PressedStatus 4653;
BA_ "SigType" SG_ 2365401342 Joystick8Button8PressedStatus 4;
BA_ "SPN" SG_ 2365401342 Joystick8Button1PressedStatus 4652;
BA_ "SigType" SG_ 2365401342 Joystick8Button1PressedStatus 4;
BA_ "SPN" SG_ 2365401342 Joystick8Button2PressedStatus 4651;
BA_ "SigType" SG_ 2365401342 Joystick8Button2PressedStatus 4;
BA_ "SPN" SG_ 2365401342 Joystick8Button3PressedStatus 4650;
BA_ "SigType" SG_ 2365401342 Joystick8Button3PressedStatus 4;
BA_ "SPN" SG_ 2365401342 Joystick8Button4PressedStatus 4649;
BA_ "SigType" SG_ 2365401342 Joystick8Button4PressedStatus 4;
BA_ "SPN" SG_ 2365401342 Joystick8XAxisDetentPosStatus 4648;
BA_ "SigType" SG_ 2365401342 Joystick8XAxisDetentPosStatus 4;
BA_ "SPN" SG_ 2365401342 Joystick8YAxisDetentPosStatus 4647;
BA_ "SigType" SG_ 2365401342 Joystick8YAxisDetentPosStatus 4;
BA_ "SPN" SG_ 2365401342 Joystick8YAxisPos 4646;
BA_ "SPN" SG_ 2365401342 Jystck8YAxsLvrFrwrdPstvPosStatus 4645;
BA_ "SigType" SG_ 2365401342 Jystck8YAxsLvrFrwrdPstvPosStatus 4;
BA_ "SPN" SG_ 2365401342 Jystck8YAxsLvrBckNgtivePosStatus 4644;
BA_ "SigType" SG_ 2365401342 Jystck8YAxsLvrBckNgtivePosStatus 4;
BA_ "SPN" SG_ 2365401342 Joystick8YAxisNeutralPosStatus 4643;
BA_ "SigType" SG_ 2365401342 Joystick8YAxisNeutralPosStatus 4;
BA_ "SPN" SG_ 2365401342 Joystick8XAxisPos 4642;
BA_ "SPN" SG_ 2365401342 Jystck8XAxsLvrRghtPstvePosStatus 4641;
BA_ "SigType" SG_ 2365401342 Jystck8XAxsLvrRghtPstvePosStatus 4;
BA_ "SPN" SG_ 2365401342 Jystck8XAxsLvrLftNgtivePosStatus 4640;
BA_ "SigType" SG_ 2365401342 Jystck8XAxsLvrLftNgtivePosStatus 4;
BA_ "SPN" SG_ 2365401342 Joystick8XAxisNeutralPosStatus 4639;
BA_ "SigType" SG_ 2365401342 Joystick8XAxisNeutralPosStatus 4;
BA_ "SPN" SG_ 2365401854 Joystick7Button9PressedStatus 4623;
BA_ "SigType" SG_ 2365401854 Joystick7Button9PressedStatus 4;
BA_ "SPN" SG_ 2365401854 Joystick7Button10PressedStatus 4622;
BA_ "SigType" SG_ 2365401854 Joystick7Button10PressedStatus 4;
BA_ "SPN" SG_ 2365401854 Joystick7Button11PressedStatus 4621;
BA_ "SigType" SG_ 2365401854 Joystick7Button11PressedStatus 4;
BA_ "SPN" SG_ 2365401854 Joystick7Button12PressedStatus 4620;
BA_ "SigType" SG_ 2365401854 Joystick7Button12PressedStatus 4;
BA_ "SPN" SG_ 2365401854 Joystick7Button5PressedStatus 4619;
BA_ "SigType" SG_ 2365401854 Joystick7Button5PressedStatus 4;
BA_ "SPN" SG_ 2365401854 Joystick7Button6PressedStatus 4618;
BA_ "SigType" SG_ 2365401854 Joystick7Button6PressedStatus 4;
BA_ "SPN" SG_ 2365401854 Joystick7Button7PressedStatus 4617;
BA_ "SigType" SG_ 2365401854 Joystick7Button7PressedStatus 4;
BA_ "SPN" SG_ 2365401854 Joystick7Button8PressedStatus 4616;
BA_ "SigType" SG_ 2365401854 Joystick7Button8PressedStatus 4;
BA_ "SPN" SG_ 2365401854 Joystick7Button1PressedStatus 4615;
BA_ "SigType" SG_ 2365401854 Joystick7Button1PressedStatus 4;
BA_ "SPN" SG_ 2365401854 Joystick7Button2PressedStatus 4614;
BA_ "SigType" SG_ 2365401854 Joystick7Button2PressedStatus 4;
BA_ "SPN" SG_ 2365401854 Joystick7Button3PressedStatus 4613;
BA_ "SigType" SG_ 2365401854 Joystick7Button3PressedStatus 4;
BA_ "SPN" SG_ 2365401854 Joystick7Button4PressedStatus 4612;
BA_ "SigType" SG_ 2365401854 Joystick7Button4PressedStatus 4;
BA_ "SPN" SG_ 2365401854 Joystick7XAxisDetentPosStatus 4611;
BA_ "SigType" SG_ 2365401854 Joystick7XAxisDetentPosStatus 4;
BA_ "SPN" SG_ 2365401854 Joystick7YAxisDetentPosStatus 4610;
BA_ "SigType" SG_ 2365401854 Joystick7YAxisDetentPosStatus 4;
BA_ "SPN" SG_ 2365401854 Joystick7YAxisPos 4609;
BA_ "SPN" SG_ 2365401854 Jystck7YAxsLvrFrwrdPstvPosStatus 4608;
BA_ "SigType" SG_ 2365401854 Jystck7YAxsLvrFrwrdPstvPosStatus 4;
BA_ "SPN" SG_ 2365401854 Jystck7YAxsLvrBckNgtivePosStatus 4607;
BA_ "SigType" SG_ 2365401854 Jystck7YAxsLvrBckNgtivePosStatus 4;
BA_ "SPN" SG_ 2365401854 Joystick7YAxisNeutralPosStatus 4606;
BA_ "SigType" SG_ 2365401854 Joystick7YAxisNeutralPosStatus 4;
BA_ "SPN" SG_ 2365401854 Joystick7XAxisPos 4605;
BA_ "SPN" SG_ 2365401854 Jystck7XAxsLvrRghtPstvePosStatus 4604;
BA_ "SigType" SG_ 2365401854 Jystck7XAxsLvrRghtPstvePosStatus 4;
BA_ "SPN" SG_ 2365401854 Jystck7XAxsLvrLftNgtivePosStatus 4603;
BA_ "SigType" SG_ 2365401854 Jystck7XAxsLvrLftNgtivePosStatus 4;
BA_ "SPN" SG_ 2365401854 Joystick7XAxisNeutralPosStatus 4602;
BA_ "SigType" SG_ 2365401854 Joystick7XAxisNeutralPosStatus 4;
BA_ "SPN" SG_ 2365402366 Joystick6Button9PressedStatus 4586;
BA_ "SigType" SG_ 2365402366 Joystick6Button9PressedStatus 4;
BA_ "SPN" SG_ 2365402366 Joystick6Button10PressedStatus 4585;
BA_ "SigType" SG_ 2365402366 Joystick6Button10PressedStatus 4;
BA_ "SPN" SG_ 2365402366 Joystick6Button11PressedStatus 4584;
BA_ "SigType" SG_ 2365402366 Joystick6Button11PressedStatus 4;
BA_ "SPN" SG_ 2365402366 Joystick6Button12PressedStatus 4583;
BA_ "SigType" SG_ 2365402366 Joystick6Button12PressedStatus 4;
BA_ "SPN" SG_ 2365402366 Joystick6Button5PressedStatus 4582;
BA_ "SigType" SG_ 2365402366 Joystick6Button5PressedStatus 4;
BA_ "SPN" SG_ 2365402366 Joystick6Button6PressedStatus 4581;
BA_ "SigType" SG_ 2365402366 Joystick6Button6PressedStatus 4;
BA_ "SPN" SG_ 2365402366 Joystick6Button7PressedStatus 4580;
BA_ "SigType" SG_ 2365402366 Joystick6Button7PressedStatus 4;
BA_ "SPN" SG_ 2365402366 Joystick6Button8PressedStatus 4579;
BA_ "SigType" SG_ 2365402366 Joystick6Button8PressedStatus 4;
BA_ "SPN" SG_ 2365402366 Joystick6Button1PressedStatus 4578;
BA_ "SigType" SG_ 2365402366 Joystick6Button1PressedStatus 4;
BA_ "SPN" SG_ 2365402366 Joystick6Button2PressedStatus 4577;
BA_ "SigType" SG_ 2365402366 Joystick6Button2PressedStatus 4;
BA_ "SPN" SG_ 2365402366 Joystick6Button3PressedStatus 4576;
BA_ "SigType" SG_ 2365402366 Joystick6Button3PressedStatus 4;
BA_ "SPN" SG_ 2365402366 Joystick6Button4PressedStatus 4575;
BA_ "SigType" SG_ 2365402366 Joystick6Button4PressedStatus 4;
BA_ "SPN" SG_ 2365402366 Joystick6XAxisDetentPosStatus 4574;
BA_ "SigType" SG_ 2365402366 Joystick6XAxisDetentPosStatus 4;
BA_ "SPN" SG_ 2365402366 Joystick6YAxisDetentPosStatus 4573;
BA_ "SigType" SG_ 2365402366 Joystick6YAxisDetentPosStatus 4;
BA_ "SPN" SG_ 2365402366 Joystick6YAxisPos 4572;
BA_ "SPN" SG_ 2365402366 Jystck6YAxsLvrFrwrdPstvPosStatus 4571;
BA_ "SigType" SG_ 2365402366 Jystck6YAxsLvrFrwrdPstvPosStatus 4;
BA_ "SPN" SG_ 2365402366 Jystck6YAxsLvrBckNgtivePosStatus 4570;
BA_ "SigType" SG_ 2365402366 Jystck6YAxsLvrBckNgtivePosStatus 4;
BA_ "SPN" SG_ 2365402366 Joystick6YAxisNeutralPosStatus 4569;
BA_ "SigType" SG_ 2365402366 Joystick6YAxisNeutralPosStatus 4;
BA_ "SPN" SG_ 2365402366 Joystick6XAxisPos 4568;
BA_ "SPN" SG_ 2365402366 Jystck6XAxsLvrRghtPstvePosStatus 4567;
BA_ "SigType" SG_ 2365402366 Jystck6XAxsLvrRghtPstvePosStatus 4;
BA_ "SPN" SG_ 2365402366 Jystck6XAxsLvrLftNgtivePosStatus 4566;
BA_ "SigType" SG_ 2365402366 Jystck6XAxsLvrLftNgtivePosStatus 4;
BA_ "SPN" SG_ 2365402366 Joystick6XAxisNeutralPosStatus 4565;
BA_ "SigType" SG_ 2365402366 Joystick6XAxisNeutralPosStatus 4;
BA_ "SPN" SG_ 2365402878 Joystick5Button9PressedStatus 4549;
BA_ "SigType" SG_ 2365402878 Joystick5Button9PressedStatus 4;
BA_ "SPN" SG_ 2365402878 Joystick5Button10PressedStatus 4548;
BA_ "SigType" SG_ 2365402878 Joystick5Button10PressedStatus 4;
BA_ "SPN" SG_ 2365402878 Joystick5Button11PressedStatus 4547;
BA_ "SigType" SG_ 2365402878 Joystick5Button11PressedStatus 4;
BA_ "SPN" SG_ 2365402878 Joystick5Button12PressedStatus 4546;
BA_ "SigType" SG_ 2365402878 Joystick5Button12PressedStatus 4;
BA_ "SPN" SG_ 2365402878 Joystick5Button5PressedStatus 4545;
BA_ "SigType" SG_ 2365402878 Joystick5Button5PressedStatus 4;
BA_ "SPN" SG_ 2365402878 Joystick5Button6PressedStatus 4544;
BA_ "SigType" SG_ 2365402878 Joystick5Button6PressedStatus 4;
BA_ "SPN" SG_ 2365402878 Joystick5Button7PressedStatus 4543;
BA_ "SigType" SG_ 2365402878 Joystick5Button7PressedStatus 4;
BA_ "SPN" SG_ 2365402878 Joystick5Button8PressedStatus 4542;
BA_ "SigType" SG_ 2365402878 Joystick5Button8PressedStatus 4;
BA_ "SPN" SG_ 2365402878 Joystick5Button1PressedStatus 4541;
BA_ "SigType" SG_ 2365402878 Joystick5Button1PressedStatus 4;
BA_ "SPN" SG_ 2365402878 Joystick5Button2PressedStatus 4540;
BA_ "SigType" SG_ 2365402878 Joystick5Button2PressedStatus 4;
BA_ "SPN" SG_ 2365402878 Joystick5Button3PressedStatus 4539;
BA_ "SigType" SG_ 2365402878 Joystick5Button3PressedStatus 4;
BA_ "SPN" SG_ 2365402878 Joystick5Button4PressedStatus 4538;
BA_ "SigType" SG_ 2365402878 Joystick5Button4PressedStatus 4;
BA_ "SPN" SG_ 2365402878 Joystick5XAxisDetentPosStatus 4537;
BA_ "SigType" SG_ 2365402878 Joystick5XAxisDetentPosStatus 4;
BA_ "SPN" SG_ 2365402878 Joystick5YAxisDetentPosStatus 4536;
BA_ "SigType" SG_ 2365402878 Joystick5YAxisDetentPosStatus 4;
BA_ "SPN" SG_ 2365402878 Joystick5YAxisPos 4535;
BA_ "SPN" SG_ 2365402878 Jystck5YAxsLvrFrwrdPstvPosStatus 4534;
BA_ "SigType" SG_ 2365402878 Jystck5YAxsLvrFrwrdPstvPosStatus 4;
BA_ "SPN" SG_ 2365402878 Jystck5YAxsLvrBckNgtivePosStatus 4533;
BA_ "SigType" SG_ 2365402878 Jystck5YAxsLvrBckNgtivePosStatus 4;
BA_ "SPN" SG_ 2365402878 Joystick5YAxisNeutralPosStatus 4532;
BA_ "SigType" SG_ 2365402878 Joystick5YAxisNeutralPosStatus 4;
BA_ "SPN" SG_ 2365402878 Joystick5XAxisPos 4531;
BA_ "SPN" SG_ 2365402878 Jystck5XAxsLvrRghtPstvePosStatus 4530;
BA_ "SigType" SG_ 2365402878 Jystck5XAxsLvrRghtPstvePosStatus 4;
BA_ "SPN" SG_ 2365402878 Jystck5XAxsLvrLftNgtivePosStatus 4529;
BA_ "SigType" SG_ 2365402878 Jystck5XAxsLvrLftNgtivePosStatus 4;
BA_ "SPN" SG_ 2365402878 Joystick5XAxisNeutralPosStatus 4528;
BA_ "SigType" SG_ 2365402878 Joystick5XAxisNeutralPosStatus 4;
BA_ "SPN" SG_ 2365403390 Joystick4Button9PressedStatus 4512;
BA_ "SigType" SG_ 2365403390 Joystick4Button9PressedStatus 4;
BA_ "SPN" SG_ 2365403390 Joystick4Button10PressedStatus 4511;
BA_ "SigType" SG_ 2365403390 Joystick4Button10PressedStatus 4;
BA_ "SPN" SG_ 2365403390 Joystick4Button11PressedStatus 4510;
BA_ "SigType" SG_ 2365403390 Joystick4Button11PressedStatus 4;
BA_ "SPN" SG_ 2365403390 Joystick4Button12PressedStatus 4509;
BA_ "SigType" SG_ 2365403390 Joystick4Button12PressedStatus 4;
BA_ "SPN" SG_ 2365403390 Joystick4Button5PressedStatus 4508;
BA_ "SigType" SG_ 2365403390 Joystick4Button5PressedStatus 4;
BA_ "SPN" SG_ 2365403390 Joystick4Button6PressedStatus 4507;
BA_ "SigType" SG_ 2365403390 Joystick4Button6PressedStatus 4;
BA_ "SPN" SG_ 2365403390 Joystick4Button7PressedStatus 4506;
BA_ "SigType" SG_ 2365403390 Joystick4Button7PressedStatus 4;
BA_ "SPN" SG_ 2365403390 Joystick4Button8PressedStatus 4505;
BA_ "SigType" SG_ 2365403390 Joystick4Button8PressedStatus 4;
BA_ "SPN" SG_ 2365403390 Joystick4Button1PressedStatus 4504;
BA_ "SigType" SG_ 2365403390 Joystick4Button1PressedStatus 4;
BA_ "SPN" SG_ 2365403390 Joystick4Button2PressedStatus 4503;
BA_ "SigType" SG_ 2365403390 Joystick4Button2PressedStatus 4;
BA_ "SPN" SG_ 2365403390 Joystick4Button3PressedStatus 4502;
BA_ "SigType" SG_ 2365403390 Joystick4Button3PressedStatus 4;
BA_ "SPN" SG_ 2365403390 Joystick4Button4PressedStatus 4501;
BA_ "SigType" SG_ 2365403390 Joystick4Button4PressedStatus 4;
BA_ "SPN" SG_ 2365403390 Joystick4XAxisDetentPosStatus 4500;
BA_ "SigType" SG_ 2365403390 Joystick4XAxisDetentPosStatus 4;
BA_ "SPN" SG_ 2365403390 Joystick4YAxisDetentPosStatus 4499;
BA_ "SigType" SG_ 2365403390 Joystick4YAxisDetentPosStatus 4;
BA_ "SPN" SG_ 2365403390 Joystick4YAxisPos 4498;
BA_ "SPN" SG_ 2365403390 Jystck4YAxsLvrFrwrdPstvPosStatus 4497;
BA_ "SigType" SG_ 2365403390 Jystck4YAxsLvrFrwrdPstvPosStatus 4;
BA_ "SPN" SG_ 2365403390 Jystck4YAxsLvrBckNgtivePosStatus 4496;
BA_ "SigType" SG_ 2365403390 Jystck4YAxsLvrBckNgtivePosStatus 4;
BA_ "SPN" SG_ 2365403390 Joystick4YAxisNeutralPosStatus 4495;
BA_ "SigType" SG_ 2365403390 Joystick4YAxisNeutralPosStatus 4;
BA_ "SPN" SG_ 2365403390 Joystick4XAxisPos 4494;
BA_ "SPN" SG_ 2365403390 Jystck4XAxsLvrRghtPstvePosStatus 4493;
BA_ "SigType" SG_ 2365403390 Jystck4XAxsLvrRghtPstvePosStatus 4;
BA_ "SPN" SG_ 2365403390 Jystck4XAxsLvrLftNgtivePosStatus 4492;
BA_ "SigType" SG_ 2365403390 Jystck4XAxsLvrLftNgtivePosStatus 4;
BA_ "SPN" SG_ 2365403390 Joystick4XAxisNeutralPosStatus 4491;
BA_ "SigType" SG_ 2365403390 Joystick4XAxisNeutralPosStatus 4;
BA_ "SPN" SG_ 2365400318 Joystick10Button9PressedStatus 4734;
BA_ "SigType" SG_ 2365400318 Joystick10Button9PressedStatus 4;
BA_ "SPN" SG_ 2365400318 Joystick10Button10PressedStatus 4733;
BA_ "SigType" SG_ 2365400318 Joystick10Button10PressedStatus 4;
BA_ "SPN" SG_ 2365400318 Joystick10Button11PressedStatus 4732;
BA_ "SigType" SG_ 2365400318 Joystick10Button11PressedStatus 4;
BA_ "SPN" SG_ 2365400318 Joystick10Button12PressedStatus 4731;
BA_ "SigType" SG_ 2365400318 Joystick10Button12PressedStatus 4;
BA_ "SPN" SG_ 2365400318 Joystick10Button5PressedStatus 4730;
BA_ "SigType" SG_ 2365400318 Joystick10Button5PressedStatus 4;
BA_ "SPN" SG_ 2365400318 Joystick10Button6PressedStatus 4729;
BA_ "SigType" SG_ 2365400318 Joystick10Button6PressedStatus 4;
BA_ "SPN" SG_ 2365400318 Joystick10Button7PressedStatus 4728;
BA_ "SigType" SG_ 2365400318 Joystick10Button7PressedStatus 4;
BA_ "SPN" SG_ 2365400318 Joystick10Button8PressedStatus 4727;
BA_ "SigType" SG_ 2365400318 Joystick10Button8PressedStatus 4;
BA_ "SPN" SG_ 2365400318 Joystick10Button1PressedStatus 4726;
BA_ "SigType" SG_ 2365400318 Joystick10Button1PressedStatus 4;
BA_ "SPN" SG_ 2365400318 Joystick10Button2PressedStatus 4725;
BA_ "SigType" SG_ 2365400318 Joystick10Button2PressedStatus 4;
BA_ "SPN" SG_ 2365400318 Joystick10Button3PressedStatus 4724;
BA_ "SigType" SG_ 2365400318 Joystick10Button3PressedStatus 4;
BA_ "SPN" SG_ 2365400318 Joystick10Button4PressedStatus 4723;
BA_ "SigType" SG_ 2365400318 Joystick10Button4PressedStatus 4;
BA_ "SPN" SG_ 2365400318 Joystick10XAxisDetentPosStatus 4722;
BA_ "SigType" SG_ 2365400318 Joystick10XAxisDetentPosStatus 4;
BA_ "SPN" SG_ 2365400318 Joystick10YAxisDetentPosStatus 4721;
BA_ "SigType" SG_ 2365400318 Joystick10YAxisDetentPosStatus 4;
BA_ "SPN" SG_ 2365400318 Joystick10YAxisPos 4720;
BA_ "SPN" SG_ 2365400318 Jystck10YAxsLvrFrwrdPstvPsStatus 4719;
BA_ "SigType" SG_ 2365400318 Jystck10YAxsLvrFrwrdPstvPsStatus 4;
BA_ "SPN" SG_ 2365400318 Jystck10YAxsLvrBckNgtvePosStatus 4718;
BA_ "SigType" SG_ 2365400318 Jystck10YAxsLvrBckNgtvePosStatus 4;
BA_ "SPN" SG_ 2365400318 Joystick10YAxisNeutralPosStatus 4717;
BA_ "SigType" SG_ 2365400318 Joystick10YAxisNeutralPosStatus 4;
BA_ "SPN" SG_ 2365400318 Joystick10XAxisPos 4716;
BA_ "SPN" SG_ 2365400318 Jystck10XAxsLvrRghtPstvPosStatus 4715;
BA_ "SigType" SG_ 2365400318 Jystck10XAxsLvrRghtPstvPosStatus 4;
BA_ "SPN" SG_ 2365400318 Jystck10XAxsLvrLftNgtvePosStatus 4714;
BA_ "SigType" SG_ 2365400318 Jystck10XAxsLvrLftNgtvePosStatus 4;
BA_ "SPN" SG_ 2365400318 Joystick10XAxisNeutralPosStatus 4713;
BA_ "SigType" SG_ 2365400318 Joystick10XAxisNeutralPosStatus 4;
BA_ "SPN" SG_ 2499614718 PssngrArbgDctivationSwitchStatus 4962;
BA_ "SigType" SG_ 2499614718 PssngrArbgDctivationSwitchStatus 5;
BA_ "SPN" SG_ 2499614718 Beltlock10Status 4961;
BA_ "SigType" SG_ 2499614718 Beltlock10Status 5;
BA_ "SPN" SG_ 2499614718 Beltlock9Status 4960;
BA_ "SigType" SG_ 2499614718 Beltlock9Status 5;
BA_ "SPN" SG_ 2499614718 Beltlock8Status 4959;
BA_ "SigType" SG_ 2499614718 Beltlock8Status 5;
BA_ "SPN" SG_ 2499614718 Beltlock7Status 4958;
BA_ "SigType" SG_ 2499614718 Beltlock7Status 5;
BA_ "SPN" SG_ 2499614718 Beltlock6Status 4957;
BA_ "SigType" SG_ 2499614718 Beltlock6Status 5;
BA_ "SPN" SG_ 2499614718 Beltlock5Status 4956;
BA_ "SigType" SG_ 2499614718 Beltlock5Status 5;
BA_ "SPN" SG_ 2499614718 Beltlock4Status 4955;
BA_ "SigType" SG_ 2499614718 Beltlock4Status 5;
BA_ "SPN" SG_ 2499614718 Beltlock3Status 4954;
BA_ "SigType" SG_ 2499614718 Beltlock3Status 5;
BA_ "SPN" SG_ 2499614718 PassengerBeltlockStatus 4953;
BA_ "SigType" SG_ 2499614718 PassengerBeltlockStatus 5;
BA_ "SPN" SG_ 2499614718 DriverBeltlockStatus 4952;
BA_ "SigType" SG_ 2499614718 DriverBeltlockStatus 5;
BA_ "SPN" SG_ 2566722814 BatteryCharger2OutputCurrent 4997;
BA_ "SigType" SG_ 2566722814 BatteryCharger2OutputCurrent 1;
BA_ "SPN" SG_ 2566722814 BatteryCharger2OutputVoltage 4996;
BA_ "SigType" SG_ 2566722814 BatteryCharger2OutputVoltage 1;
BA_ "SPN" SG_ 2566722814 BatteryCharger2PowerLineState 4995;
BA_ "SigType" SG_ 2566722814 BatteryCharger2PowerLineState 4;
BA_ "SPN" SG_ 2566722814 BatteryCharger2State 4994;
BA_ "SPN" SG_ 2566723070 BatteryCharger1OutputCurrent 4993;
BA_ "SigType" SG_ 2566723070 BatteryCharger1OutputCurrent 1;
BA_ "SPN" SG_ 2566723070 BatteryCharger1OutputVoltage 4992;
BA_ "SigType" SG_ 2566723070 BatteryCharger1OutputVoltage 1;
BA_ "SPN" SG_ 2566723070 BatteryCharger1PowerLineState 4991;
BA_ "SigType" SG_ 2566723070 BatteryCharger1PowerLineState 4;
BA_ "SPN" SG_ 2566723070 BatteryCharger1State 4990;
BA_ "SPN" SG_ 2566725118 AT2ThreeWayCatalystDiffTemp 4780;
BA_ "SigType" SG_ 2566725118 AT2ThreeWayCatalystDiffTemp 1;
BA_ "SPN" SG_ 2566725118 AT1ThreeWayCatalystDiffTemp 4779;
BA_ "SigType" SG_ 2566725118 AT1ThreeWayCatalystDiffTemp 1;
BA_ "SPN" SG_ 2566725374 AT2GasOxidationCatalystDiffTemp 4778;
BA_ "SigType" SG_ 2566725374 AT2GasOxidationCatalystDiffTemp 1;
BA_ "SPN" SG_ 2566725374 AT1GasOxidationCatalystDiffTemp 4777;
BA_ "SigType" SG_ 2566725374 AT1GasOxidationCatalystDiffTemp 1;
BA_ "SPN" SG_ 2566712830 AT2WrmUpDslOxdtnCtlystOutletTemp 5316;
BA_ "SigType" SG_ 2566712830 AT2WrmUpDslOxdtnCtlystOutletTemp 1;
BA_ "SPN" SG_ 2566712830 AT2WrmUpDslOxdtnCtlystIntakeTemp 5315;
BA_ "SigType" SG_ 2566712830 AT2WrmUpDslOxdtnCtlystIntakeTemp 1;
BA_ "SPN" SG_ 2566735358 AT2ThrWyCtlytcCnvrtrDffPrssPrlmn 4300;
BA_ "SPN" SG_ 2566735358 AT2ThrWyCtlystOtltTmpPrlmnaryFMI 4299;
BA_ "SPN" SG_ 2566735358 AT2ThrWyCtlystIntkTmpPrlmnaryFMI 4298;
BA_ "SPN" SG_ 2566735358 AT2ThreeWayCatalystDiffPress 4297;
BA_ "SigType" SG_ 2566735358 AT2ThreeWayCatalystDiffPress 1;
BA_ "SPN" SG_ 2566735358 AT2ThreeWayCatalystOutletTemp 4296;
BA_ "SigType" SG_ 2566735358 AT2ThreeWayCatalystOutletTemp 1;
BA_ "SPN" SG_ 2566735358 AT2ThreeWayCatalystIntakeTemp 4295;
BA_ "SigType" SG_ 2566735358 AT2ThreeWayCatalystIntakeTemp 1;
BA_ "SPN" SG_ 2365393662 AT2OutletCorrectedNOx 7352;
BA_ "SigType" SG_ 2365393662 AT2OutletCorrectedNOx 1;
BA_ "SPN" SG_ 2365393662 AT2OtltNOxSnsrSlfdgnssFnalResult 5719;
BA_ "SigType" SG_ 2365393662 AT2OtltNOxSnsrSlfdgnssFnalResult 1;
BA_ "SPN" SG_ 2365393662 AT2OutletNOxSensorNH3Correction 5051;
BA_ "SigType" SG_ 2365393662 AT2OutletNOxSensorNH3Correction 1;
BA_ "SPN" SG_ 2365393662 AT2OutletNOxSensorNO2Correction 5050;
BA_ "SigType" SG_ 2365393662 AT2OutletNOxSensorNO2Correction 1;
BA_ "SPN" SG_ 2365393662 AT2OtltNOxSnsrNOxPressCorrection 5049;
BA_ "SigType" SG_ 2365393662 AT2OtltNOxSnsrNOxPressCorrection 1;
BA_ "SPN" SG_ 2365393662 AT2OtltNOxSnsorO2PressCorrection 5048;
BA_ "SigType" SG_ 2365393662 AT2OtltNOxSnsorO2PressCorrection 1;
BA_ "SPN" SG_ 2365393918 AT2OutletNOxSensorOperationHours 5723;
BA_ "SigType" SG_ 2365393918 AT2OutletNOxSensorOperationHours 1;
BA_ "SPN" SG_ 2365393918 AT2OtltNOxSnsrNwPrtDvtnNOxOffset 5047;
BA_ "SigType" SG_ 2365393918 AT2OtltNOxSnsrNwPrtDvtnNOxOffset 1;
BA_ "SPN" SG_ 2365393918 AT2OtltNOxSnsrNwPrtDvtionNOxGain 5046;
BA_ "SigType" SG_ 2365393918 AT2OtltNOxSnsrNwPrtDvtionNOxGain 1;
BA_ "SPN" SG_ 2365393918 AT2OutletNOxSensorHeaterRatio 5045;
BA_ "SigType" SG_ 2365393918 AT2OutletNOxSensorHeaterRatio 1;
BA_ "SPN" SG_ 2365394174 AT2SCRIntakeCorrectedNOx 7354;
BA_ "SigType" SG_ 2365394174 AT2SCRIntakeCorrectedNOx 1;
BA_ "SPN" SG_ 2365394174 AT2IntkNOxSnsrSlfdgnssFnalResult 5720;
BA_ "SigType" SG_ 2365394174 AT2IntkNOxSnsrSlfdgnssFnalResult 1;
BA_ "SPN" SG_ 2365394174 AT2IntakeNOxSensorNH3Correction 5044;
BA_ "SigType" SG_ 2365394174 AT2IntakeNOxSensorNH3Correction 1;
BA_ "SPN" SG_ 2365394174 AT2IntakeNOxSensorNO2Correction 5043;
BA_ "SigType" SG_ 2365394174 AT2IntakeNOxSensorNO2Correction 1;
BA_ "SPN" SG_ 2365394174 AT2IntkNOxSnsrNOxPressCorrection 5042;
BA_ "SigType" SG_ 2365394174 AT2IntkNOxSnsrNOxPressCorrection 1;
BA_ "SPN" SG_ 2365394174 AT2IntkNOxSnsorO2PressCorrection 5041;
BA_ "SigType" SG_ 2365394174 AT2IntkNOxSnsorO2PressCorrection 1;
BA_ "SPN" SG_ 2365394430 AT2IntakeNOxSensorOperationHours 5724;
BA_ "SigType" SG_ 2365394430 AT2IntakeNOxSensorOperationHours 1;
BA_ "SPN" SG_ 2365394430 AT2IntkNOxSnsrNwPrtDvtnNOxOffset 5040;
BA_ "SigType" SG_ 2365394430 AT2IntkNOxSnsrNwPrtDvtnNOxOffset 1;
BA_ "SPN" SG_ 2365394430 AT2IntkNOxSnsrNwPrtDvtionNOxGain 5039;
BA_ "SigType" SG_ 2365394430 AT2IntkNOxSnsrNwPrtDvtionNOxGain 1;
BA_ "SPN" SG_ 2365394430 AT2IntakeNOxSensorHeaterRatio 5038;
BA_ "SigType" SG_ 2365394430 AT2IntakeNOxSensorHeaterRatio 1;
BA_ "SPN" SG_ 2566735102 AT2FuelPress2Ctrl 5428;
BA_ "SigType" SG_ 2566735102 AT2FuelPress2Ctrl 1;
BA_ "SPN" SG_ 2566735102 AT2FuelFlowDiverterValveCtrl 5427;
BA_ "SigType" SG_ 2566735102 AT2FuelFlowDiverterValveCtrl 5;
BA_ "SPN" SG_ 2566735102 AT2FuelPumpRelayCtrl 5426;
BA_ "SigType" SG_ 2566735102 AT2FuelPumpRelayCtrl 5;
BA_ "SPN" SG_ 2566735102 AT2FuelPress2 4303;
BA_ "SigType" SG_ 2566735102 AT2FuelPress2 1;
BA_ "SPN" SG_ 2157313790 AT2DslPrtcltFltrStStndrdDvtnClbO 5498;
BA_ "SigType" SG_ 2157313790 AT2DslPrtcltFltrStStndrdDvtnClbO 1;
BA_ "SPN" SG_ 2157313790 AT2DslPrtcltFltrStManCalibOffset 5497;
BA_ "SigType" SG_ 2157313790 AT2DslPrtcltFltrStManCalibOffset 1;
BA_ "SPN" SG_ 2566724350 AT1WrmUpDslOxdtnCtlystOutletTemp 4810;
BA_ "SigType" SG_ 2566724350 AT1WrmUpDslOxdtnCtlystOutletTemp 1;
BA_ "SPN" SG_ 2566724350 AT1WrmUpDslOxdtnCtlystIntakeTemp 4809;
BA_ "SigType" SG_ 2566724350 AT1WrmUpDslOxdtnCtlystIntakeTemp 1;
VAL_ 2566771966 TransOilLevelRq 3 "Dont care / take no action" 2 "Reserved" 1 "Transmission oil level reading desired" 0 "No transmission oil level reading desired" ;
VAL_ 2566771966 FifthWheelReleaseCtrl 3 "Not Available" 2 "Error" 1 "Coupler Unlocked trailer can be unhitched or hitched" 0 "Coupler Locked" ;
VAL_ 2566771966 FfthWhlRleaseCtrlSecurityLockout 3 "Not Available" 2 "Error" 1 "Fifth wheel release Enabled" 0 "Fifth wheel release Disabled" ;
VAL_ 2566771966 TransferCaseSelectorSwitch 7 "Not available" 6 "Error indicator" 5 "Reserved for SAE assignment" 4 "4 wheel low or Off Highway Range" 2 "Neutral" 1 "4 wheel high Normal or On Highway Range" 0 "2 wheel high Normal or On Highway Range" 3 "2 wheel low or Off Highway Range" ;
VAL_ 2564882174 RqCabZoneHeating 3 "Dont care/take no action" 2 "Reserved" 1 "Heat cab zone" 0 "Do not cab engine zone" ;
VAL_ 2564882174 RqEngZoneHeating 3 "Dont care/take no action" 2 "Reserved" 1 "Heat engine zone" 0 "Do not heat engine zone" ;
VAL_ 2564882174 AuxHeaterModeRq 15 "Don't care/take no action" 14 "Reserved" 4 "Heater pump up-keep" 3 "Normal mode" 2 "Economy mode" 1 "Off due to ADR per European Regulations for Transport of hazardous materials" 0 "De-activate auxiliary heater" ;
VAL_ 2564882174 EngAutomaticStartEnableSwitch 3 "Not available" 2 "Error" 1 "Switch in the on state" 0 "Switch in the off state" ;
VAL_ 2564882174 AtomaticGearShiftingEnableSwitch 3 "Not available" 2 "Error" 1 "Automated Gear Shifting is enabled" 0 "Automated Gear Shifting is disabled" ;
VAL_ 2564882174 ATRegenerationForceSwitch 3 "not available" 2 "error" 1 "active" 0 "not active" ;
VAL_ 2564882174 ATRegenerationInhibitSwitch 3 "not available" 2 "error" 1 "active" 0 "not active" ;
VAL_ 2564882174 VhclLmtngSpdGovernorEnableSwitch 3 "Not available" 2 "Error" 1 "Switched enabled" 0 "Switch disabled" ;
VAL_ 2564882174 VhclLmtngSpdGvrnrIncrementSwitch 3 "Not available" 2 "Error" 1 "Switch in the on state  increase" 0 "Switch in the off state" ;
VAL_ 2564882174 VhclLmtngSpdGvrnrDecrementSwitch 3 "Not available" 2 "Error" 1 "Switch in the on state  decrease" 0 "Switch in the off state" ;
VAL_ 2564882174 ParkBrakeCmd 3 "Dont care/Take no action" 2 "SAE Reserved" 1 "Park Brake apply requested" 0 "Park Brake apply not requested" ;
VAL_ 2564882174 SeatBeltSwitch 3 "Not Available" 2 "Error  Switch state cannot be determined" 1 "OK  Seat Belt is buckled" 0 "NOT Buckled" ;
VAL_ 2564882174 OperatorSeatDirectionSwitch 3 "Not Available" 2 "Error" 1 "Operator seat is facing forward" 0 "Operator seat not facing forward" ;
VAL_ 2564882174 BatteryMainSwitchHoldRq 3 "Dont care/take no action" 2 "undefined" 1 "Hold Battery Main Switch" 0 "Release Battery Main Switch" ;
VAL_ 2564882174 AuxHeaterCoolantPumpRq 3 "Dont care/take no action" 2 "Reserved" 1 "Activate water pump" 0 "Deactivate water pump" ;
VAL_ 2566844926 EngShutdownOverrideSwitch 3 "Not available" 2 "Error" 1 "On" 0 "Off" ;
VAL_ 2566844926 EngTestModeSwitch 3 "Not available" 2 "Error" 1 "On" 0 "Off" ;
VAL_ 2566844926 EngIdleDecrementSwitch 3 "Not available" 2 "Error" 1 "On" 0 "Off" ;
VAL_ 2566844926 EngIdleIncrementSwitch 3 "Not available" 2 "Error" 1 "On" 0 "Off" ;
VAL_ 2566844926 CruiseCtrlStates 7 "Not available" 6 "Accelerator Override" 5 "Set" 4 "Resume" 3 "Decelerate" 2 "Accelerate" 1 "Hold" 0 "Off/Disabled" ;
VAL_ 2566844926 PTOGovernorState 31 "Not available" 19 "PTO set speed memory 2" 18 "PTO set speed memory 1" 17 "Preprogrammed set speed 8" 16 "Preprogrammed set speed 7" 15 "Preprogrammed set speed 6" 14 "Preprogrammed set speed 5" 13 "Preprogrammed set speed 4" 12 "Preprogrammed set speed 3" 11 "Preprogrammed set speed 2" 10 "Preprogrammed set speed 1" 9 "Accelerator Override" 8 "Accelerate" 7 "Resume" 6 "Decelerate/Coast" 5 "Set" 4 "Remote Standby" 3 "Standby" 2 "Remote Hold" 1 "Hold" 0 "Off/Disabled" ;
VAL_ 2566844926 CruiseCtrlAccelerateSwitch 3 "Not available" 2 "Error" 1 "Cruise control activator in position accelerate" 0 "Cruise control activator not in the position accelerate" ;
VAL_ 2566844926 CruiseCtrlResumeSwitch 3 "Not available" 2 "Error" 1 "Cruise control activator in position resume" 0 "Cruise control activator not in the position resume" ;
VAL_ 2566844926 CruiseCtrlCoastSwitch 3 "Not available" 2 "Error" 1 "Cruise control activator in position coast" 0 "Cruise control activator not in the position coast" ;
VAL_ 2566844926 CruiseCtrlSetSwitch 3 "Not available" 2 "Error" 1 "Cruise control activator in position set" 0 "Cruise control activator not in the position set" ;
VAL_ 2566844926 ClutchSwitch 3 "Not available" 2 "Error" 1 "Clutch pedal depressed" 0 "Clutch pedal released" ;
VAL_ 2566844926 BrakeSwitch 3 "Not Available" 2 "Error" 1 "Brake pedal depressed" 0 "Brake pedal released" ;
VAL_ 2566844926 CruiseCtrlEnableSwitch 3 "Not available" 2 "Error" 1 "Cruise control enabled" 0 "Cruise control disabled" ;
VAL_ 2566844926 CruiseCtrlActive 3 "Not available" 2 "Error" 1 "Cruise control switched on" 0 "Cruise control switched off" ;
VAL_ 2566844926 ParkBrakeReleaseInhibitRq 3 "Unavailable" 2 "SAEReserved" 1 "ParkBrakeReleaseInhibitRqed" 0 "ParkBrakeReleaseInhibitNotRqed" ;
VAL_ 2566844926 CruiseCtrlPauseSwitch 3 "Take No Action" 2 "Error Indicator" 1 "On" 0 "Off" ;
VAL_ 2566844926 ParkingBrakeSwitch 3 "Not available" 2 "Error" 1 "Parking brake set" 0 "Parking brake not set" ;
VAL_ 2566844926 TwoSpeedAxleSwitch 3 "Not available" 2 "Error" 1 "High speed range" 0 "Low speed range" ;
VAL_ 2566719486 VhclAccelerationRateLimitLampCmd 3 "Not available" 2 "Reserved" 1 "Lamp On" 0 "Lamp Off" ;
VAL_ 2566719486 EngSpeedVeryHighLampCmd 3 "Not available" 2 "Reserved" 1 "Lamp On" 0 "Lamp Off" ;
VAL_ 2566719486 EngSpeedHighLampCmd 3 "Not available" 2 "Reserved" 1 "Lamp On" 0 "Lamp Off" ;
VAL_ 2566719486 EngCtrlModule3ReadyForUseLampCmd 3 "Not available" 2 "Reserved" 1 "Lamp On" 0 "Lamp Off" ;
VAL_ 2566719486 EngCtrlModule2ReadyForUseLampCmd 3 "Not available" 2 "Reserved" 1 "Lamp On" 0 "Lamp Off" ;
VAL_ 2566719486 EngCtrlModule1ReadyForUseLampCmd 3 "Not available" 2 "Reserved" 1 "Lamp On" 0 "Lamp Off" ;
VAL_ 2566719486 EngFuelFilterRestrictedLampCmd 3 "Not available" 2 "Flash 1 hz" 1 "Lamp On" 0 "Lamp Off" ;
VAL_ 2566719486 EngAirFilterRestrictionLampCmd 3 "Not available" 2 "Reserved" 1 "Lamp On" 0 "Lamp Off" ;
VAL_ 2566719486 EngIdleManagementActiveLampCmd 3 "Not available" 2 "Reserved" 1 "Lamp On" 0 "Lamp Off" ;
VAL_ 2566719486 EngCoolantLevelLowLampCmd 3 "Not available" 2 "Reserved" 1 "Lamp On" 0 "Lamp Off" ;
VAL_ 2566719486 EngCoolantTempHighLampCmd 3 "Not available" 2 "Reserved" 1 "Lamp On" 0 "Lamp Off" ;
VAL_ 2566719486 EngOilPressLowLampCmd 3 "Not available" 2 "Reserved" 1 "Lamp On" 0 "Lamp Off" ;
VAL_ 2566719486 CmprssnBrkEnblSwtchIndctrLampCmd 3 "Not available" 2 "Reserved" 1 "Lamp ON" 0 "Lamp OFF" ;
VAL_ 2566719486 EngBrakeActiveLampCmd 3 "Not available" 2 "Reserved" 1 "Lamp On" 0 "Lamp Off" ;
VAL_ 2566719486 OBDMalfunctionIndicatorLampCmd 3 "Not available" 2 "Reserved" 1 "Lamp On" 0 "Lamp Off" ;
VAL_ 2566719486 EngRedStopLampCmd 3 "Not available" 2 "Reserved" 1 "Lamp On" 0 "Lamp Off" ;
VAL_ 2566719486 EngAmberWarningLampCmd 3 "Not available" 2 "Reserved" 1 "Lamp On" 0 "Lamp Off" ;
VAL_ 2566719486 EngProtectLampCmd 3 "Not available" 2 "Reserved" 1 "Lamp On" 0 "Lamp Off" ;
VAL_ 2633832702 RolloverSensorType 15 "not available" 14 "Error  Type of sensor cannot be determined unknown sensor" 7 "optical sensor" 6 "lidar sensor" 5 "radar sensor" 4 "fiberoptic sensor" 3 "sonic sensor" 2 "rollrate sensor" 1 "pressure sensor" 0 "acceleration sensor" ;
VAL_ 2633832702 RearCollisionSensor4Type 15 "not available" 14 "Error  Type of sensor cannot be determined unknown sensor" 7 "optical sensor" 6 "lidar sensor" 5 "radar sensor" 4 "fiberoptic sensor" 3 "sonic sensor" 2 "rollrate sensor" 1 "pressure sensor" 0 "acceleration sensor" ;
VAL_ 2633832702 RearCollisionSensor3Type 15 "not available" 14 "Error  Type of sensor cannot be determined unknown sensor" 7 "optical sensor" 6 "lidar sensor" 5 "radar sensor" 4 "fiberoptic sensor" 3 "sonic sensor" 2 "rollrate sensor" 1 "pressure sensor" 0 "acceleration sensor" ;
VAL_ 2633832702 RearCollisionSensor2Type 15 "not available" 14 "Error  Type of sensor cannot be determined unknown sensor" 7 "optical sensor" 6 "lidar sensor" 5 "radar sensor" 4 "fiberoptic sensor" 3 "sonic sensor" 2 "rollrate sensor" 1 "pressure sensor" 0 "acceleration sensor" ;
VAL_ 2633832702 RearCollisionSensor1Type 15 "not available" 14 "Error  Type of sensor cannot be determined unknown sensor" 7 "optical sensor" 6 "lidar sensor" 5 "radar sensor" 4 "fiberoptic sensor" 3 "sonic sensor" 2 "rollrate sensor" 1 "pressure sensor" 0 "acceleration sensor" ;
VAL_ 2633832702 SideCollisionSensorRearRightType 15 "not available" 14 "Error  Type of sensor cannot be determined unknown sensor" 7 "optical sensor" 6 "lidar sensor" 5 "radar sensor" 4 "fiberoptic sensor" 3 "sonic sensor" 2 "rollrate sensor" 1 "pressure sensor" 0 "acceleration sensor" ;
VAL_ 2633832702 SdCllisionSensorMidRearRightType 15 "not available" 14 "Error  Type of sensor cannot be determined unknown sensor" 7 "optical sensor" 6 "lidar sensor" 5 "radar sensor" 4 "fiberoptic sensor" 3 "sonic sensor" 2 "rollrate sensor" 1 "pressure sensor" 0 "acceleration sensor" ;
VAL_ 2633832702 SdCllsionSensorMidFrontRightType 15 "not available" 14 "Error  Type of sensor cannot be determined unknown sensor" 7 "optical sensor" 6 "lidar sensor" 5 "radar sensor" 4 "fiberoptic sensor" 3 "sonic sensor" 2 "rollrate sensor" 1 "pressure sensor" 0 "acceleration sensor" ;
VAL_ 2633832702 SdeCollisionSensorFrontRightType 15 "not available" 14 "Error  Type of sensor cannot be determined unknown sensor" 7 "optical sensor" 6 "lidar sensor" 5 "radar sensor" 4 "fiberoptic sensor" 3 "sonic sensor" 2 "rollrate sensor" 1 "pressure sensor" 0 "acceleration sensor" ;
VAL_ 2633832702 SideCollisionSensorRearLeftType 15 "not available" 14 "Error  Type of sensor cannot be determined unknown sensor" 7 "optical sensor" 6 "lidar sensor" 5 "radar sensor" 4 "fiberoptic sensor" 3 "sonic sensor" 2 "rollrate sensor" 1 "pressure sensor" 0 "acceleration sensor" ;
VAL_ 2633832702 SdCollisionSensorMidRearLeftType 15 "not available" 14 "Error  Type of sensor cannot be determined unknown sensor" 7 "optical sensor" 6 "lidar sensor" 5 "radar sensor" 4 "fiberoptic sensor" 3 "sonic sensor" 2 "rollrate sensor" 1 "pressure sensor" 0 "acceleration sensor" ;
VAL_ 2633832702 SdCllisionSensorMidFrontLeftType 15 "not available" 14 "Error  Type of sensor cannot be determined unknown sensor" 7 "optical sensor" 6 "lidar sensor" 5 "radar sensor" 4 "fiberoptic sensor" 3 "sonic sensor" 2 "rollrate sensor" 1 "pressure sensor" 0 "acceleration sensor" ;
VAL_ 2633832702 SideCollisionSensorFrontLeftType 15 "not available" 14 "Error  Type of sensor cannot be determined unknown sensor" 7 "optical sensor" 6 "lidar sensor" 5 "radar sensor" 4 "fiberoptic sensor" 3 "sonic sensor" 2 "rollrate sensor" 1 "pressure sensor" 0 "acceleration sensor" ;
VAL_ 2633832702 FrontalCollisionSensor4Type 15 "not available" 14 "Error  Type of sensor cannot be determined unknown sensor" 7 "optical sensor" 6 "lidar sensor" 5 "radar sensor" 4 "fiberoptic sensor" 3 "sonic sensor" 2 "rollrate sensor" 1 "pressure sensor" 0 "acceleration sensor" ;
VAL_ 2633832702 FrontalCollisionSensor3Type 15 "not available" 14 "Error  Type of sensor cannot be determined unknown sensor" 7 "optical sensor" 6 "lidar sensor" 5 "radar sensor" 4 "fiberoptic sensor" 3 "sonic sensor" 2 "rollrate sensor" 1 "pressure sensor" 0 "acceleration sensor" ;
VAL_ 2633832702 FrontalCollisionSensor2Type 15 "not available" 14 "Error  Type of sensor cannot be determined unknown sensor" 7 "optical sensor" 6 "lidar sensor" 5 "radar sensor" 4 "fiberoptic sensor" 3 "sonic sensor" 2 "rollrate sensor" 1 "pressure sensor" 0 "acceleration sensor" ;
VAL_ 2633832702 FrontalCollisionSensor1Type 15 "not available" 14 "Error  Type of sensor cannot be determined unknown sensor" 7 "optical sensor" 6 "lidar sensor" 5 "radar sensor" 4 "fiberoptic sensor" 3 "sonic sensor" 2 "rollrate sensor" 1 "pressure sensor" 0 "acceleration sensor" ;
VAL_ 2163223550 CrashType 4 "side crash left" 16 "rollover" 8 "side crash right" 2 "rear crash" 1 "frontal crash" ;
VAL_ 2365400830 Joystick9Button9PressedStatus 3 "Not Available" 2 "Error Indicator" 1 "Button pressed" 0 "Button not pressed" ;
VAL_ 2365400830 Joystick9Button10PressedStatus 3 "Not Available" 2 "Error Indicator" 1 "Button pressed" 0 "Button not pressed" ;
VAL_ 2365400830 Joystick9Button11PressedStatus 3 "Not Available" 2 "Error Indicator" 1 "Button pressed" 0 "Button not pressed" ;
VAL_ 2365400830 Joystick9Button12PressedStatus 3 "Not Available" 2 "Error Indicator" 1 "Button pressed" 0 "Button not pressed" ;
VAL_ 2365400830 Joystick9Button5PressedStatus 3 "Not Available" 2 "Error Indicator" 1 "Button pressed" 0 "Button not pressed" ;
VAL_ 2365400830 Joystick9Button6PressedStatus 3 "Not Available" 2 "Error Indicator" 1 "Button pressed" 0 "Button not pressed" ;
VAL_ 2365400830 Joystick9Button7PressedStatus 3 "Not Available" 2 "Error Indicator" 1 "Button pressed" 0 "Button not pressed" ;
VAL_ 2365400830 Joystick9Button8PressedStatus 3 "Not Available" 2 "Error Indicator" 1 "Button pressed" 0 "Button not pressed" ;
VAL_ 2365400830 Joystick9Button1PressedStatus 3 "Not Available" 2 "Error Indicator" 1 "Button pressed" 0 "Button not pressed" ;
VAL_ 2365400830 Joystick9Button2PressedStatus 3 "Not Available" 2 "Error Indicator" 1 "Button pressed" 0 "Button not pressed" ;
VAL_ 2365400830 Joystick9Button3PressedStatus 3 "Not Available" 2 "Error Indicator" 1 "Button pressed" 0 "Button not pressed" ;
VAL_ 2365400830 Joystick9Button4PressedStatus 3 "Not Available" 2 "Error Indicator" 1 "Button pressed" 0 "Button not pressed" ;
VAL_ 2365400830 Joystick9XAxisDetentPosStatus 3 "Not Available" 2 "Error Indicator" 1 "In the Detent Position" 0 "Not in the Detent Position" ;
VAL_ 2365400830 Joystick9YAxisDetentPosStatus 3 "Not Available" 2 "Error Indicator" 1 "In the Detent Position" 0 "Not in the Detent Position" ;
VAL_ 2365400830 Jystck9YAxsLvrFrwrdPstvPosStatus 3 "Not Available" 2 "Error Indicator" 1 "On positive side of Neutral" 0 "Not on Positive side of Neutral" ;
VAL_ 2365400830 Jystck9YAxsLvrBckNgtivePosStatus 3 "Not Available" 2 "Error Indicator" 1 "On negative side of Neutral" 0 "Not on negative side of Neutral" ;
VAL_ 2365400830 Joystick9YAxisNeutralPosStatus 3 "Not Available" 2 "Error Indicator" 1 "In Neutral Position" 0 "Not in Neutral Position" ;
VAL_ 2365400830 Jystck9XAxsLvrRghtPstvePosStatus 3 "Not Available" 2 "Error Indicator" 1 "On positive side of Neutral" 0 "Not on Positive side of Neutral" ;
VAL_ 2365400830 Jystck9XAxsLvrLftNgtivePosStatus 3 "Not Available" 2 "Error Indicator" 1 "On negative side of Neutral" 0 "Not on negative side of Neutral" ;
VAL_ 2365400830 Joystick9XAxisNeutralPosStatus 3 "Not Available" 2 "Error Indicator" 1 "In Neutral Position" 0 "Not in Neutral Position" ;
VAL_ 2365401342 Joystick8Button9PressedStatus 3 "Not Available" 2 "Error Indicator" 1 "Button pressed" 0 "Button not pressed" ;
VAL_ 2365401342 Joystick8Button10PressedStatus 3 "Not Available" 2 "Error Indicator" 1 "Button pressed" 0 "Button not pressed" ;
VAL_ 2365401342 Joystick8Button11PressedStatus 3 "Not Available" 2 "Error Indicator" 1 "Button pressed" 0 "Button not pressed" ;
VAL_ 2365401342 Joystick8Button12PressedStatus 3 "Not Available" 2 "Error Indicator" 1 "Button pressed" 0 "Button not pressed" ;
VAL_ 2365401342 Joystick8Button5PressedStatus 3 "Not Available" 2 "Error Indicator" 1 "Button pressed" 0 "Button not pressed" ;
VAL_ 2365401342 Joystick8Button6PressedStatus 3 "Not Available" 2 "Error Indicator" 1 "Button pressed" 0 "Button not pressed" ;
VAL_ 2365401342 Joystick8Button7PressedStatus 3 "Not Available" 2 "Error Indicator" 1 "Button pressed" 0 "Button not pressed" ;
VAL_ 2365401342 Joystick8Button8PressedStatus 3 "Not Available" 2 "Error Indicator" 1 "Button pressed" 0 "Button not pressed" ;
VAL_ 2365401342 Joystick8Button1PressedStatus 3 "Not Available" 2 "Error Indicator" 1 "Button pressed" 0 "Button not pressed" ;
VAL_ 2365401342 Joystick8Button2PressedStatus 3 "Not Available" 2 "Error Indicator" 1 "Button pressed" 0 "Button not pressed" ;
VAL_ 2365401342 Joystick8Button3PressedStatus 3 "Not Available" 2 "Error Indicator" 1 "Button pressed" 0 "Button not pressed" ;
VAL_ 2365401342 Joystick8Button4PressedStatus 3 "Not Available" 2 "Error Indicator" 1 "Button pressed" 0 "Button not pressed" ;
VAL_ 2365401342 Joystick8XAxisDetentPosStatus 3 "Not Available" 2 "Error Indicator" 1 "In the Detent Position" 0 "Not in the Detent Position" ;
VAL_ 2365401342 Joystick8YAxisDetentPosStatus 3 "Not Available" 2 "Error Indicator" 1 "In the Detent Position" 0 "Not in the Detent Position" ;
VAL_ 2365401342 Jystck8YAxsLvrFrwrdPstvPosStatus 3 "Not Available" 2 "Error Indicator" 1 "On positive side of Neutral" 0 "Not on Positive side of Neutral" ;
VAL_ 2365401342 Jystck8YAxsLvrBckNgtivePosStatus 3 "Not Available" 2 "Error Indicator" 1 "On negative side of Neutral" 0 "Not on negative side of Neutral" ;
VAL_ 2365401342 Joystick8YAxisNeutralPosStatus 3 "Not Available" 2 "Error Indicator" 1 "In Neutral Position" 0 "Not in Neutral Position" ;
VAL_ 2365401342 Jystck8XAxsLvrRghtPstvePosStatus 3 "Not Available" 2 "Error Indicator" 1 "On positive side of Neutral" 0 "Not on Positive side of Neutral" ;
VAL_ 2365401342 Jystck8XAxsLvrLftNgtivePosStatus 3 "Not Available" 2 "Error Indicator" 1 "On negative side of Neutral" 0 "Not on negative side of Neutral" ;
VAL_ 2365401342 Joystick8XAxisNeutralPosStatus 3 "Not Available" 2 "Error Indicator" 1 "In Neutral Position" 0 "Not in Neutral Position" ;
VAL_ 2365401854 Joystick7Button9PressedStatus 3 "Not Available" 2 "Error Indicator" 1 "Button pressed" 0 "Button not pressed" ;
VAL_ 2365401854 Joystick7Button10PressedStatus 3 "Not Available" 2 "Error Indicator" 1 "Button pressed" 0 "Button not pressed" ;
VAL_ 2365401854 Joystick7Button11PressedStatus 3 "Not Available" 2 "Error Indicator" 1 "Button pressed" 0 "Button not pressed" ;
VAL_ 2365401854 Joystick7Button12PressedStatus 3 "Not Available" 2 "Error Indicator" 1 "Button pressed" 0 "Button not pressed" ;
VAL_ 2365401854 Joystick7Button5PressedStatus 3 "Not Available" 2 "Error Indicator" 1 "Button pressed" 0 "Button not pressed" ;
VAL_ 2365401854 Joystick7Button6PressedStatus 3 "Not Available" 2 "Error Indicator" 1 "Button pressed" 0 "Button not pressed" ;
VAL_ 2365401854 Joystick7Button7PressedStatus 3 "Not Available" 2 "Error Indicator" 1 "Button pressed" 0 "Button not pressed" ;
VAL_ 2365401854 Joystick7Button8PressedStatus 3 "Not Available" 2 "Error Indicator" 1 "Button pressed" 0 "Button not pressed" ;
VAL_ 2365401854 Joystick7Button1PressedStatus 3 "Not Available" 2 "Error Indicator" 1 "Button pressed" 0 "Button not pressed" ;
VAL_ 2365401854 Joystick7Button2PressedStatus 3 "Not Available" 2 "Error Indicator" 1 "Button pressed" 0 "Button not pressed" ;
VAL_ 2365401854 Joystick7Button3PressedStatus 3 "Not Available" 2 "Error Indicator" 1 "Button pressed" 0 "Button not pressed" ;
VAL_ 2365401854 Joystick7Button4PressedStatus 3 "Not Available" 2 "Error Indicator" 1 "Button pressed" 0 "Button not pressed" ;
VAL_ 2365401854 Joystick7XAxisDetentPosStatus 3 "Not Available" 2 "Error Indicator" 1 "In the Detent Position" 0 "Not in the Detent Position" ;
VAL_ 2365401854 Joystick7YAxisDetentPosStatus 3 "Not Available" 2 "Error Indicator" 1 "In the Detent Position" 0 "Not in the Detent Position" ;
VAL_ 2365401854 Jystck7YAxsLvrFrwrdPstvPosStatus 3 "Not Available" 2 "Error Indicator" 1 "On positive side of Neutral" 0 "Not on Positive side of Neutral" ;
VAL_ 2365401854 Jystck7YAxsLvrBckNgtivePosStatus 3 "Not Available" 2 "Error Indicator" 1 "On negative side of Neutral" 0 "Not on negative side of Neutral" ;
VAL_ 2365401854 Joystick7YAxisNeutralPosStatus 3 "Not Available" 2 "Error Indicator" 1 "In Neutral Position" 0 "Not in Neutral Position" ;
VAL_ 2365401854 Jystck7XAxsLvrRghtPstvePosStatus 3 "Not Available" 2 "Error Indicator" 1 "On positive side of Neutral" 0 "Not on Positive side of Neutral" ;
VAL_ 2365401854 Jystck7XAxsLvrLftNgtivePosStatus 3 "Not Available" 2 "Error Indicator" 1 "On negative side of Neutral" 0 "Not on negative side of Neutral" ;
VAL_ 2365401854 Joystick7XAxisNeutralPosStatus 3 "Not Available" 2 "Error Indicator" 1 "In Neutral Position" 0 "Not in Neutral Position" ;
VAL_ 2365402366 Joystick6Button9PressedStatus 3 "Not Available" 2 "Error Indicator" 1 "Button pressed" 0 "Button not pressed" ;
VAL_ 2365402366 Joystick6Button10PressedStatus 3 "Not Available" 2 "Error Indicator" 1 "Button pressed" 0 "Button not pressed" ;
VAL_ 2365402366 Joystick6Button11PressedStatus 3 "Not Available" 2 "Error Indicator" 1 "Button pressed" 0 "Button not pressed" ;
VAL_ 2365402366 Joystick6Button12PressedStatus 3 "Not Available" 2 "Error Indicator" 1 "Button pressed" 0 "Button not pressed" ;
VAL_ 2365402366 Joystick6Button5PressedStatus 3 "Not Available" 2 "Error Indicator" 1 "Button pressed" 0 "Button not pressed" ;
VAL_ 2365402366 Joystick6Button6PressedStatus 3 "Not Available" 2 "Error Indicator" 1 "Button pressed" 0 "Button not pressed" ;
VAL_ 2365402366 Joystick6Button7PressedStatus 3 "Not Available" 2 "Error Indicator" 1 "Button pressed" 0 "Button not pressed" ;
VAL_ 2365402366 Joystick6Button8PressedStatus 3 "Not Available" 2 "Error Indicator" 1 "Button pressed" 0 "Button not pressed" ;
VAL_ 2365402366 Joystick6Button1PressedStatus 3 "Not Available" 2 "Error Indicator" 1 "Button pressed" 0 "Button not pressed" ;
VAL_ 2365402366 Joystick6Button2PressedStatus 3 "Not Available" 2 "Error Indicator" 1 "Button pressed" 0 "Button not pressed" ;
VAL_ 2365402366 Joystick6Button3PressedStatus 3 "Not Available" 2 "Error Indicator" 1 "Button pressed" 0 "Button not pressed" ;
VAL_ 2365402366 Joystick6Button4PressedStatus 3 "Not Available" 2 "Error Indicator" 1 "Button pressed" 0 "Button not pressed" ;
VAL_ 2365402366 Joystick6XAxisDetentPosStatus 3 "Not Available" 2 "Error Indicator" 1 "In the Detent Position" 0 "Not in the Detent Position" ;
VAL_ 2365402366 Joystick6YAxisDetentPosStatus 3 "Not Available" 2 "Error Indicator" 1 "In the Detent Position" 0 "Not in the Detent Position" ;
VAL_ 2365402366 Jystck6YAxsLvrFrwrdPstvPosStatus 3 "Not Available" 2 "Error Indicator" 1 "On positive side of Neutral" 0 "Not on Positive side of Neutral" ;
VAL_ 2365402366 Jystck6YAxsLvrBckNgtivePosStatus 3 "Not Available" 2 "Error Indicator" 1 "On negative side of Neutral" 0 "Not on negative side of Neutral" ;
VAL_ 2365402366 Joystick6YAxisNeutralPosStatus 3 "Not Available" 2 "Error Indicator" 1 "In Neutral Position" 0 "Not in Neutral Position" ;
VAL_ 2365402366 Jystck6XAxsLvrRghtPstvePosStatus 3 "Not Available" 2 "Error Indicator" 1 "On positive side of Neutral" 0 "Not on Positive side of Neutral" ;
VAL_ 2365402366 Jystck6XAxsLvrLftNgtivePosStatus 3 "Not Available" 2 "Error Indicator" 1 "On negative side of Neutral" 0 "Not on negative side of Neutral" ;
VAL_ 2365402366 Joystick6XAxisNeutralPosStatus 3 "Not Available" 2 "Error Indicator" 1 "In Neutral Position" 0 "Not in Neutral Position" ;
VAL_ 2365402878 Joystick5Button9PressedStatus 3 "Not Available" 2 "Error Indicator" 1 "Button pressed" 0 "Button not pressed" ;
VAL_ 2365402878 Joystick5Button10PressedStatus 3 "Not Available" 2 "Error Indicator" 1 "Button pressed" 0 "Button not pressed" ;
VAL_ 2365402878 Joystick5Button11PressedStatus 3 "Not Available" 2 "Error Indicator" 1 "Button pressed" 0 "Button not pressed" ;
VAL_ 2365402878 Joystick5Button12PressedStatus 3 "Not Available" 2 "Error Indicator" 1 "Button pressed" 0 "Button not pressed" ;
VAL_ 2365402878 Joystick5Button5PressedStatus 3 "Not Available" 2 "Error Indicator" 1 "Button pressed" 0 "Button not pressed" ;
VAL_ 2365402878 Joystick5Button6PressedStatus 3 "Not Available" 2 "Error Indicator" 1 "Button pressed" 0 "Button not pressed" ;
VAL_ 2365402878 Joystick5Button7PressedStatus 3 "Not Available" 2 "Error Indicator" 1 "Button pressed" 0 "Button not pressed" ;
VAL_ 2365402878 Joystick5Button8PressedStatus 3 "Not Available" 2 "Error Indicator" 1 "Button pressed" 0 "Button not pressed" ;
VAL_ 2365402878 Joystick5Button1PressedStatus 3 "Not Available" 2 "Error Indicator" 1 "Button pressed" 0 "Button not pressed" ;
VAL_ 2365402878 Joystick5Button2PressedStatus 3 "Not Available" 2 "Error Indicator" 1 "Button pressed" 0 "Button not pressed" ;
VAL_ 2365402878 Joystick5Button3PressedStatus 3 "Not Available" 2 "Error Indicator" 1 "Button pressed" 0 "Button not pressed" ;
VAL_ 2365402878 Joystick5Button4PressedStatus 3 "Not Available" 2 "Error Indicator" 1 "Button pressed" 0 "Button not pressed" ;
VAL_ 2365402878 Joystick5XAxisDetentPosStatus 3 "Not Available" 2 "Error Indicator" 1 "In the Detent Position" 0 "Not in the Detent Position" ;
VAL_ 2365402878 Joystick5YAxisDetentPosStatus 3 "Not Available" 2 "Error Indicator" 1 "In the Detent Position" 0 "Not in the Detent Position" ;
VAL_ 2365402878 Jystck5YAxsLvrFrwrdPstvPosStatus 3 "Not Available" 2 "Error Indicator" 1 "On positive side of Neutral" 0 "Not on Positive side of Neutral" ;
VAL_ 2365402878 Jystck5YAxsLvrBckNgtivePosStatus 3 "Not Available" 2 "Error Indicator" 1 "On negative side of Neutral" 0 "Not on negative side of Neutral" ;
VAL_ 2365402878 Joystick5YAxisNeutralPosStatus 3 "Not Available" 2 "Error Indicator" 1 "In Neutral Position" 0 "Not in Neutral Position" ;
VAL_ 2365402878 Jystck5XAxsLvrRghtPstvePosStatus 3 "Not Available" 2 "Error Indicator" 1 "On positive side of Neutral" 0 "Not on Positive side of Neutral" ;
VAL_ 2365402878 Jystck5XAxsLvrLftNgtivePosStatus 3 "Not Available" 2 "Error Indicator" 1 "On negative side of Neutral" 0 "Not on negative side of Neutral" ;
VAL_ 2365402878 Joystick5XAxisNeutralPosStatus 3 "Not Available" 2 "Error Indicator" 1 "In Neutral Position" 0 "Not in Neutral Position" ;
VAL_ 2365403390 Joystick4Button9PressedStatus 3 "Not Available" 2 "Error Indicator" 1 "Button pressed" 0 "Button not pressed" ;
VAL_ 2365403390 Joystick4Button10PressedStatus 3 "Not Available" 2 "Error Indicator" 1 "Button pressed" 0 "Button not pressed" ;
VAL_ 2365403390 Joystick4Button11PressedStatus 3 "Not Available" 2 "Error Indicator" 1 "Button pressed" 0 "Button not pressed" ;
VAL_ 2365403390 Joystick4Button12PressedStatus 3 "Not Available" 2 "Error Indicator" 1 "Button pressed" 0 "Button not pressed" ;
VAL_ 2365403390 Joystick4Button5PressedStatus 3 "Not Available" 2 "Error Indicator" 1 "Button pressed" 0 "Button not pressed" ;
VAL_ 2365403390 Joystick4Button6PressedStatus 3 "Not Available" 2 "Error Indicator" 1 "Button pressed" 0 "Button not pressed" ;
VAL_ 2365403390 Joystick4Button7PressedStatus 3 "Not Available" 2 "Error Indicator" 1 "Button pressed" 0 "Button not pressed" ;
VAL_ 2365403390 Joystick4Button8PressedStatus 3 "Not Available" 2 "Error Indicator" 1 "Button pressed" 0 "Button not pressed" ;
VAL_ 2365403390 Joystick4Button1PressedStatus 3 "Not Available" 2 "Error Indicator" 1 "Button pressed" 0 "Button not pressed" ;
VAL_ 2365403390 Joystick4Button2PressedStatus 3 "Not Available" 2 "Error Indicator" 1 "Button pressed" 0 "Button not pressed" ;
VAL_ 2365403390 Joystick4Button3PressedStatus 3 "Not Available" 2 "Error Indicator" 1 "Button pressed" 0 "Button not pressed" ;
VAL_ 2365403390 Joystick4Button4PressedStatus 3 "Not Available" 2 "Error Indicator" 1 "Button pressed" 0 "Button not pressed" ;
VAL_ 2365403390 Joystick4XAxisDetentPosStatus 3 "Not Available" 2 "Error Indicator" 1 "In the Detent Position" 0 "Not in the Detent Position" ;
VAL_ 2365403390 Joystick4YAxisDetentPosStatus 3 "Not Available" 2 "Error Indicator" 1 "In the Detent Position" 0 "Not in the Detent Position" ;
VAL_ 2365403390 Jystck4YAxsLvrFrwrdPstvPosStatus 3 "Not Available" 2 "Error Indicator" 1 "On positive side of Neutral" 0 "Not on Positive side of Neutral" ;
VAL_ 2365403390 Jystck4YAxsLvrBckNgtivePosStatus 3 "Not Available" 2 "Error Indicator" 1 "On negative side of Neutral" 0 "Not on negative side of Neutral" ;
VAL_ 2365403390 Joystick4YAxisNeutralPosStatus 3 "Not Available" 2 "Error Indicator" 1 "In Neutral Position" 0 "Not in Neutral Position" ;
VAL_ 2365403390 Jystck4XAxsLvrRghtPstvePosStatus 3 "Not Available" 2 "Error Indicator" 1 "On positive side of Neutral" 0 "Not on Positive side of Neutral" ;
VAL_ 2365403390 Jystck4XAxsLvrLftNgtivePosStatus 3 "Not Available" 2 "Error Indicator" 1 "On negative side of Neutral" 0 "Not on negative side of Neutral" ;
VAL_ 2365403390 Joystick4XAxisNeutralPosStatus 3 "Not Available" 2 "Error Indicator" 1 "In Neutral Position" 0 "Not in Neutral Position" ;
VAL_ 2365400318 Joystick10Button9PressedStatus 3 "Not Available" 2 "Error Indicator" 1 "Button pressed" 0 "Button not pressed" ;
VAL_ 2365400318 Joystick10Button10PressedStatus 3 "Not Available" 2 "Error Indicator" 1 "Button pressed" 0 "Button not pressed" ;
VAL_ 2365400318 Joystick10Button11PressedStatus 3 "Not Available" 2 "Error Indicator" 1 "Button pressed" 0 "Button not pressed" ;
VAL_ 2365400318 Joystick10Button12PressedStatus 3 "Not Available" 2 "Error Indicator" 1 "Button pressed" 0 "Button not pressed" ;
VAL_ 2365400318 Joystick10Button5PressedStatus 3 "Not Available" 2 "Error Indicator" 1 "Button pressed" 0 "Button not pressed" ;
VAL_ 2365400318 Joystick10Button6PressedStatus 3 "Not Available" 2 "Error Indicator" 1 "Button pressed" 0 "Button not pressed" ;
VAL_ 2365400318 Joystick10Button7PressedStatus 3 "Not Available" 2 "Error Indicator" 1 "Button pressed" 0 "Button not pressed" ;
VAL_ 2365400318 Joystick10Button8PressedStatus 3 "Not Available" 2 "Error Indicator" 1 "Button pressed" 0 "Button not pressed" ;
VAL_ 2365400318 Joystick10Button1PressedStatus 3 "Not Available" 2 "Error Indicator" 1 "Button pressed" 0 "Button not pressed" ;
VAL_ 2365400318 Joystick10Button2PressedStatus 3 "Not Available" 2 "Error Indicator" 1 "Button pressed" 0 "Button not pressed" ;
VAL_ 2365400318 Joystick10Button3PressedStatus 3 "Not Available" 2 "Error Indicator" 1 "Button pressed" 0 "Button not pressed" ;
VAL_ 2365400318 Joystick10Button4PressedStatus 3 "Not Available" 2 "Error Indicator" 1 "Button pressed" 0 "Button not pressed" ;
VAL_ 2365400318 Joystick10XAxisDetentPosStatus 3 "Not Available" 2 "Error Indicator" 1 "In the Detent Position" 0 "Not in the Detent Position" ;
VAL_ 2365400318 Joystick10YAxisDetentPosStatus 3 "Not Available" 2 "Error Indicator" 1 "In the Detent Position" 0 "Not in the Detent Position" ;
VAL_ 2365400318 Jystck10YAxsLvrFrwrdPstvPsStatus 3 "Not Available" 2 "Error Indicator" 1 "On positive side of Neutral" 0 "Not on Positive side of Neutral" ;
VAL_ 2365400318 Jystck10YAxsLvrBckNgtvePosStatus 3 "Not Available" 2 "Error Indicator" 1 "On negative side of Neutral" 0 "Not on negative side of Neutral" ;
VAL_ 2365400318 Joystick10YAxisNeutralPosStatus 3 "Not Available" 2 "Error Indicator" 1 "In Neutral Position" 0 "Not in Neutral Position" ;
VAL_ 2365400318 Jystck10XAxsLvrRghtPstvPosStatus 3 "Not Available" 2 "Error Indicator" 1 "On positive side of Neutral" 0 "Not on Positive side of Neutral" ;
VAL_ 2365400318 Jystck10XAxsLvrLftNgtvePosStatus 3 "Not Available" 2 "Error Indicator" 1 "On negative side of Neutral" 0 "Not on negative side of Neutral" ;
VAL_ 2365400318 Joystick10XAxisNeutralPosStatus 3 "Not Available" 2 "Error Indicator" 1 "In Neutral Position" 0 "Not in Neutral Position" ;
VAL_ 2499614718 PssngrArbgDctivationSwitchStatus 3 "not available" 2 "Error  State of deactivation switch cannot be determined" 1 "passenger airbag deactivated" 0 "passenger airbag activated" ;
VAL_ 2499614718 Beltlock10Status 3 "not available" 2 "Error  Beltlock state cannot be determined" 1 "locked" 0 "unlocked" ;
VAL_ 2499614718 Beltlock9Status 3 "not available" 2 "Error  Beltlock state cannot be determined" 1 "locked" 0 "unlocked" ;
VAL_ 2499614718 Beltlock8Status 3 "not available" 2 "Error  Beltlock state cannot be determined" 1 "locked" 0 "unlocked" ;
VAL_ 2499614718 Beltlock7Status 3 "not available" 2 "Error  Beltlock state cannot be determined" 1 "locked" 0 "unlocked" ;
VAL_ 2499614718 Beltlock6Status 3 "not available" 2 "Error  Beltlock state cannot be determined" 1 "locked" 0 "unlocked" ;
VAL_ 2499614718 Beltlock5Status 3 "not available" 2 "Error  Beltlock state cannot be determined" 1 "locked" 0 "unlocked" ;
VAL_ 2499614718 Beltlock4Status 3 "not available" 2 "Error  Beltlock state cannot be determined" 1 "locked" 0 "unlocked" ;
VAL_ 2499614718 Beltlock3Status 3 "not available" 2 "Error  Beltlock state cannot be determined" 1 "locked" 0 "unlocked" ;
VAL_ 2499614718 PassengerBeltlockStatus 3 "not available" 2 "Error  Beltlock state cannot be determined" 1 "locked" 0 "unlocked" ;
VAL_ 2499614718 DriverBeltlockStatus 3 "not available" 2 "Error  Beltlock state cannot be determined" 1 "locked" 0 "unlocked" ;
VAL_ 2566722814 BatteryCharger2PowerLineState 3 "Not available" 2 "Error" 1 "Connected. The power line is connected to the charger." 0 "Disconnected. The power line is disconnected from the charger." ;
VAL_ 2566722814 BatteryCharger2State 15 "Not available." 14 "Charger failure. An error condition due to the charger state." 13 "Battery failure. An error condition due to the battery state (high temperature, etc.)" 2 "Stand-by or maintaining the battery charge." 1 "Charging the battery." 0 "Idling. The power line or the battery is disconnected from the charger." ;
VAL_ 2566723070 BatteryCharger1PowerLineState 3 "Not available" 2 "Error" 1 "Connected. The power line is connected to the charger." 0 "Disconnected. The power line is disconnected from the charger." ;
VAL_ 2566723070 BatteryCharger1State 15 "Not available." 14 "Charger failure. An error condition due to the charger state." 13 "Battery failure. An error condition due to the battery state (high temperature, etc.)" 2 "Stand-by or maintaining the battery charge." 1 "Charging the battery." 0 "Idling. The power line or the battery is disconnected from the charger." ;
VAL_ 2566735102 AT2FuelFlowDiverterValveCtrl 3 "not available" 2 "reserved for SAE assignment" 1 "on" 0 "off" ;
VAL_ 2566735102 AT2FuelPumpRelayCtrl 3 "not available" 2 "reserved for SAE assignment" 1 "on" 0 "off" ;
